VERSION ""

NS_ :

BS_:

BU_: New_Node_2 ADCC_DA_J6P_M32T

BO_ 871 ADS_BNCM_1: 24 ADCC_DA_J6P_M32T
 SG_ ADS_1_CRC1 : 7|8@0+ (1,0) [0|255] "" Vector__XXX
 SG_ ADS_1_RollgCntr1 : 11|4@0+ (1,0) [0|14] "" Vector__XXX
 SG_ ADS_1_Resd1 : 15|4@0+ (1,0) [0|15] "" Vector__XXX
 SG_ ADS_Chanllenge1 : 23|8@0+ (1,0) [0|255] "" Vector__XXX
 SG_ ADS_Chanllenge2 : 31|8@0+ (1,0) [0|255] "" Vector__XXX
 SG_ ADS_ParkingActiveSubFuncSts : 34|3@0+ (1,0) [0|7] "" Vector__XXX
 SG_ ADS_RPAIntFunSts : 35|1@0+ (1,0) [0|1] "" Vector__XXX
 SG_ RPAOutFunSts : 36|1@0+ (1,0) [0|1] "" Vector__XXX
 SG_ RpaStartButSts : 37|1@0+ (1,0) [0|1] "" Vector__XXX
 SG_ ADAS_enum_ApaRpaSts : 43|4@0+ (1,0) [0|15] "" Vector__XXX
 SG_ ADAS_enum_ParkingQuitInd : 54|7@0+ (1,0) [0|127] "" Vector__XXX
 SG_ ADAS_enum_ParkingDriOperateInd : 62|7@0+ (1,0) [0|127] "" Vector__XXX
 SG_ ADS_1_CRC2 : 71|8@0+ (1,0) [0|255] "" Vector__XXX
 SG_ ADS_1_RollgCntr2 : 75|4@0+ (1,0) [0|14] "" Vector__XXX
 SG_ ADS_1_Resd2 : 79|4@0+ (1,0) [0|15] "" Vector__XXX
 SG_ ADAS_enum_ParkingPauseInd : 84|5@0+ (1,0) [0|31] "" Vector__XXX
 SG_ PrkInSts : 85|1@0+ (1,0) [0|1] "" Vector__XXX
 SG_ FrontLeftOutsts : 86|1@0+ (1,0) [0|1] "" Vector__XXX
 SG_ FrontRightOutsts : 87|1@0+ (1,0) [0|1] "" Vector__XXX
 SG_ FrontStrightOutsts : 88|1@0+ (1,0) [0|1] "" Vector__XXX
 SG_ BackLeftOutsts : 89|1@0+ (1,0) [0|1] "" Vector__XXX
 SG_ BackRightOutsts : 90|1@0+ (1,0) [0|1] "" Vector__XXX
 SG_ BackStrightOutsts : 91|1@0+ (1,0) [0|1] "" Vector__XXX
 SG_ FrontLeftParallelOutsts : 92|1@0+ (1,0) [0|1] "" Vector__XXX
 SG_ FrontRightParallelOutsts : 93|1@0+ (1,0) [0|1] "" Vector__XXX
 SG_ ParkingStopDist : 103|10@0+ (0.1,0) [0|102.3] "m" Vector__XXX
 SG_ ParkingCompleteTime : 109|10@0+ (1,0) [0|1023] "s" Vector__XXX
 SG_ ParkOutDirectionSt : 115|4@0+ (1,0) [0|15] "" Vector__XXX
 SG_ ADS_1_CRC3 : 135|8@0+ (1,0) [0|255] "" Vector__XXX
 SG_ ADS_1_RollgCntr3 : 139|4@0+ (1,0) [0|14] "" Vector__XXX
 SG_ ADS_1_Resd3 : 143|4@0+ (1,0) [0|15] "" Vector__XXX
 SG_ ADS_ParkingRemind : 159|3@0+ (1,0) [0|7] "" Vector__XXX
 SG_ HPARPAInFunSts : 151|2@0+ (1,0) [0|3] "" Vector__XXX
 SG_ HPARPAOutFunSts : 155|2@0+ (1,0) [0|3] "" Vector__XXX
 SG_ BAFAFunSts : 153|2@0+ (1,0) [0|3] "" Vector__XXX
 SG_ RpaResumeButSts : 167|2@0+ (1,0) [0|3] "" Vector__XXX
 SG_ ADS_1_BAFAFrontButSts : 165|2@0+ (1,0) [0|3] "" Vector__XXX
 SG_ ADS_1_BAFABacktButSts : 163|2@0+ (1,0) [0|3] "" Vector__XXX
 SG_ ADS_1_SelfCheckSt : 161|2@0+ (1,0) [0|3] "" Vector__XXX
 SG_ ADS_1_RPASet : 175|2@0+ (1,0) [0|3] "" Vector__XXX
 SG_ ADS_1_SlotType : 173|2@0+ (1,0) [0|3] "" Vector__XXX
 SG_ ADS_1_ActivateEcall : 171|2@0+ (1,0) [0|3] "" Vector__XXX
 SG_ ADS_1_ParkingProgressBarInd : 183|7@0+ (1,0) [0|100] "" Vector__XXX

BO_ 901 ADS_ASU_1: 32 ADCC_DA_J6P_M32T
 SG_ ADS_CRC1 : 7|8@0+ (1,0) [0|255] "" Vector__XXX
 SG_ ADS_RollgCntr1 : 11|4@0+ (1,0) [0|14] "" Vector__XXX
 SG_ ADS_Resd1 : 15|4@0+ (1,0) [0|15] "" Vector__XXX
 SG_ ADS_Road_infor_available : 23|1@0+ (1,0) [0|1] "" Vector__XXX
 SG_ ADS_Road_Type : 22|3@0+ (1,0) [0|7] "" Vector__XXX
 SG_ ADS_Rough_Sta_L : 19|2@0+ (1,0) [0|3] "" Vector__XXX
 SG_ ADS_Road_Features_L : 31|4@0+ (1,0) [0|15] "" Vector__XXX
 SG_ ADS_LongitudinalDist_L : 43|12@0+ (0.01,0) [0|30] "m" Vector__XXX
 SG_ ADS_Rough_Sta_R : 17|2@0+ (1,0) [0|3] "" Vector__XXX
 SG_ ADS_Road_Features_R : 27|4@0+ (1,0) [0|15] "" Vector__XXX
 SG_ ADS_LongitudinalDist_R : 39|12@0+ (0.01,0) [0|30] "m" Vector__XXX
 SG_ ADS_CRC2 : 71|8@0+ (1,0) [0|255] "" Vector__XXX
 SG_ ADS_RollgCntr2 : 75|4@0+ (1,0) [0|14] "" Vector__XXX
 SG_ ADS_Resd2 : 79|4@0+ (1,0) [0|15] "" Vector__XXX
 SG_ ADS_FeatureHight_L : 87|10@0+ (0.001,-0.5) [-0.5|0.523] "m" Vector__XXX
 SG_ ADS_FeatureHight_R : 93|10@0+ (0.001,-0.5) [-0.5|0.523] "m" Vector__XXX
 SG_ SpeedBump_0_ID : 99|4@0+ (1,0) [0|15] "" Vector__XXX
 SG_ SpeedBump_0_Valid : 127|1@0+ (1,0) [0|1] "" Vector__XXX
 SG_ SpeedBump_0_Dx : 111|10@0+ (0.1,0) [0|100] "m" Vector__XXX
 SG_ SpeedBump_0_ExistProb : 117|6@0+ (2,0) [0|100] "%" Vector__XXX
 SG_ SpeedBump_1_ID : 126|4@0+ (1,0) [0|15] "" Vector__XXX
 SG_ SpeedBump_1_Valid : 122|1@0+ (1,0) [0|1] "" Vector__XXX
 SG_ ADS_CRC3 : 135|8@0+ (1,0) [0|255] "" Vector__XXX
 SG_ ADS_RollgCntr3 : 139|4@0+ (1,0) [0|14] "" Vector__XXX
 SG_ ADS_Resd3 : 143|4@0+ (1,0) [0|15] "" Vector__XXX
 SG_ SpeedBump_1_Dx : 151|10@0+ (0.1,0) [0|100] "m" Vector__XXX
 SG_ SpeedBump_1_ExistProb : 157|6@0+ (2,0) [0|100] "%" Vector__XXX
 SG_ SpeedBump_2_ID : 167|4@0+ (1,0) [0|15] "" Vector__XXX
 SG_ SpeedBump_2_Valid : 163|1@0+ (1,0) [0|1] "" Vector__XXX
 SG_ SpeedBump_2_Dx : 161|10@0+ (0.1,0) [0|100] "m" Vector__XXX
 SG_ SpeedBump_2_ExistProb : 183|6@0+ (2,0) [0|100] "%" Vector__XXX
 SG_ SpeedBump_3_ID : 191|4@0+ (1,0) [0|15] "" Vector__XXX
 SG_ SpeedBump_3_Valid : 187|1@0+ (1,0) [0|1] "" Vector__XXX
 SG_ ADS_CRC4 : 199|8@0+ (1,0) [0|255] "" Vector__XXX
 SG_ ADS_RollgCntr4 : 203|4@0+ (1,0) [0|14] "" Vector__XXX
 SG_ ADS_Resd4 : 207|4@0+ (1,0) [0|15] "" Vector__XXX
 SG_ SpeedBump_3_Dx : 215|10@0+ (0.1,0) [0|100] "m" Vector__XXX
 SG_ SpeedBump_3_ExistProb : 221|6@0+ (2,0) [0|100] "%" Vector__XXX
 SG_ SpeedBump_4_ID : 231|4@0+ (1,0) [0|15] "" Vector__XXX
 SG_ SpeedBump_4_Valid : 227|1@0+ (1,0) [0|1] "" Vector__XXX
 SG_ SpeedBump_4_Dx : 225|10@0+ (0.1,0) [0|100] "m" Vector__XXX
 SG_ SpeedBump_4_ExistProb : 247|6@0+ (2,0) [0|100] "%" Vector__XXX

BO_ 1301 ADCC_TimeSync: 8 ADCC_DA_J6P_M32T
 SG_ TimeSync_Type M : 7|8@0+ (1,0) [0|255] "" Vector__XXX
 SG_ TimeSync_CRC : 15|8@0+ (1,0) [0|255] "" Vector__XXX
 SG_ TimeSync_SequenceCounter : 19|4@0+ (1,0) [0|15] "" Vector__XXX
 SG_ TimeSync_TimeDomain : 23|4@0+ (1,0) [0|15] "" Vector__XXX
 SG_ TimeSync_UserByte0 m32 : 31|8@0+ (1,0) [0|255] "" Vector__XXX
 SG_ TimeSync_SyncTimeSec m32 : 39|32@0+ (1,0) [0|4294967295] "" Vector__XXX
 SG_ TimeSync_OverflowOfSeconds m40 : 25|2@0+ (1,0) [0|3] "" Vector__XXX
 SG_ TimeSync_SGW m40 : 26|1@0+ (1,0) [0|1] "" Vector__XXX
 SG_ TimeSync_Reserved0 m40 : 31|5@0+ (1,0) [0|31] "" Vector__XXX
 SG_ TimeSync_SyncTimeNSec m40 : 39|32@0+ (1,0) [0|4294967295] "" Vector__XXX

BO_ 783 ADS_COM_1: 8 ADCC_DA_J6P_M32T
 SG_ ADS_1_CRC1 : 7|8@0+ (1,0) [0|255] "" Vector__XXX
 SG_ ADS_1_RollgCntr1 : 11|4@0+ (1,0) [0|14] "" Vector__XXX
 SG_ ADS_1_Resd1 : 15|4@0+ (1,0) [0|15] "" Vector__XXX
 SG_ ADS_1_FunctionSuppressReq : 23|2@0+ (1,0) [0|3] "" Vector__XXX
 SG_ ADS_1_HPASts : 27|4@0+ (1,0) [0|15] "" Vector__XXX
 SG_ ADS_1_VPASts : 31|4@0+ (1,0) [0|15] "" Vector__XXX
 SG_ ADCC_CameraStreamSts : 18|3@0+ (1,0) [0|7] "" Vector__XXX
 SG_ ADCC_CameraErrorCode : 21|3@0+ (1,0) [0|7] "" Vector__XXX
 SG_ ADCC_HWRequest : 32|1@0+ (1,0) [0|1] "" Vector__XXX
 SG_ ADCC_PP_M_Request : 33|1@0+ (1,0) [0|1] "" Vector__XXX
 SG_ ADCC_HighwayZoneState : 39|2@0+ (1,0) [0|3] "" Vector__XXX
 SG_ ADCC_CoolingReq : 42|3@0+ (1,0) [0|7] "" Vector__XXX
 SG_ ADCC_UploadFlag : 34|1@0+ (1,0) [0|1] "" Vector__XXX
 SG_ ADCC_SurroundCameraErrorSts : 55|8@0+ (1,0) [0|255] "" Vector__XXX
 SG_ ADCC_SysReadySts : 43|1@0+ (1,0) [0|1] "" Vector__XXX
 SG_ ADS_1_APARPASts : 47|4@0+ (1,0) [0|15] "" Vector__XXX
 SG_ ADCC_OvertemperatureErrorSts : 63|2@0+ (1,0) [0|3] "" Vector__XXX
 SG_ ADCC_CamFOV_HeatReq : 61|3@0+ (1,0) [0|7] "" Vector__XXX

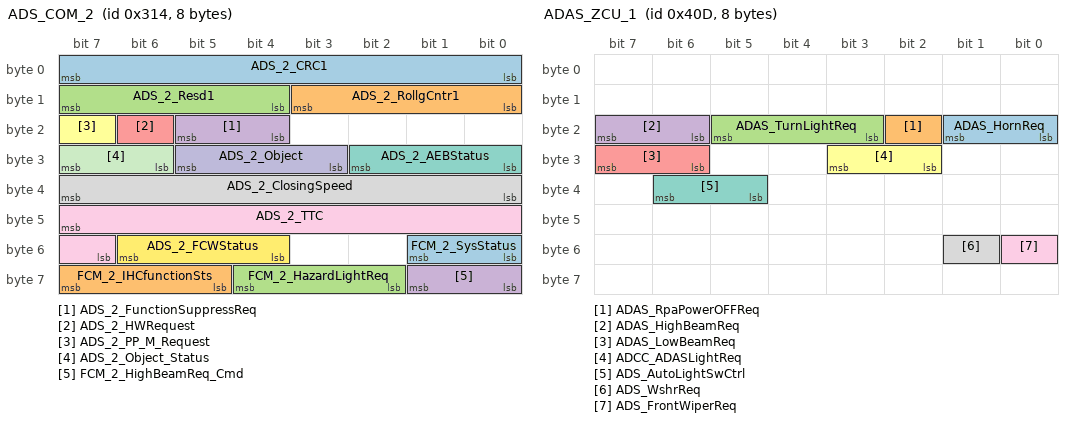
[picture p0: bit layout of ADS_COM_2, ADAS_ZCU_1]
BO_ 788 ADS_COM_2: 8 ADCC_DA_J6P_M32T
 SG_ ADS_2_CRC1 : 7|8@0+ (1,0) [0|255] "" Vector__XXX
 SG_ ADS_2_RollgCntr1 : 11|4@0+ (1,0) [0|14] "" Vector__XXX
 SG_ ADS_2_Resd1 : 15|4@0+ (1,0) [0|15] "" Vector__XXX
 SG_ ADS_2_FunctionSuppressReq : 21|2@0+ (1,0) [0|3] "" Vector__XXX
 SG_ ADS_2_HWRequest : 22|1@0+ (1,0) [0|1] "" Vector__XXX
 SG_ ADS_2_PP_M_Request : 23|1@0+ (1,0) [0|1] "" Vector__XXX
 SG_ ADS_2_AEBStatus : 26|3@0+ (1,0) [0|5] "" Vector__XXX
 SG_ ADS_2_ClosingSpeed : 39|8@0+ (1,0) [0|250] "kph" Vector__XXX
 SG_ ADS_2_TTC : 47|9@0+ (0.01,0) [0|5] "s" Vector__XXX
 SG_ ADS_2_Object : 29|3@0+ (1,0) [0|7] "" Vector__XXX
 SG_ ADS_2_Object_Status : 31|2@0+ (1,0) [0|3] "" Vector__XXX
 SG_ ADS_2_FCWStatus : 54|3@0+ (1,0) [0|7] "" Vector__XXX
 SG_ FCM_2_SysStatus : 49|2@0+ (1,0) [0|3] "" Vector__XXX
 SG_ FCM_2_IHCfunctionSts : 63|3@0+ (1,0) [0|7] "" Vector__XXX
 SG_ FCM_2_HazardLightReq : 60|3@0+ (1,0) [0|7] "" Vector__XXX
 SG_ FCM_2_HighBeamReq_Cmd : 57|2@0+ (1,0) [0|3] "" Vector__XXX

BO_ 794 ADS_COM_3: 24 ADCC_DA_J6P_M32T
 SG_ ADS_3_CRC1 : 7|8@0+ (1,0) [0|255] "" Vector__XXX
 SG_ ADS_3_RollgCntr1 : 11|4@0+ (1,0) [0|14] "" Vector__XXX
 SG_ ADS_3_Resd1 : 15|4@0+ (1,0) [0|15] "" Vector__XXX
 SG_ ADS_3_ICAStatus : 23|3@0+ (1,0) [0|7] "" Vector__XXX
 SG_ ADS_3_ICATextinfo : 19|4@0+ (1,0) [0|15] "" Vector__XXX
 SG_ ADS_3_ACCSts : 31|4@0+ (1,0) [0|15] "" Vector__XXX
 SG_ ADS_3_DriverHandsoffWarning : 27|3@0+ (1,0) [0|7] "" Vector__XXX
 SG_ ADS_3_AESStatus : 39|3@0+ (1,0) [0|7] "" Vector__XXX
 SG_ ADS_3_LKSMod : 36|2@0+ (1,0) [0|3] "" Vector__XXX
 SG_ ADS_3_LKSSts : 34|3@0+ (1,0) [0|7] "" Vector__XXX
 SG_ ADS_3_ELKSts : 47|3@0+ (1,0) [0|7] "" Vector__XXX
 SG_ ADS_3_LKSLeftTrackingSt : 44|2@0+ (1,0) [0|2] "" Vector__XXX
 SG_ ADS_3_LKSRightTrackingSt : 42|2@0+ (1,0) [0|2] "" Vector__XXX
 SG_ ADS_3_ELKLeftActiveSt : 55|2@0+ (1,0) [0|2] "" Vector__XXX
 SG_ ADS_3_ELKRightActiveSt : 53|2@0+ (1,0) [0|2] "" Vector__XXX
 SG_ ADS_3_RearViewFoldReq : 51|2@0+ (1,0) [0|3] "" Vector__XXX
 SG_ ADS_3_CRC2 : 71|8@0+ (1,0) [0|255] "" Vector__XXX
 SG_ ADS_3_RollgCntr2 : 75|4@0+ (1,0) [0|14] "" Vector__XXX
 SG_ ADS_3_Resd2 : 79|4@0+ (1,0) [0|15] "" Vector__XXX
 SG_ ADS_ALCSts : 87|4@0+ (1,0) [0|15] "" Vector__XXX
 SG_ ADS_HNOPSts : 83|4@0+ (1,0) [0|15] "" Vector__XXX
 SG_ ADS_UNOPSts : 95|4@0+ (1,0) [0|15] "" Vector__XXX
 SG_ ADAS_ParkingActiveSubFuncSt : 91|4@0+ (1,0) [0|15] "" Vector__XXX
 SG_ ADS_DoorLockReq : 103|2@0+ (1,0) [0|3] "" Vector__XXX
 SG_ ADASLighSwtSts : 107|2@0+ (1,0) [0|3] "" Vector__XXX
 SG_ ADCCFlowReq : 119|8@0+ (0.1,0) [0|25.5] "L/min" Vector__XXX

BO_ 1037 ADAS_ZCU_1: 8 ADCC_DA_J6P_M32T
 SG_ ADAS_HornReq : 17|2@0+ (1,0) [0|3] "" Vector__XXX
 SG_ ADAS_RpaPowerOFFReq : 18|1@0+ (1,0) [0|1] "" Vector__XXX
 SG_ ADAS_TurnLightReq : 21|3@0+ (1,0) [0|7] "" Vector__XXX
 SG_ ADAS_HighBeamReq : 23|2@0+ (1,0) [0|3] "" Vector__XXX
 SG_ ADAS_LowBeamReq : 31|2@0+ (1,0) [0|3] "" Vector__XXX
 SG_ ADCC_ADASLightReq : 27|2@0+ (1,0) [0|3] "" Vector__XXX
 SG_ ADS_AutoLightSwCtrl : 38|2@0+ (1,0) [0|3] "" Vector__XXX
 SG_ ADS_WshrReq : 49|1@0+ (1,0) [0|1] "" Vector__XXX
 SG_ ADS_FrontWiperReq : 48|1@0+ (1,0) [0|1] "" Vector__XXX

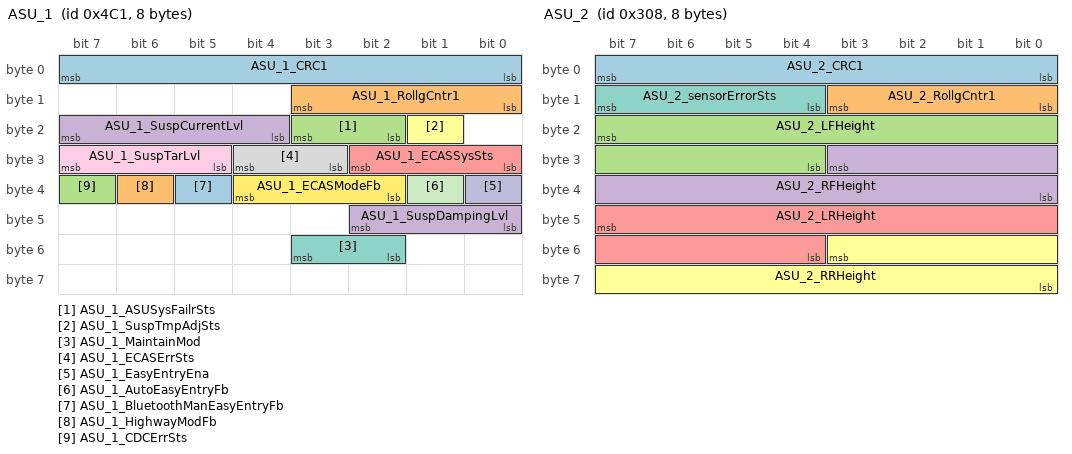
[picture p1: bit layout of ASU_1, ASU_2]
BO_ 1217 ASU_1: 8 Vector__XXX
 SG_ ASU_1_CRC1 : 7|8@0+ (1,0) [0|255] ""  ADCC_DA_J6P_M32T
 SG_ ASU_1_RollgCntr1 : 11|4@0+ (1,0) [0|14] ""  ADCC_DA_J6P_M32T
 SG_ ASU_1_ASUSysFailrSts : 19|2@0+ (1,0) [0|3] ""  ADCC_DA_J6P_M32T
 SG_ ASU_1_SuspCurrentLvl : 23|4@0+ (1,0) [0|15] ""  ADCC_DA_J6P_M32T
 SG_ ASU_1_ECASSysSts : 26|3@0+ (1,0) [0|7] ""  ADCC_DA_J6P_M32T
 SG_ ASU_1_SuspTmpAdjSts : 17|1@0+ (1,0) [0|1] ""  ADCC_DA_J6P_M32T
 SG_ ASU_1_MaintainMod : 51|2@0+ (1,0) [0|3] ""  ADCC_DA_J6P_M32T
 SG_ ASU_1_ECASErrSts : 28|2@0+ (1,0) [0|3] ""  ADCC_DA_J6P_M32T
 SG_ ASU_1_SuspTarLvl : 31|3@0+ (1,0) [0|7] ""  ADCC_DA_J6P_M32T
 SG_ ASU_1_EasyEntryEna : 32|1@0+ (1,0) [0|1] ""  ADCC_DA_J6P_M32T
 SG_ ASU_1_AutoEasyEntryFb : 33|1@0+ (1,0) [0|1] ""  ADCC_DA_J6P_M32T
 SG_ ASU_1_ECASModeFb : 36|3@0+ (1,0) [0|7] ""  ADCC_DA_J6P_M32T
 SG_ ASU_1_BluetoothManEasyEntryFb : 37|1@0+ (1,0) [0|1] ""  ADCC_DA_J6P_M32T
 SG_ ASU_1_HighwayModFb : 38|1@0+ (1,0) [0|1] ""  ADCC_DA_J6P_M32T
 SG_ ASU_1_CDCErrSts : 39|1@0+ (1,0) [0|1] ""  ADCC_DA_J6P_M32T
 SG_ ASU_1_SuspDampingLvl : 42|3@0+ (1,0) [0|7] ""  ADCC_DA_J6P_M32T

BO_ 776 ASU_2: 8 Vector__XXX
 SG_ ASU_2_CRC1 : 7|8@0+ (1,0) [0|255] ""  ADCC_DA_J6P_M32T
 SG_ ASU_2_RollgCntr1 : 11|4@0+ (1,0) [0|14] ""  ADCC_DA_J6P_M32T
 SG_ ASU_2_LFHeight : 23|12@0+ (0.1,-150) [0|259.4] "mm"  ADCC_DA_J6P_M32T
 SG_ ASU_2_RFHeight : 27|12@0+ (0.1,-150) [0|259.4] "mm"  ADCC_DA_J6P_M32T
 SG_ ASU_2_LRHeight : 47|12@0+ (0.1,-150) [0|259.4] "mm"  ADCC_DA_J6P_M32T
 SG_ ASU_2_RRHeight : 51|12@0+ (0.1,-150) [0|259.4] "mm"  ADCC_DA_J6P_M32T
 SG_ ASU_2_sensorErrorSts : 15|4@0+ (1,0) [0|15] ""  ADCC_DA_J6P_M32T

BO_ 1291 BMS_2_G: 8 Vector__XXX
 SG_ BMS_SOCLight : 62|7@0+ (1,0) [0|100] "%"  ADCC_DA_J6P_M32T

BO_ 1295 BMS_3_G: 8 Vector__XXX
 SG_ BMS_ChgWireConnect_LightSts : 32|1@0+ (1,0) [0|1] ""  ADCC_DA_J6P_M32T
 SG_ BMS_Chg_LightSts : 33|1@0+ (1,0) [0|1] ""  ADCC_DA_J6P_M32T

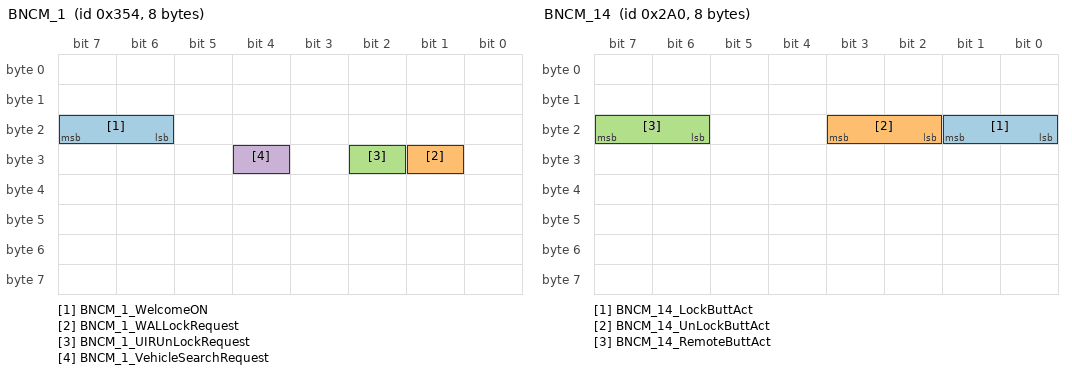
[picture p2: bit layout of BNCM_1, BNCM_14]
BO_ 852 BNCM_1: 8 Vector__XXX
 SG_ BNCM_1_WelcomeON : 23|2@0+ (1,0) [0|3] ""  ADCC_DA_J6P_M32T
 SG_ BNCM_1_WALLockRequest : 25|1@0+ (1,0) [0|1] ""  ADCC_DA_J6P_M32T
 SG_ BNCM_1_UIRUnLockRequest : 26|1@0+ (1,0) [0|1] ""  ADCC_DA_J6P_M32T
 SG_ BNCM_1_VehicleSearchRequest : 28|1@0+ (1,0) [0|1] ""  ADCC_DA_J6P_M32T

BO_ 879 BNCM_4: 16 New_Node_2
 SG_ BNCM_4_CRC1 : 7|8@0+ (1,0) [0|255] ""  ADCC_DA_J6P_M32T
 SG_ BNCM_4_RollgCntr1 : 11|4@0+ (1,0) [0|14] ""  ADCC_DA_J6P_M32T
 SG_ BNCM_4_Resd1 : 15|4@0+ (1,0) [0|15] ""  ADCC_DA_J6P_M32T
 SG_ BNCM_4_ChallengeFeedback : 23|8@0+ (1,0) [0|255] ""  ADCC_DA_J6P_M32T
 SG_ BNCM_4_RpaDevicefailSts : 26|3@0+ (1,0) [0|7] ""  ADCC_DA_J6P_M32T
 SG_ BNCM_4_RpaModReq : 29|1@0+ (1,0) [0|1] ""  ADCC_DA_J6P_M32T
 SG_ BNCM_4_ExitAndPowerOff : 28|2@0+ (1,0) [0|3] ""  ADCC_DA_J6P_M32T
 SG_ BNCM_4_RpaModselect : 34|3@0+ (1,0) [0|7] ""  ADCC_DA_J6P_M32T
 SG_ BNCM_4_RpaBtnSts : 35|1@0+ (1,0) [0|1] ""  ADCC_DA_J6P_M32T
 SG_ BNCM_4_StraightInBtnSts : 36|1@0+ (1,0) [0|1] ""  ADCC_DA_J6P_M32T
 SG_ BNCM_4_StraightOutBtnSts : 37|1@0+ (1,0) [0|1] ""  ADCC_DA_J6P_M32T
 SG_ BNCM_4_RpaBtnCancelSts : 38|1@0+ (1,0) [0|1] ""  ADCC_DA_J6P_M32T
 SG_ BNCM_4_PrkOutModSelRmt : 43|4@0+ (1,0) [0|15] ""  ADCC_DA_J6P_M32T
 SG_ BNCM_4_HeartbeatSignal : 45|1@0+ (1,0) [0|1] ""  ADCC_DA_J6P_M32T
 SG_ BNCM_4_PauseBtn : 47|2@0+ (1,0) [0|3] ""  ADCC_DA_J6P_M32T
 SG_ BNCM_4_ResumeBtn : 63|2@0+ (1,0) [0|3] ""  ADCC_DA_J6P_M32T
 SG_ BNCM_4_RpaDeviceDisSts : 81|2@0+ (1,0) [0|3] ""  ADCC_DA_J6P_M32T
 SG_ BNCM_4_BLEConnSts : 83|2@0+ (1,0) [0|3] ""  ADCC_DA_J6P_M32T
 SG_ BNCM_4_BLEErrStatus : 84|1@0+ (1,0) [0|1] ""  ADCC_DA_J6P_M32T

BO_ 1191 BNCM_6: 8 Vector__XXX
 SG_ BNCM_6_RemoteControl : 4|5@0+ (1,0) [0|31] ""  ADCC_DA_J6P_M32T

BO_ 672 BNCM_14: 8 Vector__XXX
 SG_ BNCM_14_LockButtAct : 17|2@0+ (1,0) [0|3] ""  ADCC_DA_J6P_M32T
 SG_ BNCM_14_UnLockButtAct : 19|2@0+ (1,0) [0|3] ""  ADCC_DA_J6P_M32T
 SG_ BNCM_14_RemoteButtAct : 23|2@0+ (1,0) [0|3] ""  ADCC_DA_J6P_M32T

BO_ 1143 CDU_2: 8 Vector__XXX
 SG_ DCDC_WorkingMode : 31|4@0+ (1,0) [0|15] ""  ADCC_DA_J6P_M32T
 SG_ OBC_CC_ConnectSts : 27|3@0+ (1,0) [0|7] ""  ADCC_DA_J6P_M32T

BO_ 1172 TMS_1: 8 Vector__XXX
 SG_ ExternalTemperature_C : 39|8@0+ (0.5,-40) [-40|85] "°C"  ADCC_DA_J6P_M32T
 SG_ ExternalTemperatureFailSts : 40|1@0+ (1,0) [0|1] ""  ADCC_DA_J6P_M32T

BO_ 1188 TMS_3: 32 Vector__XXX
 SG_ TMS_IncarTemp : 87|8@0+ (0.5,-40) [-40|85] "°C"  ADCC_DA_J6P_M32T

BO_ 884 TMS_4: 64 Vector__XXX
 SG_ WPump3Duty : 303|8@0+ (0.4,0) [0|100] "%"  ADCC_DA_J6P_M32T

BO_ 1138 TMS_6: 64 Vector__XXX
 SG_ SysRefLoopFault : 263|16@0+ (1,0) [0|500] ""  ADCC_DA_J6P_M32T

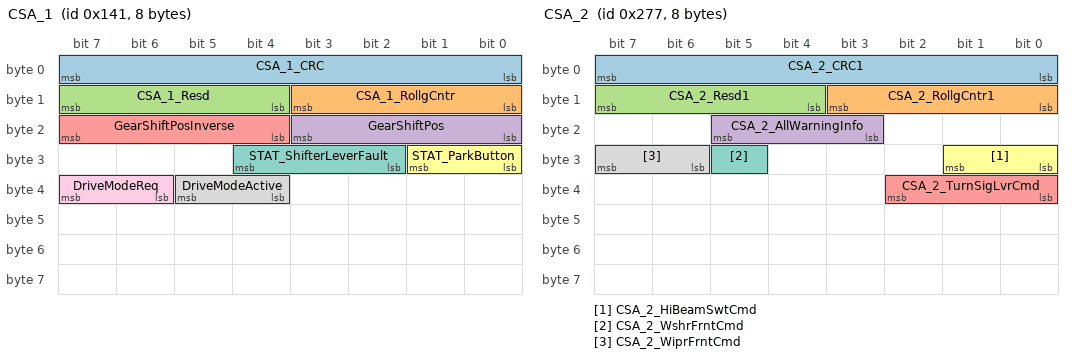
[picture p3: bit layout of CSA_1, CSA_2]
BO_ 321 CSA_1: 8 Vector__XXX
 SG_ CSA_1_CRC : 7|8@0+ (1,0) [0|255] ""  ADCC_DA_J6P_M32T
 SG_ CSA_1_RollgCntr : 11|4@0+ (1,0) [0|14] ""  ADCC_DA_J6P_M32T
 SG_ CSA_1_Resd : 15|4@0+ (1,0) [0|15] ""  ADCC_DA_J6P_M32T
 SG_ GearShiftPos : 19|4@0+ (1,0) [0|15] ""  ADCC_DA_J6P_M32T
 SG_ GearShiftPosInverse : 23|4@0+ (1,0) [0|15] ""  ADCC_DA_J6P_M32T
 SG_ STAT_ParkButton : 25|2@0+ (1,0) [0|3] ""  ADCC_DA_J6P_M32T
 SG_ STAT_ShifterLeverFault : 28|3@0+ (1,0) [0|7] ""  ADCC_DA_J6P_M32T
 SG_ DriveModeActive : 37|2@0+ (1,0) [0|3] ""  ADCC_DA_J6P_M32T
 SG_ DriveModeReq : 39|2@0+ (1,0) [0|3] ""  ADCC_DA_J6P_M32T

BO_ 631 CSA_2: 8 Vector__XXX
 SG_ CSA_2_CRC1 : 7|8@0+ (1,0) [0|255] ""  ADCC_DA_J6P_M32T
 SG_ CSA_2_RollgCntr1 : 11|4@0+ (1,0) [0|14] ""  ADCC_DA_J6P_M32T
 SG_ CSA_2_Resd1 : 15|4@0+ (1,0) [0|15] ""  ADCC_DA_J6P_M32T
 SG_ CSA_2_AllWarningInfo : 21|3@0+ (1,0) [0|7] ""  ADCC_DA_J6P_M32T
 SG_ CSA_2_TurnSigLvrCmd : 34|3@0+ (1,0) [0|7] ""  ADCC_DA_J6P_M32T
 SG_ CSA_2_HiBeamSwtCmd : 25|2@0+ (1,0) [0|3] ""  ADCC_DA_J6P_M32T
 SG_ CSA_2_WshrFrntCmd : 29|1@0+ (1,0) [0|1] ""  ADCC_DA_J6P_M32T
 SG_ CSA_2_WiprFrntCmd : 31|2@0+ (1,0) [0|3] ""  ADCC_DA_J6P_M32T

BO_ 967 FRM_2: 64 Vector__XXX
 SG_ FRM_2_CRC : 7|16@0+ (1,0) [0|65535] ""  ADCC_DA_J6P_M32T
 SG_ FRM_2_RollgCntr : 23|8@0+ (1,0) [0|255] ""  ADCC_DA_J6P_M32T
 SG_ FRM_2_DetnHd_DetnBlockCounter : 31|4@0+ (1,0) [0|15] ""  ADCC_DA_J6P_M32T
 SG_ FRM_2_DetnHd_MountPosX : 27|10@0+ (0.01,0) [0|10] "m"  ADCC_DA_J6P_M32T
 SG_ FRM_2_DetnHd_MountPosY : 33|9@0+ (0.01,-2.5) [-2.5|2.5] "m"  ADCC_DA_J6P_M32T
 SG_ FRM_2_DetnHd_MountPosZ : 40|9@0+ (0.01,0) [0|5] "m"  ADCC_DA_J6P_M32T
 SG_ FRM_2_DetnHd_MountAngleYaw : 63|9@0+ (0.1,-15) [-15|15] "deg"  ADCC_DA_J6P_M32T
 SG_ FRM_2_DetnHd_MountAnglePitch : 70|9@0+ (0.1,-15) [-15|15] "deg"  ADCC_DA_J6P_M32T
 SG_ FRM_2_DetnHd_MountAngleRoll : 77|9@0+ (0.1,-15) [-15|15] "deg"  ADCC_DA_J6P_M32T
 SG_ FRM_2_DetnHd_AlignAglYawErrCurr : 84|9@0+ (0.1,-15) [-15|15] "deg"  ADCC_DA_J6P_M32T
 SG_ FRM_2_DetnHd_AlignAglYawErrEOL : 91|9@0+ (0.1,-15) [-15|15] "deg"  ADCC_DA_J6P_M32T
 SG_ FRM_2_DetnHd_AlignAglPitchErrEOL : 98|9@0+ (0.1,-15) [-15|15] "deg"  ADCC_DA_J6P_M32T
 SG_ FRM_2_DetnHd_FOVYawAglLower : 105|11@0+ (0.1,-90) [-90|90] "deg"  ADCC_DA_J6P_M32T
 SG_ FRM_2_DetnHd_FOVYawAglUpper : 126|11@0+ (0.1,-90) [-90|90] "deg"  ADCC_DA_J6P_M32T
 SG_ FRM_2_DetnHd_FOVPitchAglLower : 131|10@0+ (0.1,-40) [-40|40] "deg"  ADCC_DA_J6P_M32T
 SG_ FRM_2_DetnHd_FOVPitchAglUpper : 137|10@0+ (0.1,-40) [-40|40] "deg"  ADCC_DA_J6P_M32T
 SG_ FRM_2_DetnHd_MaxDetectionRange : 159|8@0+ (1,0) [0|200] "m"  ADCC_DA_J6P_M32T
 SG_ FRM_2_DetnHd_HWFail : 160|1@0+ (1,0) [0|1] ""  ADCC_DA_J6P_M32T
 SG_ FRM_2_DetnHd_Misalignment : 161|1@0+ (1,0) [0|1] ""  ADCC_DA_J6P_M32T
 SG_ FRM_2_DetnHd_AlignmentNotDone : 162|1@0+ (1,0) [0|1] ""  ADCC_DA_J6P_M32T
 SG_ FRM_2_DetnHd_SensorBlockage : 163|1@0+ (1,0) [0|1] ""  ADCC_DA_J6P_M32T
 SG_ FRM_2_DetnHd_ObjDetFail : 164|1@0+ (1,0) [0|1] ""  ADCC_DA_J6P_M32T
 SG_ FRM_2_DetnHd_OutOfVoltage : 165|1@0+ (1,0) [0|1] ""  ADCC_DA_J6P_M32T
 SG_ FRM_2_DetnHd_OverTemperature : 166|1@0+ (1,0) [0|1] ""  ADCC_DA_J6P_M32T
 SG_ FRM_2_DetnHd_ReceivedCANTimeOut : 167|1@0+ (1,0) [0|1] ""  ADCC_DA_J6P_M32T
 SG_ FRM_2_DetnHd_ReceivedCANInvalid : 168|1@0+ (1,0) [0|1] ""  ADCC_DA_J6P_M32T
 SG_ FRM_2_DetnHd_RFBoardWorkingSts : 169|1@0+ (1,0) [0|1] ""  ADCC_DA_J6P_M32T
 SG_ FRM_2_DetnHd_ValidDetnCount : 255|8@0+ (1,0) [0|200] ""  ADCC_DA_J6P_M32T
 SG_ FRM_2_DetnHd_DetnDownSel : 183|1@0+ (1,0) [0|1] ""  ADCC_DA_J6P_M32T
 SG_ FRM_2_DetnHd_DetnTimeStamp : 191|42@0+ (1,0) [0|4398046511103] "ms"  ADCC_DA_J6P_M32T
 SG_ FRM_2_DetnHd_DetnTimeStampSts : 229|5@0+ (1,0) [0|31] ""  ADCC_DA_J6P_M32T
 SG_ FRM_2_DetnHd_DetnTimeLatency : 224|9@0+ (1,0) [0|511] "ms"  ADCC_DA_J6P_M32T
 SG_ FRM_2_DetnHd_NotConfigured : 246|1@0+ (1,0) [0|1] ""  ADCC_DA_J6P_M32T
 SG_ FRM_2_DetnHd_ParameterInvalid : 247|1@0+ (1,0) [0|1] ""  ADCC_DA_J6P_M32T

BO_ 571 FLZCU_1: 8 Vector__XXX
 SG_ FLZCU_1_CRC : 7|8@0+ (1,0) [0|255] ""  ADCC_DA_J6P_M32T
 SG_ FLZCU_1_RollgCntr : 11|4@0+ (1,0) [0|14] ""  ADCC_DA_J6P_M32T
 SG_ FLZCU_1_Resd : 15|4@0+ (1,0) [0|15] ""  ADCC_DA_J6P_M32T
 SG_ HoodLockSts : 17|2@0+ (1,0) [0|3] ""  ADCC_DA_J6P_M32T
 SG_ DrvSeatOccupiedSts : 21|1@0+ (1,0) [0|1] ""  ADCC_DA_J6P_M32T
 SG_ LHTurnlightSts : 19|1@0+ (1,0) [0|1] ""  ADCC_DA_J6P_M32T
 SG_ RHTurnlightSts : 20|1@0+ (1,0) [0|1] ""  ADCC_DA_J6P_M32T
 SG_ HoodSts : 30|2@0+ (1,0) [0|3] ""  ADCC_DA_J6P_M32T
 SG_ DrvDoorLockSts : 25|2@0+ (1,0) [0|3] ""  ADCC_DA_J6P_M32T
 SG_ DrvDoorSts : 23|2@0+ (1,0) [0|3] ""  ADCC_DA_J6P_M32T
 SG_ LHTurnSW : 26|1@0+ (1,0) [0|1] ""  ADCC_DA_J6P_M32T
 SG_ RHTurnSW : 27|1@0+ (1,0) [0|1] ""  ADCC_DA_J6P_M32T
 SG_ HazardLightSW : 28|1@0+ (1,0) [0|1] ""  ADCC_DA_J6P_M32T
 SG_ DrvSeatBeltSW : 31|1@0+ (1,0) [0|1] ""  ADCC_DA_J6P_M32T
 SG_ DirectionIndLeft : 43|1@0+ (1,0) [0|1] ""  ADCC_DA_J6P_M32T
 SG_ DirectionIndRight : 44|1@0+ (1,0) [0|1] ""  ADCC_DA_J6P_M32T
 SG_ DrvSeatBeltFaultStatus : 61|1@0+ (1,0) [0|1] ""  ADCC_DA_J6P_M32T

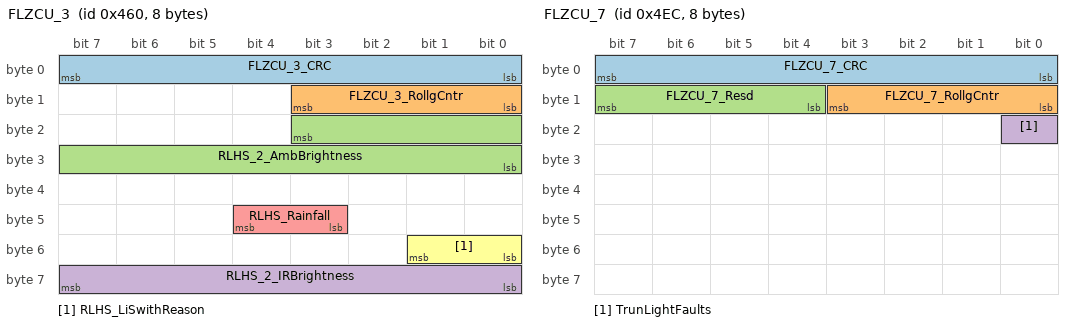
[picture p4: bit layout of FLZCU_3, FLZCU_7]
BO_ 1120 FLZCU_3: 8 Vector__XXX
 SG_ FLZCU_3_CRC : 7|8@0+ (1,0) [0|255] ""  ADCC_DA_J6P_M32T
 SG_ FLZCU_3_RollgCntr : 11|4@0+ (1,0) [0|14] ""  ADCC_DA_J6P_M32T
 SG_ RLHS_2_AmbBrightness : 19|12@0+ (20,0) [0|81880] "Lux"  ADCC_DA_J6P_M32T
 SG_ RLHS_2_IRBrightness : 63|8@0+ (400,0) [0|101600] "Lux"  ADCC_DA_J6P_M32T
 SG_ RLHS_Rainfall : 44|2@0+ (1,0) [0|3] ""  ADCC_DA_J6P_M32T
 SG_ RLHS_LiSwithReason : 49|2@0+ (1,0) [0|3] ""  ADCC_DA_J6P_M32T

BO_ 1260 FLZCU_7: 8 Vector__XXX
 SG_ FLZCU_7_CRC : 7|8@0+ (1,0) [0|255] ""  ADCC_DA_J6P_M32T
 SG_ FLZCU_7_RollgCntr : 11|4@0+ (1,0) [0|14] ""  ADCC_DA_J6P_M32T
 SG_ FLZCU_7_Resd : 15|4@0+ (1,0) [0|15] ""  ADCC_DA_J6P_M32T
 SG_ TrunLightFaults : 16|1@0+ (1,0) [0|1] ""  ADCC_DA_J6P_M32T

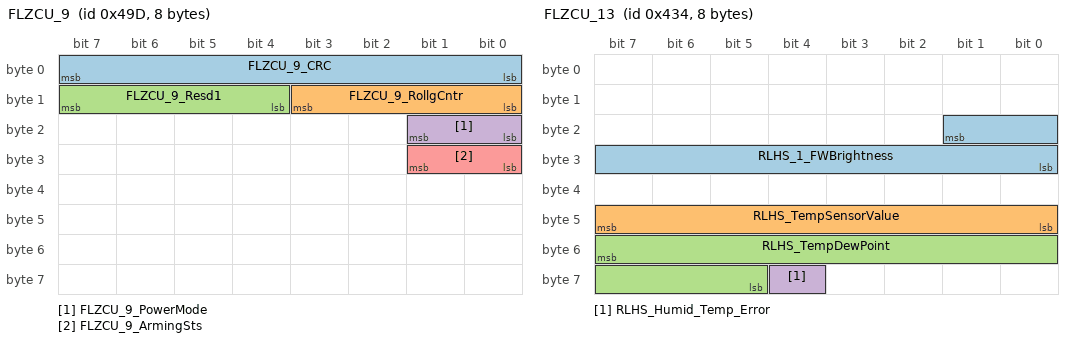
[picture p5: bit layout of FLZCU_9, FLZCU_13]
BO_ 1181 FLZCU_9: 8 Vector__XXX
 SG_ FLZCU_9_CRC : 7|8@0+ (1,0) [0|255] ""  ADCC_DA_J6P_M32T
 SG_ FLZCU_9_RollgCntr : 11|4@0+ (1,0) [0|14] ""  ADCC_DA_J6P_M32T
 SG_ FLZCU_9_Resd1 : 15|4@0+ (1,0) [0|15] ""  ADCC_DA_J6P_M32T
 SG_ FLZCU_9_PowerMode : 17|2@0+ (1,0) [0|3] ""  ADCC_DA_J6P_M32T
 SG_ FLZCU_9_ArmingSts : 25|2@0+ (1,0) [0|3] ""  ADCC_DA_J6P_M32T

BO_ 843 FLZCU_10: 8 Vector__XXX
 SG_ HOD_CRC : 7|8@0+ (1,0) [0|255] ""  ADCC_DA_J6P_M32T
 SG_ HOD_RollingCounter : 11|4@0+ (1,0) [0|14] ""  ADCC_DA_J6P_M32T
 SG_ HOD_Resd1 : 15|4@0+ (1,0) [0|15] ""  ADCC_DA_J6P_M32T
 SG_ HOD_OnOffSts : 16|1@0+ (1,0) [0|1] ""  ADCC_DA_J6P_M32T
 SG_ HOD_OnOffStsValid : 17|1@0+ (1,0) [0|1] ""  ADCC_DA_J6P_M32T
 SG_ HOD_HandOnSts : 19|2@0+ (1,0) [0|3] ""  ADCC_DA_J6P_M32T
 SG_ HOD_OneHand_Area : 21|2@0+ (1,0) [0|3] ""  ADCC_DA_J6P_M32T
 SG_ HOD_OneHand_AreaValid : 22|1@0+ (1,0) [0|1] ""  ADCC_DA_J6P_M32T
 SG_ HOD_LeftArea_Sts : 25|2@0+ (1,0) [0|3] ""  ADCC_DA_J6P_M32T
 SG_ HOD_LeftArea_StsVD : 26|1@0+ (1,0) [0|1] ""  ADCC_DA_J6P_M32T
 SG_ HOD_RightArea_Sts : 28|2@0+ (1,0) [0|3] ""  ADCC_DA_J6P_M32T
 SG_ HOD_RightArea_StsVD : 29|1@0+ (1,0) [0|1] ""  ADCC_DA_J6P_M32T
 SG_ HOD_FC_CAP_SENSOR_ERR : 30|1@0+ (1,0) [0|1] ""  ADCC_DA_J6P_M32T
 SG_ HOD_FC_ECU_HW_Fault : 31|1@0+ (1,0) [0|1] ""  ADCC_DA_J6P_M32T
 SG_ HOD_FC_BAT_LOW : 32|1@0+ (1,0) [0|1] ""  ADCC_DA_J6P_M32T
 SG_ HOD_FC_BAT_HIGH : 33|1@0+ (1,0) [0|1] ""  ADCC_DA_J6P_M32T
 SG_ HOD_FC_ResponseError : 34|1@0+ (1,0) [0|1] ""  ADCC_DA_J6P_M32T
 SG_ HOD_FC_SYSTEM_ERR : 35|1@0+ (1,0) [0|1] ""  ADCC_DA_J6P_M32T

BO_ 1030 FLZCU_12: 16 Vector__XXX
 SG_ FLZCU_12_CRC : 7|8@0+ (1,0) [0|255] ""  ADCC_DA_J6P_M32T
 SG_ FLZCU_12_RollgCntr : 11|4@0+ (1,0) [0|14] ""  ADCC_DA_J6P_M32T
 SG_ FLZCU_FrontWiperParkStatus : 24|1@0+ (1,0) [0|1] ""  ADCC_DA_J6P_M32T
 SG_ FLZCU_FrontWiperWipingStatus : 31|2@0+ (1,0) [0|3] ""  ADCC_DA_J6P_M32T
 SG_ RearViewFoldSts : 58|2@0+ (1,0) [0|3] ""  ADCC_DA_J6P_M32T

BO_ 1076 FLZCU_13: 8 Vector__XXX
 SG_ RLHS_1_FWBrightness : 17|10@0+ (6,0) [0|6126] "Lux"  ADCC_DA_J6P_M32T
 SG_ RLHS_TempSensorValue : 47|8@0+ (0.5,-40) [-39.5|87] "℃"  ADCC_DA_J6P_M32T
 SG_ RLHS_TempDewPoint : 55|11@0+ (0.1,-39.6) [-39.5|60.4] "℃"  ADCC_DA_J6P_M32T
 SG_ RLHS_Humid_Temp_Error : 60|1@0+ (1,0) [0|1] ""  ADCC_DA_J6P_M32T

BO_ 1071 FLZCU_15: 48 Vector__XXX
 SG_ FLZCU_LightMainSwitchSts : 44|3@0+ (1,0) [0|7] ""  ADCC_DA_J6P_M32T
 SG_ FLZCU_FLFoglightSts : 87|1@0+ (1,0) [0|1] ""  ADCC_DA_J6P_M32T
 SG_ FLZCU_FRFoglightSts : 86|1@0+ (1,0) [0|1] ""  ADCC_DA_J6P_M32T
 SG_ FLZCU_RearFogLightSts : 85|1@0+ (1,0) [0|1] ""  ADCC_DA_J6P_M32T
 SG_ FLZCU_LowBeamSts : 91|1@0+ (1,0) [0|1] ""  ADCC_DA_J6P_M32T
 SG_ FLZCU_HighBeamSts : 90|1@0+ (1,0) [0|1] ""  ADCC_DA_J6P_M32T
 SG_ FLZCU_HighBeamFaults : 89|1@0+ (1,0) [0|1] ""  ADCC_DA_J6P_M32T
 SG_ FLZCU_RearFogLightFaults : 88|1@0+ (1,0) [0|1] ""  ADCC_DA_J6P_M32T
 SG_ FLZCU_ParkLightFaults : 103|1@0+ (1,0) [0|1] ""  ADCC_DA_J6P_M32T
 SG_ FLZCU_DaytimeLight : 101|2@0+ (1,0) [0|3] ""  ADCC_DA_J6P_M32T
 SG_ FLZCU_HMASwSts : 99|1@0+ (1,0) [0|1] ""  ADCC_DA_J6P_M32T
 SG_ FLZCU_BrkLightSts : 115|2@0+ (1,0) [0|3] ""  ADCC_DA_J6P_M32T
 SG_ FLZCU_FrontFogLightSts : 124|1@0+ (1,0) [0|1] ""  ADCC_DA_J6P_M32T
 SG_ FLZCU_CamFOV_HeatSts : 339|2@0+ (1,0) [0|3] ""  ADCC_DA_J6P_M32T
 SG_ ADASLightStsFb : 357|2@0+ (1,0) [0|3] ""  ADCC_DA_J6P_M32T
 SG_ ADSLightFaildSts : 355|2@0+ (1,0) [0|3] ""  ADCC_DA_J6P_M32T

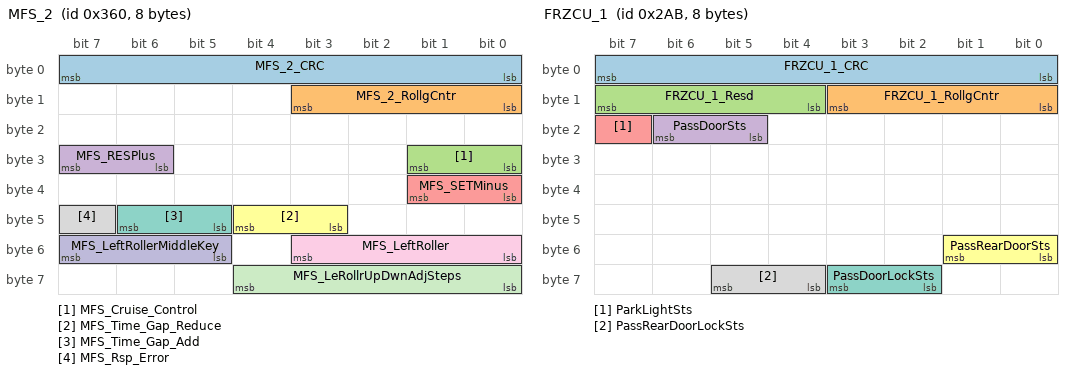
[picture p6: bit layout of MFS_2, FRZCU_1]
BO_ 864 MFS_2: 8 Vector__XXX
 SG_ MFS_2_CRC : 7|8@0+ (1,0) [0|255] ""  ADCC_DA_J6P_M32T
 SG_ MFS_2_RollgCntr : 11|4@0+ (1,0) [0|14] ""  ADCC_DA_J6P_M32T
 SG_ MFS_Cruise_Control : 25|2@0+ (1,0) [0|3] ""  ADCC_DA_J6P_M32T
 SG_ MFS_RESPlus : 31|2@0+ (1,0) [0|3] ""  ADCC_DA_J6P_M32T
 SG_ MFS_SETMinus : 33|2@0+ (1,0) [0|3] ""  ADCC_DA_J6P_M32T
 SG_ MFS_Time_Gap_Reduce : 44|2@0+ (1,0) [0|3] ""  ADCC_DA_J6P_M32T
 SG_ MFS_Time_Gap_Add : 46|2@0+ (1,0) [0|3] ""  ADCC_DA_J6P_M32T
 SG_ MFS_Rsp_Error : 47|1@0+ (1,0) [0|1] ""  ADCC_DA_J6P_M32T
 SG_ MFS_LeftRoller : 51|4@0+ (1,0) [0|15] ""  ADCC_DA_J6P_M32T
 SG_ MFS_LeftRollerMiddleKey : 55|3@0+ (1,0) [0|7] ""  ADCC_DA_J6P_M32T
 SG_ MFS_LeRollrUpDwnAdjSteps : 60|5@0+ (1,0) [0|31] ""  ADCC_DA_J6P_M32T

BO_ 683 FRZCU_1: 8 Vector__XXX
 SG_ FRZCU_1_CRC : 7|8@0+ (1,0) [0|255] ""  ADCC_DA_J6P_M32T
 SG_ FRZCU_1_RollgCntr : 11|4@0+ (1,0) [0|14] ""  ADCC_DA_J6P_M32T
 SG_ FRZCU_1_Resd : 15|4@0+ (1,0) [0|15] ""  ADCC_DA_J6P_M32T
 SG_ PassDoorSts : 22|2@0+ (1,0) [0|3] ""  ADCC_DA_J6P_M32T
 SG_ ParkLightSts : 23|1@0+ (1,0) [0|1] ""  ADCC_DA_J6P_M32T
 SG_ PassRearDoorSts : 49|2@0+ (1,0) [0|3] ""  ADCC_DA_J6P_M32T
 SG_ PassDoorLockSts : 59|2@0+ (1,0) [0|3] ""  ADCC_DA_J6P_M32T
 SG_ PassRearDoorLockSts : 61|2@0+ (1,0) [0|3] ""  ADCC_DA_J6P_M32T

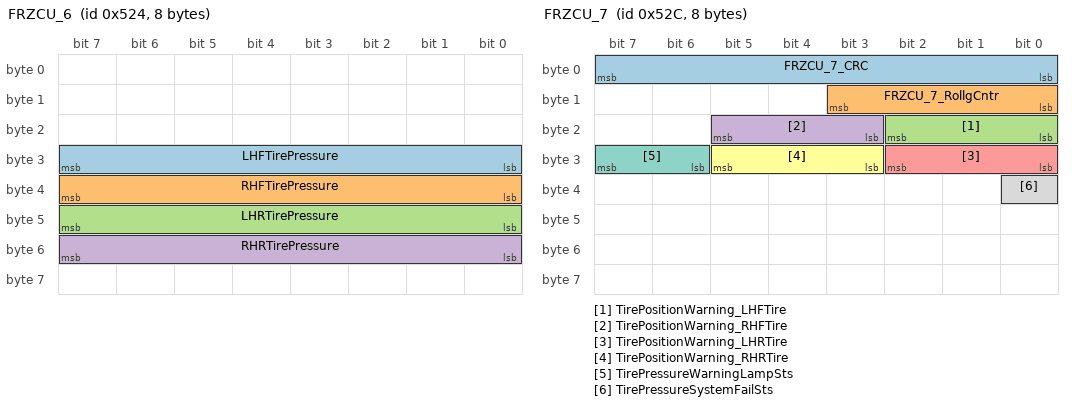
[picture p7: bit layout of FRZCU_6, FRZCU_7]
BO_ 1316 FRZCU_6: 8 Vector__XXX
 SG_ LHFTirePressure : 31|8@0+ (1.373,0) [0|350] "kPa"  ADCC_DA_J6P_M32T
 SG_ RHFTirePressure : 39|8@0+ (1.373,0) [0|350] "kPa"  ADCC_DA_J6P_M32T
 SG_ LHRTirePressure : 47|8@0+ (1.373,0) [0|350] "kPa"  ADCC_DA_J6P_M32T
 SG_ RHRTirePressure : 55|8@0+ (1.373,0) [0|350] "kPa"  ADCC_DA_J6P_M32T

BO_ 1324 FRZCU_7: 8 Vector__XXX
 SG_ FRZCU_7_CRC : 7|8@0+ (1,0) [0|255] ""  ADCC_DA_J6P_M32T
 SG_ FRZCU_7_RollgCntr : 11|4@0+ (1,0) [0|14] ""  ADCC_DA_J6P_M32T
 SG_ TirePositionWarning_LHFTire : 18|3@0+ (1,0) [0|7] ""  ADCC_DA_J6P_M32T
 SG_ TirePositionWarning_RHFTire : 21|3@0+ (1,0) [0|7] ""  ADCC_DA_J6P_M32T
 SG_ TirePositionWarning_LHRTire : 26|3@0+ (1,0) [0|7] ""  ADCC_DA_J6P_M32T
 SG_ TirePositionWarning_RHRTire : 29|3@0+ (1,0) [0|7] ""  ADCC_DA_J6P_M32T
 SG_ TirePressureWarningLampSts : 31|2@0+ (1,0) [0|3] ""  ADCC_DA_J6P_M32T
 SG_ TirePressureSystemFailSts : 32|1@0+ (1,0) [0|1] ""  ADCC_DA_J6P_M32T

BO_ 1256 FRZCU_8: 8 Vector__XXX
 SG_ LowBeamFaults : 16|1@0+ (1,0) [0|1] ""  ADCC_DA_J6P_M32T

BO_ 638 FRZCU_9: 16 Vector__XXX
 SG_ DrvHandleSwitchSts : 57|2@0+ (1,0) [0|3] ""  ADCC_DA_J6P_M32T
 SG_ PassHandleSwitchSts : 59|2@0+ (1,0) [0|3] ""  ADCC_DA_J6P_M32T
 SG_ PassRearHandleSwitchSts : 61|2@0+ (1,0) [0|3] ""  ADCC_DA_J6P_M32T
 SG_ DrvRearHandleSwitchSts : 63|2@0+ (1,0) [0|3] ""  ADCC_DA_J6P_M32T

BO_ 949 PEPS_1: 16 Vector__XXX
 SG_ PEPS_InformationSource : 23|2@0+ (1,0) [0|3] ""  ADCC_DA_J6P_M32T
 SG_ PEPS_OrderInformation : 21|4@0+ (1,0) [0|15] ""  ADCC_DA_J6P_M32T
 SG_ PEPS_KeySts : 27|3@0+ (1,0) [0|7] ""  ADCC_DA_J6P_M32T

BO_ 1028 PEPS_2: 16 Vector__XXX
 SG_ PEPS_WelcomeON : 17|2@0+ (1,0) [0|3] ""  ADCC_DA_J6P_M32T
 SG_ PEPS_VehicleSearchReq : 19|2@0+ (1,0) [0|3] ""  ADCC_DA_J6P_M32T
 SG_ PEPS_RKETrunkSts : 25|2@0+ (1,0) [0|3] ""  ADCC_DA_J6P_M32T
 SG_ PEPS_UIRUnLockRequest : 55|2@0+ (1,0) [0|3] ""  ADCC_DA_J6P_M32T
 SG_ PEPS_WALLockRequest : 57|2@0+ (1,0) [0|3] ""  ADCC_DA_J6P_M32T

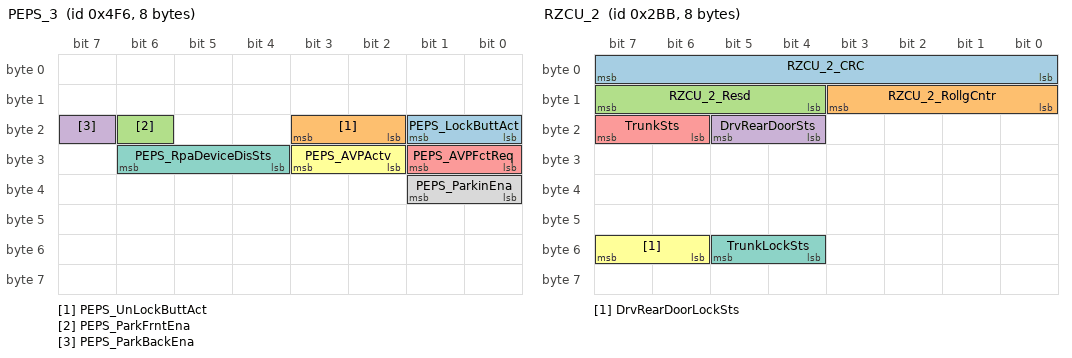
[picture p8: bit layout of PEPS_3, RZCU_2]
BO_ 1270 PEPS_3: 8 Vector__XXX
 SG_ PEPS_LockButtAct : 17|2@0+ (1,0) [0|3] ""  ADCC_DA_J6P_M32T
 SG_ PEPS_UnLockButtAct : 19|2@0+ (1,0) [0|3] ""  ADCC_DA_J6P_M32T
 SG_ PEPS_ParkFrntEna : 22|1@0+ (1,0) [0|1] ""  ADCC_DA_J6P_M32T
 SG_ PEPS_ParkBackEna : 23|1@0+ (1,0) [0|1] ""  ADCC_DA_J6P_M32T
 SG_ PEPS_AVPFctReq : 25|2@0+ (1,0) [0|3] ""  ADCC_DA_J6P_M32T
 SG_ PEPS_AVPActv : 27|2@0+ (1,0) [0|3] ""  ADCC_DA_J6P_M32T
 SG_ PEPS_RpaDeviceDisSts : 30|3@0+ (1,0) [0|7] ""  ADCC_DA_J6P_M32T
 SG_ PEPS_ParkinEna : 33|2@0+ (1,0) [0|3] ""  ADCC_DA_J6P_M32T

BO_ 699 RZCU_2: 8 Vector__XXX
 SG_ RZCU_2_CRC : 7|8@0+ (1,0) [0|255] ""  ADCC_DA_J6P_M32T
 SG_ RZCU_2_RollgCntr : 11|4@0+ (1,0) [0|14] ""  ADCC_DA_J6P_M32T
 SG_ RZCU_2_Resd : 15|4@0+ (1,0) [0|15] ""  ADCC_DA_J6P_M32T
 SG_ DrvRearDoorSts : 21|2@0+ (1,0) [0|3] ""  ADCC_DA_J6P_M32T
 SG_ TrunkSts : 23|2@0+ (1,0) [0|3] ""  ADCC_DA_J6P_M32T
 SG_ DrvRearDoorLockSts : 55|2@0+ (1,0) [0|3] ""  ADCC_DA_J6P_M32T
 SG_ TrunkLockSts : 53|2@0+ (1,0) [0|3] ""  ADCC_DA_J6P_M32T

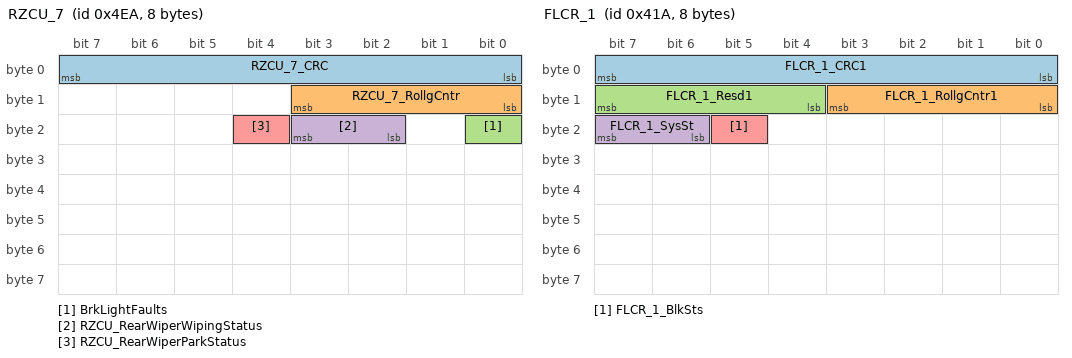
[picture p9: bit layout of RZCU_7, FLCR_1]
BO_ 1258 RZCU_7: 8 Vector__XXX
 SG_ RZCU_7_CRC : 7|8@0+ (1,0) [0|255] ""  ADCC_DA_J6P_M32T
 SG_ RZCU_7_RollgCntr : 11|4@0+ (1,0) [0|14] ""  ADCC_DA_J6P_M32T
 SG_ BrkLightFaults : 16|1@0+ (1,0) [0|1] ""  ADCC_DA_J6P_M32T
 SG_ RZCU_RearWiperWipingStatus : 19|2@0+ (1,0) [0|3] ""  ADCC_DA_J6P_M32T
 SG_ RZCU_RearWiperParkStatus : 20|1@0+ (1,0) [0|1] ""  ADCC_DA_J6P_M32T

BO_ 1050 FLCR_1: 8 Vector__XXX
 SG_ FLCR_1_CRC1 : 7|8@0+ (1,0) [0|255] ""  ADCC_DA_J6P_M32T
 SG_ FLCR_1_RollgCntr1 : 11|4@0+ (1,0) [0|14] ""  ADCC_DA_J6P_M32T
 SG_ FLCR_1_Resd1 : 15|4@0+ (1,0) [0|15] ""  ADCC_DA_J6P_M32T
 SG_ FLCR_1_SysSt : 23|2@0+ (1,0) [0|3] ""  ADCC_DA_J6P_M32T
 SG_ FLCR_1_BlkSts : 21|1@0+ (1,0) [0|1] ""  ADCC_DA_J6P_M32T

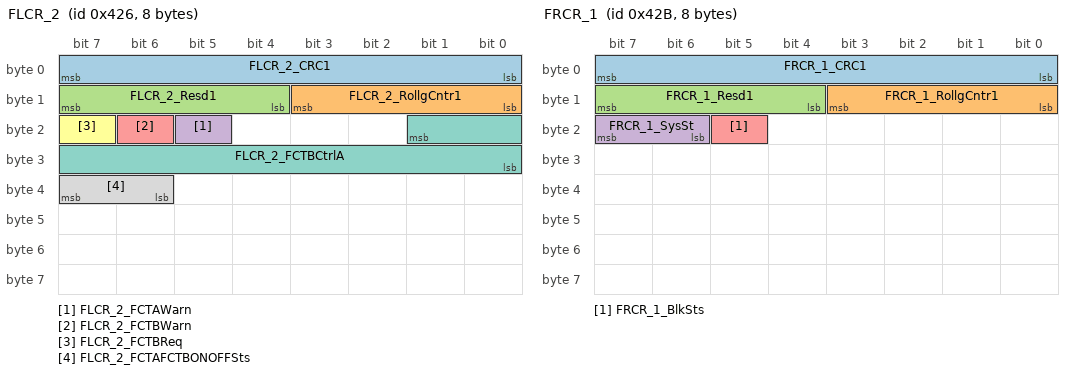
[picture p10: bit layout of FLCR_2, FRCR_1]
BO_ 1062 FLCR_2: 8 Vector__XXX
 SG_ FLCR_2_CRC1 : 7|8@0+ (1,0) [0|255] ""  ADCC_DA_J6P_M32T
 SG_ FLCR_2_RollgCntr1 : 11|4@0+ (1,0) [0|14] ""  ADCC_DA_J6P_M32T
 SG_ FLCR_2_Resd1 : 15|4@0+ (1,0) [0|15] ""  ADCC_DA_J6P_M32T
 SG_ FLCR_2_FCTAWarn : 21|1@0+ (1,0) [0|1] ""  ADCC_DA_J6P_M32T
 SG_ FLCR_2_FCTBWarn : 22|1@0+ (1,0) [0|1] ""  ADCC_DA_J6P_M32T
 SG_ FLCR_2_FCTBReq : 23|1@0+ (1,0) [0|1] ""  ADCC_DA_J6P_M32T
 SG_ FLCR_2_FCTBCtrlA : 17|10@0+ (0.01,-10.22) [-10.22|0] "m/s2"  ADCC_DA_J6P_M32T
 SG_ FLCR_2_FCTAFCTBONOFFSts : 39|2@0+ (1,0) [0|3] ""  ADCC_DA_J6P_M32T

BO_ 1067 FRCR_1: 8 Vector__XXX
 SG_ FRCR_1_CRC1 : 7|8@0+ (1,0) [0|255] ""  ADCC_DA_J6P_M32T
 SG_ FRCR_1_RollgCntr1 : 11|4@0+ (1,0) [0|14] ""  ADCC_DA_J6P_M32T
 SG_ FRCR_1_Resd1 : 15|4@0+ (1,0) [0|15] ""  ADCC_DA_J6P_M32T
 SG_ FRCR_1_SysSt : 23|2@0+ (1,0) [0|3] ""  ADCC_DA_J6P_M32T
 SG_ FRCR_1_BlkSts : 21|1@0+ (1,0) [0|1] ""  ADCC_DA_J6P_M32T

BO_ 1077 FRCR_2: 8 Vector__XXX
 SG_ FRCR_2_FCTAWarn : 21|1@0+ (1,0) [0|1] ""  ADCC_DA_J6P_M32T
 SG_ FRCR_2_FCTBWarn : 22|1@0+ (1,0) [0|1] ""  ADCC_DA_J6P_M32T

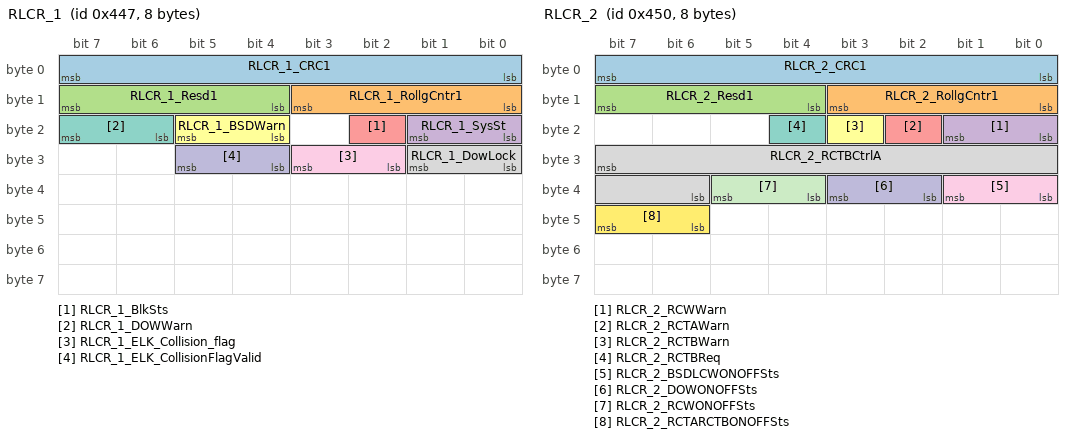
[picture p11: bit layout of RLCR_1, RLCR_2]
BO_ 1095 RLCR_1: 8 ADCC_DA_J6P_M32T
 SG_ RLCR_1_CRC1 : 7|8@0+ (1,0) [0|255] "" Vector__XXX
 SG_ RLCR_1_RollgCntr1 : 11|4@0+ (1,0) [0|14] "" Vector__XXX
 SG_ RLCR_1_Resd1 : 15|4@0+ (1,0) [0|15] "" Vector__XXX
 SG_ RLCR_1_SysSt : 17|2@0+ (1,0) [0|3] "" Vector__XXX
 SG_ RLCR_1_BlkSts : 18|1@0+ (1,0) [0|1] "" Vector__XXX
 SG_ RLCR_1_BSDWarn : 21|2@0+ (1,0) [0|3] "" Vector__XXX
 SG_ RLCR_1_DOWWarn : 23|2@0+ (1,0) [0|3] "" Vector__XXX
 SG_ RLCR_1_DowLock : 25|2@0+ (1,0) [0|3] "" Vector__XXX
 SG_ RLCR_1_ELK_Collision_flag : 27|2@0+ (1,0) [0|3] "" Vector__XXX
 SG_ RLCR_1_ELK_CollisionFlagValid : 29|2@0+ (1,0) [0|3] "" Vector__XXX

BO_ 1104 RLCR_2: 8 ADCC_DA_J6P_M32T
 SG_ RLCR_2_CRC1 : 7|8@0+ (1,0) [0|255] "" Vector__XXX
 SG_ RLCR_2_RollgCntr1 : 11|4@0+ (1,0) [0|14] "" Vector__XXX
 SG_ RLCR_2_Resd1 : 15|4@0+ (1,0) [0|15] "" Vector__XXX
 SG_ RLCR_2_RCWWarn : 17|2@0+ (1,0) [0|3] "" Vector__XXX
 SG_ RLCR_2_RCTAWarn : 18|1@0+ (1,0) [0|1] "" Vector__XXX
 SG_ RLCR_2_RCTBWarn : 19|1@0+ (1,0) [0|1] "" Vector__XXX
 SG_ RLCR_2_RCTBReq : 20|1@0+ (1,0) [0|1] "" Vector__XXX
 SG_ RLCR_2_RCTBCtrlA : 31|10@0+ (0.01,-10.22) [-10.22|0] "m/s2" Vector__XXX
 SG_ RLCR_2_BSDLCWONOFFSts : 33|2@0+ (1,0) [0|3] "" Vector__XXX
 SG_ RLCR_2_DOWONOFFSts : 35|2@0+ (1,0) [0|3] "" Vector__XXX
 SG_ RLCR_2_RCWONOFFSts : 37|2@0+ (1,0) [0|3] "" Vector__XXX
 SG_ RLCR_2_RCTARCTBONOFFSts : 47|2@0+ (1,0) [0|3] "" Vector__XXX

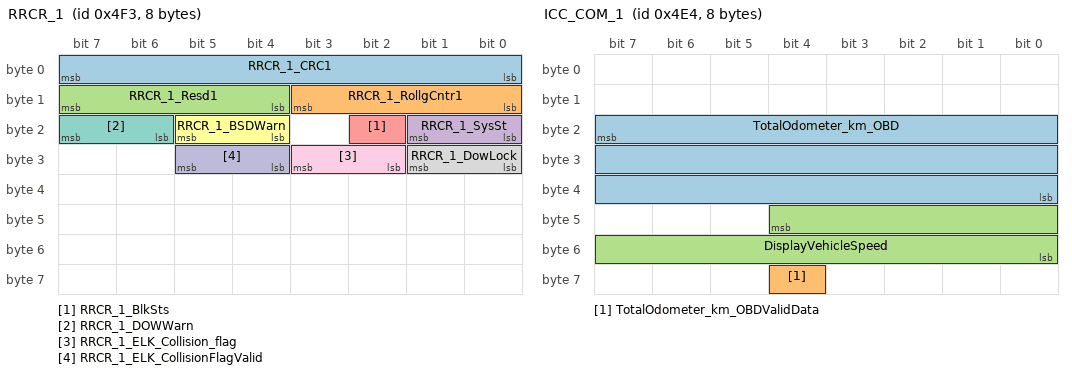
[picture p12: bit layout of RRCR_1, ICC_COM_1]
BO_ 1267 RRCR_1: 8 ADCC_DA_J6P_M32T
 SG_ RRCR_1_CRC1 : 7|8@0+ (1,0) [0|255] "" Vector__XXX
 SG_ RRCR_1_RollgCntr1 : 11|4@0+ (1,0) [0|14] "" Vector__XXX
 SG_ RRCR_1_Resd1 : 15|4@0+ (1,0) [0|15] "" Vector__XXX
 SG_ RRCR_1_SysSt : 17|2@0+ (1,0) [0|3] "" Vector__XXX
 SG_ RRCR_1_BlkSts : 18|1@0+ (1,0) [0|1] "" Vector__XXX
 SG_ RRCR_1_BSDWarn : 21|2@0+ (1,0) [0|3] "" Vector__XXX
 SG_ RRCR_1_DOWWarn : 23|2@0+ (1,0) [0|3] "" Vector__XXX
 SG_ RRCR_1_DowLock : 25|2@0+ (1,0) [0|3] "" Vector__XXX
 SG_ RRCR_1_ELK_Collision_flag : 27|2@0+ (1,0) [0|3] "" Vector__XXX
 SG_ RRCR_1_ELK_CollisionFlagValid : 29|2@0+ (1,0) [0|3] "" Vector__XXX

BO_ 1271 RRCR_2: 8 ADCC_DA_J6P_M32T
 SG_ RRCR_2_RCTAWarn : 18|1@0+ (1,0) [0|1] "" Vector__XXX
 SG_ RRCR_2_RCTBWarn : 19|1@0+ (1,0) [0|1] "" Vector__XXX

BO_ 1252 ICC_COM_1: 8 Vector__XXX
 SG_ TotalOdometer_km_OBD : 23|24@0+ (0.1,0) [0|999999.9] "km"  ADCC_DA_J6P_M32T
 SG_ TotalOdometer_km_OBDValidData : 60|1@0+ (1,0) [0|1] ""  ADCC_DA_J6P_M32T
 SG_ DisplayVehicleSpeed : 44|13@0+ (0.0625,0) [0|511.875] "km/h"  ADCC_DA_J6P_M32T

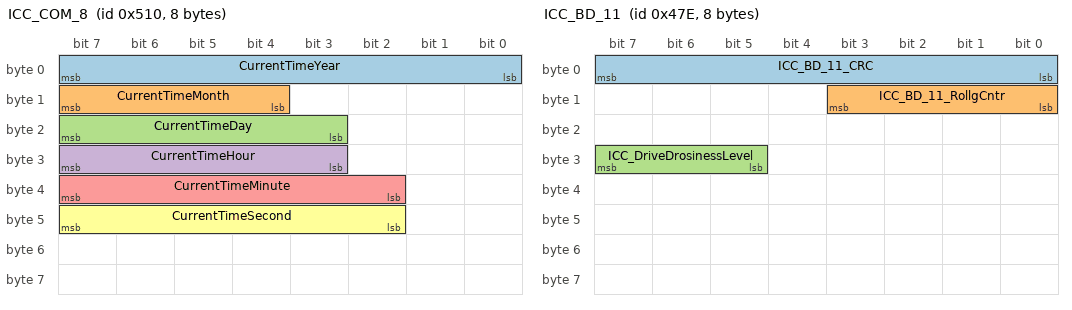
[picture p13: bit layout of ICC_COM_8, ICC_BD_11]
BO_ 1296 ICC_COM_8: 8 Vector__XXX
 SG_ CurrentTimeYear : 7|8@0+ (1,2000) [2000|2255] ""  ADCC_DA_J6P_M32T
 SG_ CurrentTimeMonth : 15|4@0+ (1,0) [1|12] ""  ADCC_DA_J6P_M32T
 SG_ CurrentTimeDay : 23|5@0+ (1,0) [1|31] ""  ADCC_DA_J6P_M32T
 SG_ CurrentTimeHour : 31|5@0+ (1,0) [0|23] ""  ADCC_DA_J6P_M32T
 SG_ CurrentTimeMinute : 39|6@0+ (1,0) [0|59] ""  ADCC_DA_J6P_M32T
 SG_ CurrentTimeSecond : 47|6@0+ (1,0) [0|59] ""  ADCC_DA_J6P_M32T

BO_ 1150 ICC_BD_11: 8 Vector__XXX
 SG_ ICC_BD_11_CRC : 7|8@0+ (1,0) [0|255] ""  ADCC_DA_J6P_M32T
 SG_ ICC_BD_11_RollgCntr : 11|4@0+ (1,0) [0|14] ""  ADCC_DA_J6P_M32T
 SG_ ICC_DriveDrosinessLevel : 31|3@0+ (1,0) [0|7] ""  ADCC_DA_J6P_M32T

BO_ 1157 ICC_DA_15: 8 Vector__XXX
 SG_ ICC_DA_15_CRC : 7|8@0+ (1,0) [0|255] ""  ADCC_DA_J6P_M32T
 SG_ ICC_DA_15_RollgCntr : 11|4@0+ (1,0) [0|14] ""  ADCC_DA_J6P_M32T
 SG_ ICC_DA_15_Resd : 15|4@0+ (1,0) [0|15] ""  ADCC_DA_J6P_M32T
 SG_ ICC_DA_15_BSDLCWSettingSt : 17|2@0+ (1,0) [0|3] ""  ADCC_DA_J6P_M32T
 SG_ ICC_DA_15_DOWSettingSt : 19|2@0+ (1,0) [0|3] ""  ADCC_DA_J6P_M32T
 SG_ ICC_DA_15_RCWSettingSt : 21|2@0+ (1,0) [0|3] ""  ADCC_DA_J6P_M32T
 SG_ ICC_DA_15_RCTARCTBWarnType : 23|2@0+ (1,0) [0|3] ""  ADCC_DA_J6P_M32T
 SG_ ICC_DA_15_FCTAFCTBWarnType : 25|2@0+ (1,0) [0|3] ""  ADCC_DA_J6P_M32T
 SG_ ICC_DA_15_FrontPDCMuteSet : 26|1@0+ (1,0) [0|1] ""  ADCC_DA_J6P_M32T
 SG_ ICC_DA_15_FKPMuteSet : 27|1@0+ (1,0) [0|1] ""  ADCC_DA_J6P_M32T
 SG_ ICC_DA_15_ExtremeEnergySaveMode : 28|1@0+ (1,0) [0|1] ""  ADCC_DA_J6P_M32T
 SG_ ICC_PDCOnOffSet : 30|2@0+ (1,0) [0|3] ""  ADCC_DA_J6P_M32T
 SG_ Driver_EyeOnRoad : 39|3@0+ (1,0) [0|7] ""  ADCC_DA_J6P_M32T
 SG_ Dms_Status : 36|3@0+ (1,0) [0|7] ""  ADCC_DA_J6P_M32T
 SG_ Driver_AbnormalBehavior : 33|2@0+ (1,0) [0|3] ""  ADCC_DA_J6P_M32T
 SG_ Driver_GazeRegion : 47|4@0+ (1,0) [0|15] ""  ADCC_DA_J6P_M32T
 SG_ Dms_DriverPresence : 43|2@0+ (1,0) [0|3] ""  ADCC_DA_J6P_M32T
 SG_ ICC_IHCfunctionSw : 41|2@0+ (1,0) [0|3] ""  ADCC_DA_J6P_M32T
 SG_ ICC_DistractionStatus : 49|2@0+ (1,0) [0|3] ""  ADCC_DA_J6P_M32T
 SG_ ICC_DA_15_BSDLCWSettingSt_AFS : 52|3@0+ (1,0) [0|7] ""  ADCC_DA_J6P_M32T
 SG_ Dms_MoutOpen : 57|2@0+ (1,0) [0|3] ""  ADCC_DA_J6P_M32T
 SG_ Dms_EyeOpen : 59|2@0+ (1,0) [0|3] ""  ADCC_DA_J6P_M32T
 SG_ Dms_EyeOccl : 61|2@0+ (1,0) [0|3] ""  ADCC_DA_J6P_M32T

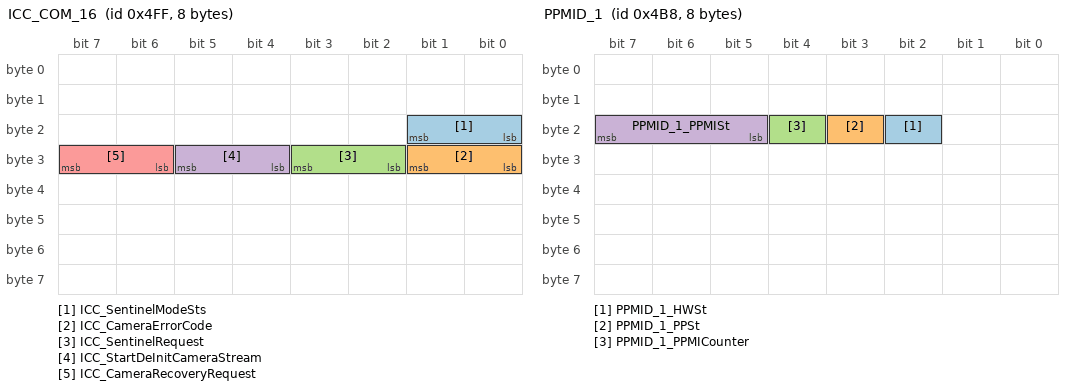
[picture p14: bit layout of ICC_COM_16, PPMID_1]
BO_ 1279 ICC_COM_16: 8 Vector__XXX
 SG_ ICC_SentinelModeSts : 17|2@0+ (1,0) [0|3] ""  ADCC_DA_J6P_M32T
 SG_ ICC_CameraErrorCode : 25|2@0+ (1,0) [0|3] ""  ADCC_DA_J6P_M32T
 SG_ ICC_SentinelRequest : 27|2@0+ (1,0) [0|3] ""  ADCC_DA_J6P_M32T
 SG_ ICC_StartDeInitCameraStream : 29|2@0+ (1,0) [0|3] ""  ADCC_DA_J6P_M32T
 SG_ ICC_CameraRecoveryRequest : 31|2@0+ (1,0) [0|3] ""  ADCC_DA_J6P_M32T

BO_ 1265 ICC_ZCU_25: 24 Vector__XXX
 SG_ OtaDwnLoad : 17|2@0+ (1,0) [0|3] ""  ADCC_DA_J6P_M32T
 SG_ ICC_LightMainSwitchSts : 39|3@0+ (1,0) [0|7] ""  ADCC_DA_J6P_M32T
 SG_ ICC_HeadlampHeightSts : 44|3@0+ (1,0) [0|7] ""  ADCC_DA_J6P_M32T

BO_ 1497 ICC_57: 32 Vector__XXX
 SG_ ADASLightSwt : 19|2@0+ (1,0) [0|3] ""  ADCC_DA_J6P_M32T

BO_ 1208 PPMID_1: 8 Vector__XXX
 SG_ PPMID_1_HWSt : 18|1@0+ (1,0) [0|1] ""  ADCC_DA_J6P_M32T
 SG_ PPMID_1_PPSt : 19|1@0+ (1,0) [0|1] ""  ADCC_DA_J6P_M32T
 SG_ PPMID_1_PPMICounter : 20|1@0+ (1,0) [0|1] ""  ADCC_DA_J6P_M32T
 SG_ PPMID_1_PPMISt : 23|3@0+ (1,0) [0|7] ""  ADCC_DA_J6P_M32T

BO_ 582 PDC_1: 64 ADCC_DA_J6P_M32T
 SG_ PDC_1_CRC1 : 7|8@0+ (1,0) [0|255] "" Vector__XXX
 SG_ PDC_1_RollgCntr1 : 11|4@0+ (1,0) [0|14] "" Vector__XXX
 SG_ PDC_1_Resd1 : 15|4@0+ (1,0) [0|15] "" Vector__XXX
 SG_ PDC_1_FOLDistance : 23|9@0+ (1,0) [0|250] "cm" Vector__XXX
 SG_ PDC_1_FOLZoneStatus : 30|4@0+ (1,0) [0|15] "" Vector__XXX
 SG_ PDC_1_FMLDistance : 26|9@0+ (1,0) [0|250] "cm" Vector__XXX
 SG_ PDC_1_FMLZoneStatus : 33|4@0+ (1,0) [0|15] "" Vector__XXX
 SG_ PDC_1_FMRDistance : 45|9@0+ (1,0) [0|250] "cm" Vector__XXX
 SG_ PDC_1_FMRZoneStatus : 52|4@0+ (1,0) [0|15] "" Vector__XXX
 SG_ PDC_1_FORDistance : 48|9@0+ (1,0) [0|250] "cm" Vector__XXX
 SG_ PDC_1_CRC2 : 71|8@0+ (1,0) [0|255] "" Vector__XXX
 SG_ PDC_1_RollgCntr2 : 75|4@0+ (1,0) [0|14] "" Vector__XXX
 SG_ PDC_1_Resd2 : 79|4@0+ (1,0) [0|15] "" Vector__XXX
 SG_ PDC_1_FORZoneStatus : 87|4@0+ (1,0) [0|15] "" Vector__XXX
 SG_ PDC_1_ROLDistance : 83|9@0+ (1,0) [0|250] "cm" Vector__XXX
 SG_ PDC_1_ROLZoneStatus : 90|4@0+ (1,0) [0|15] "" Vector__XXX
 SG_ PDC_1_RMLDistance : 102|9@0+ (1,0) [0|250] "cm" Vector__XXX
 SG_ PDC_1_RMLZoneStatus : 109|4@0+ (1,0) [0|15] "" Vector__XXX
 SG_ PDC_1_RMRDistance : 105|9@0+ (1,0) [0|250] "cm" Vector__XXX
 SG_ PDC_1_RMRZoneStatus : 112|4@0+ (1,0) [0|15] "" Vector__XXX
 SG_ PDC_1_CRC3 : 135|8@0+ (1,0) [0|255] "" Vector__XXX
 SG_ PDC_1_RollgCntr3 : 139|4@0+ (1,0) [0|14] "" Vector__XXX
 SG_ PDC_1_Resd3 : 143|4@0+ (1,0) [0|15] "" Vector__XXX
 SG_ PDC_1_RORDistance : 151|9@0+ (1,0) [0|250] "cm" Vector__XXX
 SG_ PDC_1_RORZoneStatus : 158|4@0+ (1,0) [0|15] "" Vector__XXX
 SG_ PDC_1_LSFDistance : 154|9@0+ (1,0) [0|250] "cm" Vector__XXX
 SG_ PDC_1_LSFZoneStatus : 161|4@0+ (1,0) [0|15] "" Vector__XXX
 SG_ PDC_1_FKPLSFMDistance : 173|9@0+ (1,0) [0|250] "cm" Vector__XXX
 SG_ PDC_1_FKPLSFMZoneStatus : 180|4@0+ (1,0) [0|15] "" Vector__XXX
 SG_ PDC_1_FKPLSRMDistance : 176|9@0+ (1,0) [0|250] "cm" Vector__XXX
 SG_ PDC_1_CRC4 : 199|8@0+ (1,0) [0|255] "" Vector__XXX
 SG_ PDC_1_RollgCntr4 : 203|4@0+ (1,0) [0|14] "" Vector__XXX
 SG_ PDC_1_Resd4 : 207|4@0+ (1,0) [0|15] "" Vector__XXX
 SG_ PDC_1_FKPLSRMZoneStatus : 215|4@0+ (1,0) [0|15] "" Vector__XXX
 SG_ PDC_1_LSRDistance : 211|9@0+ (1,0) [0|250] "cm" Vector__XXX
 SG_ PDC_1_LSRZoneStatus : 218|4@0+ (1,0) [0|15] "" Vector__XXX
 SG_ PDC_1_RSFDistance : 230|9@0+ (1,0) [0|250] "cm" Vector__XXX
 SG_ PDC_1_RSFZoneStatus : 237|4@0+ (1,0) [0|15] "" Vector__XXX
 SG_ PDC_1_FKPRSFMDistance : 233|9@0+ (1,0) [0|250] "cm" Vector__XXX
 SG_ PDC_1_FKPRSFMZoneStatus : 240|4@0+ (1,0) [0|15] "" Vector__XXX
 SG_ PDC_1_CRC5 : 263|8@0+ (1,0) [0|255] "" Vector__XXX
 SG_ PDC_1_RollgCntr5 : 267|4@0+ (1,0) [0|14] "" Vector__XXX
 SG_ PDC_1_Resd5 : 271|4@0+ (1,0) [0|15] "" Vector__XXX
 SG_ PDC_1_FKPRSRMDistance : 279|9@0+ (1,0) [0|250] "cm" Vector__XXX
 SG_ PDC_1_FKPRSRMZoneStatus : 286|4@0+ (1,0) [0|15] "" Vector__XXX
 SG_ PDC_1_RSRDistance : 282|9@0+ (1,0) [0|250] "cm" Vector__XXX
 SG_ PDC_1_RSRZoneStatus : 289|4@0+ (1,0) [0|15] "" Vector__XXX
 SG_ PDC_1_ParKASSStatus : 298|3@0+ (1,0) [0|7] "" Vector__XXX
 SG_ PDC_1_PASTrailerHitchDetected : 311|2@0+ (1,0) [0|3] "" Vector__XXX
 SG_ PDC_1_PDCSwFdbk : 309|1@0+ (1,0) [0|1] "" Vector__XXX
 SG_ PDC_1_FrontWarningType : 308|4@0+ (1,0) [0|15] "" Vector__XXX
 SG_ PDC_1_RearWarningType : 319|4@0+ (1,0) [0|15] "" Vector__XXX
 SG_ PDC_1_LeftSideWarningType : 359|4@0+ (1,0) [0|15] "" Vector__XXX
 SG_ PDC_1_RightSideWarningType : 355|4@0+ (1,0) [0|15] "" Vector__XXX
 SG_ PDC_1_STATRearPDCActive : 315|1@0+ (1,0) [0|1] "" Vector__XXX
 SG_ PDC_1_STATFrntPDCActive : 314|1@0+ (1,0) [0|1] "" Vector__XXX
 SG_ PDC_1_STATSidePDCActive : 313|1@0+ (1,0) [0|1] "" Vector__XXX
 SG_ PDC_1_CRC6 : 327|8@0+ (1,0) [0|255] "" Vector__XXX
 SG_ PDC_1_RollgCntr6 : 331|4@0+ (1,0) [0|14] "" Vector__XXX
 SG_ PDC_1_Resd6 : 335|4@0+ (1,0) [0|15] "" Vector__XXX
 SG_ PDC_1_STATSensorState : 343|12@0+ (1,0) [0|4095] "" Vector__XXX
 SG_ PDC_1_STATPDCHMIMode : 347|1@0+ (1,0) [0|1] "" Vector__XXX
 SG_ PDC_1_FrontPDCMuteFeedback : 346|1@0+ (1,0) [0|1] "" Vector__XXX
 SG_ PDC_1_FKPMuteFeedback : 345|1@0+ (1,0) [0|1] "" Vector__XXX
 SG_ PDC_1_TimeOutMuteRequest : 344|1@0+ (1,0) [0|1] "" Vector__XXX

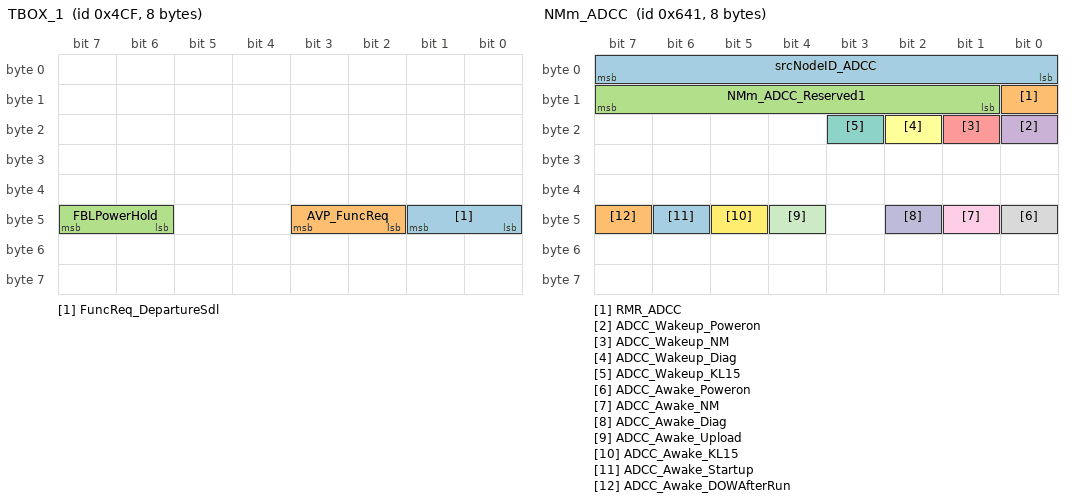
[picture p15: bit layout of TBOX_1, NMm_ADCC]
BO_ 1231 TBOX_1: 8 Vector__XXX
 SG_ FuncReq_DepartureSdl : 41|2@0+ (1,0) [0|3] ""  ADCC_DA_J6P_M32T
 SG_ AVP_FuncReq : 43|2@0+ (1,0) [0|3] ""  ADCC_DA_J6P_M32T
 SG_ FBLPowerHold : 47|2@0+ (1,0) [0|3] ""  ADCC_DA_J6P_M32T

BO_ 1199 TCM_1: 8 Vector__XXX
 SG_ TCM_1_TrailerSts : 16|1@0+ (1,0) [0|1] ""  ADCC_DA_J6P_M32T

BO_ 1184 TDU_1: 64 Vector__XXX
 SG_ TMInletWaterTemp : 39|8@0+ (0.5,-40) [-40|85] "°C"  ADCC_DA_J6P_M32T

BO_ 1207 TDU_2: 64 Vector__XXX
 SG_ WPump3Duty_FB : 87|8@0+ (0.4,0) [0|100] "%"  ADCC_DA_J6P_M32T
 SG_ WPump3FltSt : 91|4@0+ (1,0) [0|15] ""  ADCC_DA_J6P_M32T

BO_ 1035 VCC_1: 8 Vector__XXX
 SG_ VCC_1_CarMode : 31|3@0+ (1,0) [0|7] ""  ADCC_DA_J6P_M32T
 SG_ VCC_1_DriveMode : 36|5@0+ (1,0) [0|31] ""  ADCC_DA_J6P_M32T

BO_ 1075 VCC_2: 8 Vector__XXX
 SG_ VCC_2_ConfigurationMessageTrg : 23|1@0+ (1,0) [0|1] ""  ADCC_DA_J6P_M32T

BO_ 1136 VCC_3: 32 Vector__XXX
 SG_ VCC_3_CRC : 7|8@0+ (1,0) [0|255] ""  ADCC_DA_J6P_M32T
 SG_ VCC_3_RollgCntr : 11|4@0+ (1,0) [0|14] ""  ADCC_DA_J6P_M32T
 SG_ VCC_3_SN M : 23|8@0+ (1,0) [1|32] ""  ADCC_DA_J6P_M32T

BO_ 1282 ADCC_RemoteDiag: 32 ADCC_DA_J6P_M32T
 SG_ ADCC_TotalFaultNum : 7|8@0+ (1,0) [0|255] "" Vector__XXX
 SG_ ADCC_FrameIndex : 12|5@0+ (1,0) [0|31] "" Vector__XXX
 SG_ ADCC_SupplierNum : 15|3@0+ (1,0) [0|7] "" Vector__XXX
 SG_ ADCC_FaultNum1 : 23|12@0+ (1,0) [0|4095] "" Vector__XXX
 SG_ ADCC_FaultNum2 : 27|12@0+ (1,0) [0|4095] "" Vector__XXX
 SG_ ADCC_FaultNum3 : 47|12@0+ (1,0) [0|4095] "" Vector__XXX
 SG_ ADCC_FaultNum4 : 51|12@0+ (1,0) [0|4095] "" Vector__XXX
 SG_ ADCC_FaultNum5 : 71|12@0+ (1,0) [0|4095] "" Vector__XXX
 SG_ ADCC_FaultNum6 : 75|12@0+ (1,0) [0|4095] "" Vector__XXX
 SG_ ADCC_FaultNum7 : 95|12@0+ (1,0) [0|4095] "" Vector__XXX
 SG_ ADCC_FaultNum8 : 99|12@0+ (1,0) [0|4095] "" Vector__XXX
 SG_ ADCC_FaultNum9 : 119|12@0+ (1,0) [0|4095] "" Vector__XXX
 SG_ ADCC_FaultNum10 : 123|12@0+ (1,0) [0|4095] "" Vector__XXX
 SG_ ADCC_FaultNum11 : 143|12@0+ (1,0) [0|4095] "" Vector__XXX
 SG_ ADCC_FaultNum12 : 147|12@0+ (1,0) [0|4095] "" Vector__XXX
 SG_ ADCC_FaultNum13 : 167|12@0+ (1,0) [0|4095] "" Vector__XXX
 SG_ ADCC_FaultNum14 : 171|12@0+ (1,0) [0|4095] "" Vector__XXX
 SG_ ADCC_FaultNum15 : 191|12@0+ (1,0) [0|4095] "" Vector__XXX
 SG_ ADCC_FaultNum16 : 195|12@0+ (1,0) [0|4095] "" Vector__XXX
 SG_ ADCC_FaultNum17 : 215|12@0+ (1,0) [0|4095] "" Vector__XXX
 SG_ ADCC_FaultNum18 : 219|12@0+ (1,0) [0|4095] "" Vector__XXX
 SG_ ADCC_FaultNum19 : 239|12@0+ (1,0) [0|4095] "" Vector__XXX
 SG_ ADCC_FaultNum20 : 243|12@0+ (1,0) [0|4095] "" Vector__XXX

BO_ 1601 NMm_ADCC: 8 ADCC_DA_J6P_M32T
 SG_ srcNodeID_ADCC : 7|8@0+ (1,0) [0|255] "" Vector__XXX
 SG_ RMR_ADCC : 8|1@0+ (1,0) [0|1] "" Vector__XXX
 SG_ NMm_ADCC_Reserved1 : 15|7@0+ (1,0) [0|127] "" Vector__XXX
 SG_ ADCC_Wakeup_Poweron : 16|1@0+ (1,0) [0|1] "" Vector__XXX
 SG_ ADCC_Wakeup_NM : 17|1@0+ (1,0) [0|1] "" Vector__XXX
 SG_ ADCC_Wakeup_Diag : 18|1@0+ (1,0) [0|1] "" Vector__XXX
 SG_ ADCC_Wakeup_KL15 : 19|1@0+ (1,0) [0|1] "" Vector__XXX
 SG_ ADCC_Awake_Poweron : 40|1@0+ (1,0) [0|1] "" Vector__XXX
 SG_ ADCC_Awake_NM : 41|1@0+ (1,0) [0|1] "" Vector__XXX
 SG_ ADCC_Awake_Diag : 42|1@0+ (1,0) [0|1] "" Vector__XXX
 SG_ ADCC_Awake_Upload : 44|1@0+ (1,0) [0|1] "" Vector__XXX
 SG_ ADCC_Awake_KL15 : 45|1@0+ (1,0) [0|1] "" Vector__XXX
 SG_ ADCC_Awake_Startup : 46|1@0+ (1,0) [0|1] "" Vector__XXX
 SG_ ADCC_Awake_DOWAfterRun : 47|1@0+ (1,0) [0|1] "" Vector__XXX

BO_ 1975 Diag_ADCC_RES: 64 ADCC_DA_J6P_M32T
 SG_ Diag_ADCC_RES : 7|64@0+ (1,0) [0|1.84467440737096E+19] "" Vector__XXX

BO_ 1847 Diag_ADCC_REQ: 64 Vector__XXX
 SG_ Diag_ADCC_REQ : 7|64@0+ (1,0) [0|1.84467440737096E+19] ""  ADCC_DA_J6P_M32T

CM_ "Version:V3.0,Date:2024.06.05,Author:ZhengFang,Review:ZhonglingWang,Approval:JiancaiLi,Description:()Based on V3.2 of REEV(横置);
 ";
CM_ SG_ 871 ADS_1_CRC1 "Profile1A:E2E CRC (SAE J1850 CRC-8) for 8 Bytes
DataID:0x000D";
CM_ SG_ 871 ADS_1_RollgCntr1 "Profile1A:E2E Rolling message counter(the maximum value of Alive counter is 14)";
CM_ SG_ 871 ADS_1_Resd1 "Profile1A:E2E Reserved";
CM_ SG_ 871 ADS_Chanllenge1 "ADCC功能安全校验请求";
CM_ SG_ 871 ADS_Chanllenge2 "ADCC功能安全校验请求";
CM_ SG_ 871 ADS_ParkingActiveSubFuncSts "泊车功能选择状态（直入直出、巡航泊车功能暂不开发，信号预留）";
CM_ SG_ 871 ADS_RPAIntFunSts "遥控泊入功能可用状态";
CM_ SG_ 871 RPAOutFunSts "遥控泊出功能可用状态";
CM_ SG_ 871 RpaStartButSts "RPA开启开关可用状态";
CM_ SG_ 871 ADAS_enum_ApaRpaSts "Rpa功能状态
0x9:Background searching(捷途使用)";
CM_ SG_ 871 ADAS_enum_ParkingQuitInd "泊出功能退出原因(内容可调）
0x42: 摄像头脏污请清洁，泊车功能退出
0x43: 超声波脏污请清洁，泊车功能退出
0x4D: 驾驶模式切换，泊车功能退出
0x4E: 功能运行失败，泊车功能退出";
CM_ SG_ 871 ADAS_enum_ParkingDriOperateInd "驾驶员操作提示信息(内容可调）
0x19: 蓝牙距离过远
0x1A: 请切换驾驶模式";
CM_ SG_ 871 ADS_1_CRC2 "Profile1A:E2E CRC (SAE J1850 CRC-8) for 8 Bytes
DataID:0x000E";
CM_ SG_ 871 ADS_1_RollgCntr2 "Profile1A:E2E Rolling message counter(the maximum value of Alive counter is 14)";
CM_ SG_ 871 ADS_1_Resd2 "Profile1A:E2E Reserved";
CM_ SG_ 871 ADAS_enum_ParkingPauseInd "泊车暂停原因(内容可调）
0xD:Req_Recover_RemoteButtonReleased(捷途使用)
0xE:Req_Recover_Found_Side_Obstacle in Trajectory(捷途使用)
0xF:蓝牙断开，泊车暂停";
CM_ SG_ 871 PrkInSts "遥控泊入方向显示";
CM_ SG_ 871 FrontLeftOutsts "车头向左泊出可用状态";
CM_ SG_ 871 FrontRightOutsts "车头右向泊出可用状态";
CM_ SG_ 871 FrontStrightOutsts "车头直出泊出可用状态";
CM_ SG_ 871 BackLeftOutsts "车尾左向泊出可用状态";
CM_ SG_ 871 BackRightOutsts "车尾右向泊出可用状态";
CM_ SG_ 871 BackStrightOutsts "车尾直出泊出可用状态";
CM_ SG_ 871 FrontLeftParallelOutsts "车头向左水平泊出可用状态";
CM_ SG_ 871 FrontRightParallelOutsts "车头向右水平泊出可用状态";
CM_ SG_ 871 ParkingStopDist "泊车剩余距离";
CM_ SG_ 871 ParkingCompleteTime "泊车用时";
CM_ SG_ 871 ParkOutDirectionSt "泊出方向状态（实际泊出方向）";
CM_ SG_ 871 ADS_1_CRC3 "Profile1A:E2E CRC (SAE J1850 CRC-8) for 8 Bytes
DataID:0x00AF";
CM_ SG_ 871 ADS_1_RollgCntr3 "Profile1A:E2E Rolling message counter(the maximum value of Alive counter is 14)";
CM_ SG_ 871 ADS_1_Resd3 "Profile1A:E2E Reserved";
CM_ SG_ 871 ADS_ParkingRemind "离车泊入功能状态";
CM_ SG_ 871 HPARPAInFunSts "遥控记忆泊入功能可用状态";
CM_ SG_ 871 HPARPAOutFunSts "遥控记忆泊出功能可用状态";
CM_ SG_ 871 BAFAFunSts "直入直出功能可用状态";
CM_ SG_ 871 RpaResumeButSts "RPA恢复按钮可用状态";
CM_ SG_ 871 ADS_1_BAFAFrontButSts "直入按钮可用状态";
CM_ SG_ 871 ADS_1_BAFABacktButSts "直出按钮可用状态";
CM_ SG_ 871 ADS_1_SelfCheckSt "RPA自检通过状态";
CM_ SG_ 871 ADS_1_RPASet "RPA设置项";
CM_ SG_ 871 ADS_1_SlotType "车位类型";
CM_ SG_ 871 ADS_1_ActivateEcall "驾驶员无响应安全停车后，ADCC唤醒ECALL";
CM_ SG_ 871 ADS_1_ParkingProgressBarInd "泊车进度条
0-100";
CM_ SG_ 901 ADS_CRC1 "Profile1A:E2E CRC (SAE J1850 CRC-8) for 8 Bytes
DataID:No ASIL requirements.Not configure
CRC Reserved.";
CM_ SG_ 901 ADS_RollgCntr1 "Profile1A:E2E Rolling message counter(the maximum value of Alive counter is 14)";
CM_ SG_ 901 ADS_Resd1 "Profile1A:E2E Reserved";
CM_ SG_ 901 ADS_Road_infor_available "路面信息有效位";
CM_ SG_ 901 ADS_Road_Type "路面状态类型";
CM_ SG_ 901 ADS_Rough_Sta_L "左轮路面不平（凹/凸）状态";
CM_ SG_ 901 ADS_Road_Features_L "左轮单一路面特征类型";
CM_ SG_ 901 ADS_LongitudinalDist_L "左前车轮轮心在地面的投影点到路面特征区域边缘的距离";
CM_ SG_ 901 ADS_Rough_Sta_R "右轮路面不平（凹/凸）状态";
CM_ SG_ 901 ADS_Road_Features_R "右轮单一路面特征类型";
CM_ SG_ 901 ADS_LongitudinalDist_R "右前车轮轮心在地面的投影点到路面特征区域边缘的距离";
CM_ SG_ 901 ADS_CRC2 "Profile1A:E2E CRC (SAE J1850 CRC-8) for 8 Bytes
DataID:No ASIL requirements.Not configure
CRC Reserved.";
CM_ SG_ 901 ADS_RollgCntr2 "Profile1A:E2E Rolling message counter(the maximum value of Alive counter is 14)";
CM_ SG_ 901 ADS_Resd2 "Profile1A:E2E Reserved";
CM_ SG_ 901 ADS_FeatureHight_L "左前车轮前方特征路面凸起高度（或凹陷深度）";
CM_ SG_ 901 ADS_FeatureHight_R "右前车轮前方特征路面凸起高度（或凹陷深度）";
CM_ SG_ 901 SpeedBump_0_ID "减速带编号";
CM_ SG_ 901 SpeedBump_0_Valid "减速带有效位";
CM_ SG_ 901 SpeedBump_0_Dx "减速带距离";
CM_ SG_ 901 SpeedBump_0_ExistProb "减速带存在的概率";
CM_ SG_ 901 SpeedBump_1_ID "减速带编号";
CM_ SG_ 901 SpeedBump_1_Valid "减速带有效位";
CM_ SG_ 901 ADS_CRC3 "Profile1A:E2E CRC (SAE J1850 CRC-8) for 8 Bytes        
DataID:No ASIL requirements.Not configure
CRC Reserved.";
CM_ SG_ 901 ADS_RollgCntr3 "Profile1A:E2E Rolling message counter(the maximum value of Alive counter is 14)";
CM_ SG_ 901 ADS_Resd3 "Profile1A:E2E Reserved";
CM_ SG_ 901 SpeedBump_1_Dx "减速带距离";
CM_ SG_ 901 SpeedBump_1_ExistProb "减速带存在的概率";
CM_ SG_ 901 SpeedBump_2_ID "减速带编号";
CM_ SG_ 901 SpeedBump_2_Valid "减速带有效位";
CM_ SG_ 901 SpeedBump_2_Dx "减速带距离";
CM_ SG_ 901 SpeedBump_2_ExistProb "减速带存在的概率";
CM_ SG_ 901 SpeedBump_3_ID "减速带编号";
CM_ SG_ 901 SpeedBump_3_Valid "减速带有效位";
CM_ SG_ 901 ADS_CRC4 "Profile1A:E2E CRC (SAE J1850 CRC-8) for 8 Bytes        
DataID:No ASIL requirements.Not configure
CRC Reserved.";
CM_ SG_ 901 ADS_RollgCntr4 "Profile1A:E2E Rolling message counter(the maximum value of Alive counter is 14)";
CM_ SG_ 901 ADS_Resd4 "Profile1A:E2E Reserved";
CM_ SG_ 901 SpeedBump_3_Dx "减速带距离";
CM_ SG_ 901 SpeedBump_3_ExistProb "减速带存在的概率";
CM_ SG_ 901 SpeedBump_4_ID "减速带编号";
CM_ SG_ 901 SpeedBump_4_Valid "减速带有效位";
CM_ SG_ 901 SpeedBump_4_Dx "减速带距离";
CM_ SG_ 901 SpeedBump_4_ExistProb "减速带存在的概率";
CM_ BO_ 1301 "中高配以ADCC时间同步信息为主";
CM_ SG_ 1301 TimeSync_Type "Mode Signal: Multiplexer: 0x20 = SYNC with CRC, 0x28 = FUP with CRC, 0x10 = SYNC, 0x18 = FUP";
CM_ SG_ 1301 TimeSync_CRC "CRC calculation: AUTOSAR_SWS_CRCLibrary.pdf, function Crc_CalculateCRC8H2F()";
CM_ SG_ 1301 TimeSync_SequenceCounter "SC = Sequence Counter";
CM_ SG_ 1301 TimeSync_TimeDomain "Time Domain 0 to 15";
CM_ SG_ 1301 TimeSync_UserByte0 "Mode 32:UserByte0";
CM_ SG_ 1301 TimeSync_SyncTimeSec "Mode 32:SyncTime: seconds";
CM_ SG_ 1301 TimeSync_OverflowOfSeconds "Mode 40:OVS = Overflow of seconds, must be added to SyncTimeSec";
CM_ SG_ 1301 TimeSync_SGW "Mode 40:SyncToGTM = 0
SyncToSubDomain = 1";
CM_ SG_ 1301 TimeSync_Reserved0 "Mode 40:FUP Byte3: Bit7 to Bit3 reserved area";
CM_ SG_ 1301 TimeSync_SyncTimeNSec "Mode 40:SyncTime: nanoseconds";
CM_ SG_ 783 ADS_1_CRC1 "Profile1A:E2E CRC (SAE J1850 CRC-8) for 8 Bytes
DataID:0x000F";
CM_ SG_ 783 ADS_1_RollgCntr1 "Profile1A:E2E Rolling message counter(the maximum value of Alive counter is 14)";
CM_ SG_ 783 ADS_1_Resd1 "Profile1A:E2E Reserved";
CM_ SG_ 783 ADS_1_FunctionSuppressReq "ADAS functoin suppress requst";
CM_ SG_ 783 ADS_1_HPASts "HPA状态信号";
CM_ SG_ 783 ADS_1_VPASts "VPA状态信号";
CM_ SG_ 783 ADCC_CameraStreamSts "ADCC侧Camera链路工作状态
0x0:Reset  刚上电，未初始化状态
0x1:Inited  ADCC侧96722，camera 均device detect成功
0x2:Working  和ICC侧通信链路建立成功，正常通信
0x3:DeInitFinish  ADCC侧链路去初始化完成
0x4:Error  ADCC侧链路出现故障
0x5:Recoverying  ADCC侧链路正在恢复中(预留)
0x6~0x7:Reserved";
CM_ SG_ 783 ADCC_CameraErrorCode "ADCC侧Camera链路错误码";
CM_ SG_ 783 ADCC_HWRequest "Haptic Warning Request";
CM_ SG_ 783 ADCC_PP_M_Request "AEB PP Request";
CM_ SG_ 783 ADCC_HighwayZoneState "当前车辆是否在高速公路状态判断";
CM_ SG_ 783 ADCC_CoolingReq "BOSCH ADCCwater cooling level:
0x1:Low       -> LEVEL 1：3 L/min
0x2:Middle    -> LEVEL 2：3.5 L/min
0x3:High      -> LEVEL 3:：4 L/min
0x4:Critical  -> LEVEL 4：4.5 L/min
0x5:Emergency -> LEVEL 5：5 L/min
HW ADCCwater cooling level:
0x1:Low       -> LEVEL 1：0.25 L/min
0x2:Middle    -> LEVEL 2：0.5 L/min
0x3:High      -> LEVEL 3:：不涉及
0x4:Critical  -> LEVEL 4：2L/min
0x5:Emergency -> LEVEL 5：3L/min";
CM_ SG_ 783 ADCC_UploadFlag "闲时上传需求判断";
CM_ SG_ 783 ADCC_SurroundCameraErrorSts "环视摄像头故障状态：每个bit位表征一个摄像头的故障状态，当前环视和后环视摄像头同时故障时，对应值为0000 0011";
CM_ SG_ 783 ADCC_SysReadySts "系统初始化完成状态";
CM_ SG_ 783 ADS_1_APARPASts "APA状态信号
0x9:Background searching(捷途使用)";
CM_ SG_ 783 ADCC_OvertemperatureErrorSts "ADCC 过温故障状态";
CM_ SG_ 783 ADCC_CamFOV_HeatReq "双目摄像头FOV区域加热丝开启请求";
CM_ SG_ 788 ADS_2_CRC1 "Profile1A:E2E CRC (SAE J1850 CRC-8) for 8 Bytes
DataID:0x0010";
CM_ SG_ 788 ADS_2_RollgCntr1 "Profile1A:E2E Rolling message counter(the maximum value of Alive counter is 14)";
CM_ SG_ 788 ADS_2_Resd1 "Profile1A:E2E Reserved";
CM_ SG_ 788 ADS_2_FunctionSuppressReq "ADAS functoin suppress requst";
CM_ SG_ 788 ADS_2_HWRequest "Haptic Warning Request";
CM_ SG_ 788 ADS_2_PP_M_Request "AEB PP Request";
CM_ SG_ 788 ADS_2_AEBStatus "AEB状态信号
0x3:available(捷途使用)
0x6:blindness(捷途使用)";
CM_ SG_ 788 ADS_2_ClosingSpeed "无目标时报无效值，速度为相对速度";
CM_ SG_ 788 ADS_2_TTC "无目标时报无效值";
CM_ SG_ 788 ADS_2_FCWStatus "FCW状态信号";
CM_ SG_ 788 FCM_2_SysStatus "FCM Function State
FCM整体可用状态";
CM_ SG_ 788 FCM_2_IHCfunctionSts "远近光自动切换功能状态";
CM_ SG_ 788 FCM_2_HazardLightReq "0x0:Not active
0x1:OFF
0x2:Left（左转向灯亮）
0x3:Right(右转向灯亮）
0x4:Hazard（双闪灯亮）
0x5:Hzazard Flash（双闪灯闪烁三下）";
CM_ SG_ 788 FCM_2_HighBeamReq_Cmd "请求远光灯开关";
CM_ BO_ 794 "没有ADCC配置的就FCM发，有ADCC配置ADCC发";
CM_ SG_ 794 ADS_3_CRC1 "Profile1A:E2E CRC (SAE J1850 CRC-8) for 8 Bytes
DataID:0x0011";
CM_ SG_ 794 ADS_3_RollgCntr1 "Profile1A:E2E Rolling message counter(the maximum value of Alive counter is 14)";
CM_ SG_ 794 ADS_3_Resd1 "Profile1A:E2E Reserved";
CM_ SG_ 794 ADS_3_ICAStatus "ICA状态信号";
CM_ SG_ 794 ADS_3_ICATextinfo "ICA状态信号";
CM_ SG_ 794 ADS_3_ACCSts "ACC状态信号";
CM_ SG_ 794 ADS_3_DriverHandsoffWarning "驾驶员脱手报警请求";
CM_ SG_ 794 ADS_3_AESStatus "AES状态信号";
CM_ SG_ 794 ADS_3_LKSMod "LDW LDP激活模式状态";
CM_ SG_ 794 ADS_3_LKSSts "LKS状态信号
0x6: Blindness(Jetour)";
CM_ SG_ 794 ADS_3_ELKSts "ELK状态信号
0x6: Blindness(Jetour)";
CM_ SG_ 794 ADS_3_LKSLeftTrackingSt "LDW LDP左侧车道线激活状态";
CM_ SG_ 794 ADS_3_LKSRightTrackingSt "LDW LDP右侧车道线激活状态";
CM_ SG_ 794 ADS_3_ELKLeftActiveSt "ELK左侧车道线激活状态";
CM_ SG_ 794 ADS_3_ELKRightActiveSt "ELK右侧车道线激活状态";
CM_ SG_ 794 ADS_3_RearViewFoldReq "后视镜折叠请求";
CM_ SG_ 794 ADS_3_CRC2 "Profile1A:E2E CRC (SAE J1850 CRC-8) for 8 Bytes
DataID:0x00A9";
CM_ SG_ 794 ADS_3_RollgCntr2 "Profile1A:E2E Rolling message counter(the maximum value of Alive counter is 14)";
CM_ SG_ 794 ADS_3_Resd2 "Profile1A:E2E Reserved";
CM_ SG_ 794 ADS_ALCSts "拨杆变道功能状态";
CM_ SG_ 794 ADS_HNOPSts "高速领航辅助状态";
CM_ SG_ 794 ADS_UNOPSts "城市领航辅助状态";
CM_ SG_ 794 ADAS_ParkingActiveSubFuncSt "泊车子功能激活状态";
CM_ SG_ 794 ADS_DoorLockReq "请求车门解落锁";
CM_ SG_ 794 ADASLighSwtSts "Advanced Driver Assistance Systems Light Switch status
高级辅助驾驶系统灯开关（小蓝灯）反馈信号";
CM_ SG_ 794 ADCCFlowReq "ADCC coolant flow request
ADCC冷却液流量请求";
CM_ SG_ 1037 ADAS_HornReq "请求喇叭";
CM_ SG_ 1037 ADAS_RpaPowerOFFReq "上报ADAS低压电源下电请求";
CM_ SG_ 1037 ADAS_TurnLightReq "上报转向灯、危险报警灯请求";
CM_ SG_ 1037 ADAS_HighBeamReq "上报远光灯请求";
CM_ SG_ 1037 ADAS_LowBeamReq "请求近光灯开关";
CM_ SG_ 1037 ADS_AutoLightSwCtrl "Headlight Operating Mode Control
大灯工作模式控制";
CM_ SG_ 1037 ADS_WshrReq "Washer Momentary Activate Request
洗涤点动开启请求";
CM_ SG_ 1037 ADS_FrontWiperReq "Wiper Activation Request
雨刮开启请求";
CM_ SG_ 1217 ASU_1_CRC1 "Profile1A:E2E CRC (SAE J1850 CRC-8) for 8 Bytes
DataID:0x0012";
CM_ SG_ 1217 ASU_1_RollgCntr1 "Profile1A:E2E Rolling message counter(the maximum value of Alive counter is 14)";
CM_ SG_ 1217 ASU_1_ASUSysFailrSts "ASU System failure state.";
CM_ SG_ 1217 ASU_1_SuspCurrentLvl "Suspension Current High Level
0x0：无效
0x1：非常高的等级
0x2：介于非常高和高的等级之间
0x3：高等级
0x4：介于高等级和正常等级之间
0x5：正常等级
0x6：介于正常和低等级之间
0x7：低等级
0x8：介于低等级和极低等级之间
0x9：非常低的等级
0xA：方便上下车高度等级
0xB：便利装载高度等级
0xC~0xF：预留";
CM_ SG_ 1217 ASU_1_ECASSysSts "ECAS System State";
CM_ SG_ 1217 ASU_1_SuspTmpAdjSts "Suspension temporary Adjust Status";
CM_ SG_ 1217 ASU_1_MaintainMod "indicate the AirSuspension is in maintain mode or not.";
CM_ SG_ 1217 ASU_1_ECASErrSts "ECAS Error Status";
CM_ SG_ 1217 ASU_1_SuspTarLvl "Suspension Target High Level
0x0：无要求
0x1：非常高的等级
0x2：高等级
0x3：正常等级
0x4：低等级
0x5：非常低的等级
0x6：方便上下车高度等级
0x7：便利装载高度等级";
CM_ SG_ 1217 ASU_1_EasyEntryEna "easy Entry Enable.";
CM_ SG_ 1217 ASU_1_AutoEasyEntryFb "Auto Easy Entry feedback";
CM_ SG_ 1217 ASU_1_ECASModeFb "ECAS Mode feedback";
CM_ SG_ 1217 ASU_1_BluetoothManEasyEntryFb "Bluetooth Manual Easy Entry feedback";
CM_ SG_ 1217 ASU_1_HighwayModFb "Highway Mode feedback";
CM_ SG_ 1217 ASU_1_CDCErrSts "CDC error Satus";
CM_ SG_ 1217 ASU_1_SuspDampingLvl "Suspension Target High Level";
CM_ SG_ 776 ASU_2_CRC1 "Profile1A:E2E CRC (SAE J1850 CRC-8) for 8 Bytes
DataID:0x0013";
CM_ SG_ 776 ASU_2_RollgCntr1 "Profile1A:E2E Rolling message counter(the maximum value of Alive counter is 14)";
CM_ SG_ 776 ASU_2_LFHeight "Height of front left wheel.";
CM_ SG_ 776 ASU_2_RFHeight "Height of front right wheel.";
CM_ SG_ 776 ASU_2_LRHeight "Height of rear left wheel.";
CM_ SG_ 776 ASU_2_RRHeight "Height of rear right wheel.";
CM_ SG_ 776 ASU_2_sensorErrorSts "Sensor Error Status.";
CM_ SG_ 1291 BMS_SOCLight "BMS_SOCLight";
CM_ SG_ 1295 BMS_ChgWireConnect_LightSts "BMS_ChgWireConnect_LightSts";
CM_ SG_ 1295 BMS_Chg_LightSts "BMS_Chg_LightSts";
CM_ BO_ 852 "从休眠到唤醒：此帧快发40次，唤醒后：此阵按正常快发10帧";
CM_ SG_ 852 BNCM_1_WelcomeON "welcome light request
迎宾开启请求";
CM_ SG_ 852 BNCM_1_WALLockRequest "walk away unlock request
离开上锁请求";
CM_ SG_ 852 BNCM_1_UIRUnLockRequest "approve unlock reques
靠近解锁请求";
CM_ SG_ 852 BNCM_1_VehicleSearchRequest "寻车请VehicleSearchRequest
寻车请求";
CM_ SG_ 879 BNCM_4_CRC1 "Profile1A:E2E CRC (SAE J1850 CRC-8) for 8 Bytes
DataID:0x0024";
CM_ SG_ 879 BNCM_4_RollgCntr1 "Profile1A:E2E Rolling message counter(the maximum value of Alive counter is 14)";
CM_ SG_ 879 BNCM_4_Resd1 "Profile1A:E2E Reserved";
CM_ SG_ 879 BNCM_4_ChallengeFeedback "ADCC功能安全校验反馈";
CM_ SG_ 879 BNCM_4_RpaDevicefailSts "蓝牙故障状态反馈";
CM_ SG_ 879 BNCM_4_RpaModReq "进入遥控泊车模式请求";
CM_ SG_ 879 BNCM_4_ExitAndPowerOff "关闭发动机";
CM_ SG_ 879 BNCM_4_RpaModselect "0x0:默认值
遥控泊入；
遥控泊出；
直入直出；
遥控记忆泊入
遥控记忆泊出";
CM_ SG_ 879 BNCM_4_RpaBtnSts "RPA开关控制状态";
CM_ SG_ 879 BNCM_4_StraightInBtnSts "直入功能开关控制状态";
CM_ SG_ 879 BNCM_4_StraightOutBtnSts "直出功能开关控制状态";
CM_ SG_ 879 BNCM_4_RpaBtnCancelSts "RPA功能取消开关控制状态";
CM_ SG_ 879 BNCM_4_PrkOutModSelRmt "泊出方向选择";
CM_ SG_ 879 BNCM_4_HeartbeatSignal "蓝牙心跳信号";
CM_ SG_ 879 BNCM_4_PauseBtn "离车泊入暂停开关";
CM_ SG_ 879 BNCM_4_ResumeBtn "离车泊入恢复开关";
CM_ SG_ 879 BNCM_4_RpaDeviceDisSts "蓝牙设备距离状态反馈";
CM_ SG_ 879 BNCM_4_BLEConnSts "蓝牙连接状态";
CM_ SG_ 879 BNCM_4_BLEErrStatus "蓝牙故障状态";
CM_ BO_ 1191 "从休眠到唤醒：此帧快发20次，唤醒后：此阵按正常快发5次";
CM_ SG_ 1191 BNCM_6_RemoteControl "the vehicle control
车控指令";
CM_ BO_ 672 "从休眠到唤醒：此帧快发100次，唤醒后：此阵按正常快发10次";
CM_ SG_ 672 BNCM_14_LockButtAct "物理钥匙闭锁键按压动作";
CM_ SG_ 672 BNCM_14_UnLockButtAct "物理钥匙解锁键按压动作";
CM_ SG_ 672 BNCM_14_RemoteButtAct "物理钥匙遥控键按压动作";
CM_ SG_ 1143 OBC_CC_ConnectSts "CC connect states";
CM_ SG_ 1172 ExternalTemperature_C "External temperature（℃）
Invalid: When external temperature is fail, the signal value is 0xFE.";
CM_ SG_ 1172 ExternalTemperatureFailSts "External Temperature Sensor Fail Status
外温传感器故障状态";
CM_ SG_ 1188 TMS_IncarTemp "Incar Temperature
车内温度";
CM_ SG_ 884 WPump3Duty "Motor Use Water Pump Duty
电机用电子水泵工作占空比";
CM_ SG_ 1138 SysRefLoopFault "系统冷却液工作模式";
CM_ SG_ 321 CSA_1_CRC "Profile1A:E2E CRC (SAE J1850 CRC-8) for 8 Bytes
DataID:0x0029";
CM_ SG_ 321 CSA_1_RollgCntr "Profile1A:E2E Rolling message counter(the maximum value of Alive counter is 14)";
CM_ SG_ 321 CSA_1_Resd "Profile1A:E2E Reserved";
CM_ SG_ 321 GearShiftPos "Driver requested gear shift position";
CM_ SG_ 321 GearShiftPosInverse "Driver requested gear shift position inverse";
CM_ SG_ 321 STAT_ParkButton "Driver Request Park Button";
CM_ SG_ 321 STAT_ShifterLeverFault "Shift sensor fault status";
CM_ SG_ 321 DriveModeActive "SBW decide whether enter into Sport Mode.
备注：E03国内、E0Y国内项目CSA不发";
CM_ SG_ 321 DriveModeReq "SBW transmit Sport Mode request.
备注：E03国内、E0Y国内项目CSA不发";
CM_ SG_ 631 CSA_2_CRC1 "Profile1A:E2E CRC (SAE J1850 CRC-8) for 8 Bytes
DataID:0x002A";
CM_ SG_ 631 CSA_2_RollgCntr1 "Profile1A:E2E Rolling message counter(the maximum value of Alive counter is 14)";
CM_ SG_ 631 CSA_2_Resd1 "Profile1A:E2E Reserved";
CM_ SG_ 631 CSA_2_AllWarningInfo "EGS全部报警信号
T1C项目，EGS此信号发0x0、0x1、0x4，仪表接收";
CM_ SG_ 631 CSA_2_TurnSigLvrCmd "turn signal lever command for CSA.";
CM_ SG_ 631 CSA_2_HiBeamSwtCmd "High beam switch command for CSA..";
CM_ SG_ 631 CSA_2_WshrFrntCmd "Washer Front  command for CSA.";
CM_ SG_ 631 CSA_2_WiprFrntCmd "Wiper front command for CSA..";
CM_ BO_ 967 "禾多配置不发此帧报文";
CM_ SG_ 967 FRM_2_CRC "Profile5:E2E CRC16 (polynomial:0x1021)       
DataID:Use CANID,other bits Fill with 0";
CM_ SG_ 967 FRM_2_RollgCntr "Profile5:E2E Rolling message counter";
CM_ SG_ 967 FRM_2_DetnHd_DetnBlockCounter "Front Radar Moudle_2_Detection Header_Detection Block Counter 
前雷达探测点前言：块计数值";
CM_ SG_ 967 FRM_2_DetnHd_MountPosX "Front Radar Moudle_2_Detection Header_Mount Position X
前雷达探测点前言：雷达在X方向安装位置
mount offset of sensor in longitudinal direction relative to rear axis of vehicle";
CM_ SG_ 967 FRM_2_DetnHd_MountPosY "Front Radar Moudle_2_Detection Header_Mount Position Y
前雷达探测点前言：雷达在Y方向安装位置
mount offset of sensor in lateral direction relative to mid axis of vehicle";
CM_ SG_ 967 FRM_2_DetnHd_MountPosZ "Front Radar Moudle_2_Detection Header_Mount Position Z
前雷达探测点前言：雷达在Z方向安装位置
mount offset of sensor in elevation direction relative to GROUND";
CM_ SG_ 967 FRM_2_DetnHd_MountAngleYaw "Front Radar Moudle_2_Detection Header_Mount AngleYaw
前雷达探测点前言：雷达安装位置偏航角
angle between sensor mounting direction(boresight direction) and vehicle longitudinal axis, Azimuth";
CM_ SG_ 967 FRM_2_DetnHd_MountAnglePitch "Front Radar Moudle_2_Detection Header_Mount Angle Pitch
前雷达探测点前言：雷达安装位置俯仰角
angle between sensor mounting direction(boresight direction) and vehicle longitudinal axis, Elevation";
CM_ SG_ 967 FRM_2_DetnHd_MountAngleRoll "Front Radar Moudle_2_Detection Header_Mount Angle Roll
前雷达探测点前言：雷达安装倾斜角
Tilt of the mounting sensor";
CM_ SG_ 967 FRM_2_DetnHd_AlignAglYawErrCurr "Front Radar Moudle_2_Detection Header_Alignment AngleYaw Erro Current
前雷达探测点前言：雷达当前校准的偏航角误差
Current sensor mounting azimuth angle error by auto-alignment";
CM_ SG_ 967 FRM_2_DetnHd_AlignAglYawErrEOL "Front Radar Moudle_2_Detection Header_Alignment AngleYaw ErroEOL
前雷达探测点前言：雷达产线校准的偏航角误差
Recorded sensor mounting azimuth angle error by EOL-alignment";
CM_ SG_ 967 FRM_2_DetnHd_AlignAglPitchErrEOL "Front Radar Moudle_2_Detection Header_Alignment Angle Pitch Erro EOL
前雷达探测点前言：雷达产线校准的俯仰角误差
Recorded sensor mounting elevation angle error by EOL-alignment";
CM_ SG_ 967 FRM_2_DetnHd_FOVYawAglLower "Front Radar Moudle_2_Detection Header_Field Of View Yaw Angle Lower
前雷达探测点前言：雷达在偏航方向上的下视场角
Lower angle of the fied of view Azimuth";
CM_ SG_ 967 FRM_2_DetnHd_FOVYawAglUpper "Front Radar Moudle_2_Detection Header_Field Of View Yaw Angle Upper
前雷达探测点前言：雷达在偏航方向上的上视场角
Upper angle of the field of view Azimuth based on sensro boresight direction";
CM_ SG_ 967 FRM_2_DetnHd_FOVPitchAglLower "Front Radar Moudle_2_Detection Header_Field Of View Pitch Angle Lower
前雷达探测点前言：雷达在俯仰方向上的下视场
Lower angle of the fied of view Elevation based on sensro boresight direction";
CM_ SG_ 967 FRM_2_DetnHd_FOVPitchAglUpper "Front Radar Moudle_2_Detection Header_Field Of View Pitch Angle Upper
前雷达探测点前言：雷达在俯仰方向上的上视场
Upper angle of the field of view Elevation based on sensro boresight direction";
CM_ SG_ 967 FRM_2_DetnHd_MaxDetectionRange "Front Radar Moudle_2_Detection Header_Maximun Detection Range
前雷达探测点前言：雷达最大探测范围
Estimated detection range of the sensor";
CM_ SG_ 967 FRM_2_DetnHd_HWFail "Front Radar Moudle_2_Detection Header_Hardware Fail
前雷达探测点前言：雷达硬件故障
Flag To Indicate If Sensor Hardware Failure Is Exist Or Not";
CM_ SG_ 967 FRM_2_DetnHd_Misalignment "Front Radar Moudle_2_Detection Header_Misalignment
前雷达探测点前言：雷达失校准
Flag To Indicate If Alignment Out Of Spec";
CM_ SG_ 967 FRM_2_DetnHd_AlignmentNotDone "Front Radar Moudle_2_Detection Header_Alignment Not Done
前雷达探测点前言：雷达未校准
Flag To Indicate if Alignment Has Been Done or Not";
CM_ SG_ 967 FRM_2_DetnHd_SensorBlockage "Front Radar Moudle_2_Detection Header_Sensor Blockage
前雷达探测点前言：雷达被遮挡
Flag To Indicate If Sensor Is Blind Or Not";
CM_ SG_ 967 FRM_2_DetnHd_ObjDetFail "Front Radar Moudle_2_Detection Header_Object Detection Fail
前雷达探测点前言：雷达目标探测失效
Indicates An Error In The Object Detection System. This flag include all conditions that shall impact radar detection performance, like HWFailure, Misalignment, AlignmentNotDone, SensorBlockage, OutOfVoltage, OverTemperature, ReceivedCANTimeOut, ReceivedCANInvalid, RF-BoardNoWorking.";
CM_ SG_ 967 FRM_2_DetnHd_OutOfVoltage "Front Radar Moudle_2_Detection Header_Out Of Voltage
前雷达探测点前言：雷达电压超范围
Indicates An Error Of Over Or Under Voltage";
CM_ SG_ 967 FRM_2_DetnHd_OverTemperature "Front Radar Moudle_2_Detection Header_Over Temperature
前雷达探测点前言：雷达温度过高
Indicates An Error Of Over Temperature";
CM_ SG_ 967 FRM_2_DetnHd_ReceivedCANTimeOut "Front Radar Moudle_2_Detection Header_Received CAN Time Out
前雷达探测点前言：雷达接收CAN信号超时
Flag To Indicate If Received CAN Signal Time Out Or Not";
CM_ SG_ 967 FRM_2_DetnHd_ReceivedCANInvalid "Front Radar Moudle_2_Detection Header_Received CAN Invalid
前雷达探测点前言：雷达接收到无效CAN信号
Flag To Indicate If Received CAN Signal Invalid Or Not";
CM_ SG_ 967 FRM_2_DetnHd_RFBoardWorkingSts "Front Radar Moudle_2_Detection Header_Radial Frequency Board Working Status
前雷达探测点前言：雷达射频板工作状态
Flag To Indicate Sensor RF Board Working Or Not. This flag shall set to 0x1 NoWokring only when RF Board power cutted off via UDS command actively. RF Board failure shall not set this flag.";
CM_ SG_ 967 FRM_2_DetnHd_ValidDetnCount "Front Radar Moudle_2_Detection Header_Valid Detection Count
前雷达探测点前言：雷达有效探测点数量
number of detected VALID Objects that have been sent to the bus";
CM_ SG_ 967 FRM_2_DetnHd_DetnDownSel "Front Radar Moudle_2_Detection Header_Detection Down Select
前雷达探测点前言：雷达探测点输出达到上限
the detected number of objects exceeded the number of max. objects that can be transmitted";
CM_ SG_ 967 FRM_2_DetnHd_DetnTimeStamp "Front Radar Moudle_2_Detection Header_Detection Time Stamp
前雷达探测点前言：探测点的时间戳
Captured time of object based on local time base of FRM which is synchronized by global time periodically";
CM_ SG_ 967 FRM_2_DetnHd_DetnTimeStampSts "Front Radar Moudle_2_Detection Header_Detection Time Stamp Status
前雷达探测点前言：探测点时间戳状态
Autosar StbM_TimeBaseStatusType bitfield
Bit 0: TIMEOUT
Bit 1: SYNC_TO_GATEWAY
Bit 2: GLOBAL_TIME_BASE
Bit 3: TIMELEAP_FUTURE
Bit 4: TIMELEAP_PAST";
CM_ SG_ 967 FRM_2_DetnHd_DetnTimeLatency "Front Radar Moudle_2_Detection Header_Detection Time Latency
前雷达探测点前言：探测点时间延迟
Sensor latency from object capture scene to object transmission";
CM_ SG_ 967 FRM_2_DetnHd_NotConfigured "Front Radar Moudle_2_Detection Header_Not Configured
前雷达探测点前言：雷达未配置
Flag To Indicate If Radar Configured Or Not";
CM_ SG_ 967 FRM_2_DetnHd_ParameterInvalid "Front Radar Moudle_2_Detection Header_Parameter Invalid
前雷达探测点前言：雷达参数无效
Flag To Indicate If Parameter Invalid Or Not";
CM_ SG_ 571 FLZCU_1_CRC "Profile1A:E2E CRC (SAE J1850 CRC-8) for 8 Bytes
DataID:0x0036";
CM_ SG_ 571 FLZCU_1_RollgCntr "Profile1A:E2E Rolling message counter(the maximum value of Alive counter is 14)";
CM_ SG_ 571 FLZCU_1_Resd "Profile1A:E2E Reserved";
CM_ SG_ 571 DrvSeatOccupiedSts "主驾座椅占位状态，0为未占位，1为占位
增加右舵前，原信号名为：
FL_SeatOccupiedSts";
CM_ SG_ 571 DrvDoorLockSts "主驾门锁状态
Driver Door Lock Status
增加右舵前，原信号名为：
LHFDoorLockSts";
CM_ SG_ 571 DrvDoorSts "主驾门状态
Driver Door Status
增加右舵前，原信号名为：
LHFdoorsts";
CM_ SG_ 571 LHTurnSW "左转向开关，打开发1；关闭发0，默认发0";
CM_ SG_ 571 RHTurnSW "右转向开关，打开发1；关闭发0，默认发0";
CM_ SG_ 571 HazardLightSW "带自锁的开关，按照危险灯状态发送；不带自锁的开关，发送危险灯状态";
CM_ SG_ 571 DrvSeatBeltSW "安全带检测开关，0为未插入，1为插入
增加右舵前，原信号名为：
LHFSeatBeltSW";
CM_ SG_ 571 DirectionIndLeft "当左转向灯闪烁时一直发1，转向灯熄灭时一直发0.";
CM_ SG_ 571 DirectionIndRight "当右转向灯闪烁时一直发1，转向灯熄灭时一直发0.";
CM_ SG_ 571 DrvSeatBeltFaultStatus "主驾安全带故障状态
Driver seat belt fault status
增加右舵前，原信号名为：
FL_SeatBeltFaultStatus";
CM_ SG_ 1120 FLZCU_3_CRC "Profile1A:E2E CRC (SAE J1850 CRC-8) for 8 Bytes
DataID:0x00A4";
CM_ SG_ 1120 FLZCU_3_RollgCntr "Profile1A:E2E Rolling message counter(the maximum value of Alive counter is 14)";
CM_ SG_ 1120 RLHS_2_AmbBrightness "顶向光";
CM_ SG_ 1120 RLHS_2_IRBrightness "红外光";
CM_ SG_ 1120 RLHS_Rainfall "雨量大小：无雨，小雨，中雨，大雨";
CM_ SG_ 1120 RLHS_LiSwithReason "开关灯切换原因
RLS_ LightSwithReason";
CM_ SG_ 1260 FLZCU_7_CRC "Profile1A:E2E CRC (SAE J1850 CRC-8) for 8 Bytes
DataID:0x0080";
CM_ SG_ 1260 FLZCU_7_RollgCntr "Profile1A:E2E Rolling message counter(the maximum value of Alive counter is 14)";
CM_ SG_ 1260 FLZCU_7_Resd "Profile1A:E2E Reserved";
CM_ SG_ 1181 FLZCU_9_CRC "Profile1A:E2E CRC (SAE J1850 CRC-8) for 8 Bytes
DataID:0x009C";
CM_ SG_ 1181 FLZCU_9_RollgCntr "Profile1A:E2E Rolling message counter(the maximum value of Alive counter is 14)";
CM_ SG_ 1181 FLZCU_9_Resd1 "Profile1A:E2E Reserved";
CM_ SG_ 1181 FLZCU_9_PowerMode "EV、REEV、PHEV等新能源车型低压电源状态";
CM_ SG_ 1181 FLZCU_9_ArmingSts "整车设防/解防成功状态信号
设防成功0x1,解防成功0x2
设防成功/解放成功后0x1或0x2值连续发送";
CM_ SG_ 843 HOD_CRC "Profile1A:E2E CRC (SAE J1850 CRC-8) for 8 Bytes
DataID:0x0038";
CM_ SG_ 843 HOD_RollingCounter "Profile1A:E2E Rolling message counter(the maximum value of Alive counter is 14)";
CM_ SG_ 843 HOD_Resd1 "Profile1A:E2E Reserved";
CM_ SG_ 843 HOD_OnOffSts "驾驶员是否手方握向盘";
CM_ SG_ 843 HOD_OnOffStsValid "驾驶员是否手握方向盘有效位";
CM_ SG_ 843 HOD_HandOnSts "驾驶员单手或双手扶持状态";
CM_ SG_ 843 HOD_OneHand_Area "驾驶员单手手扶方向盘的区域";
CM_ SG_ 843 HOD_OneHand_AreaValid "驾驶员单手手扶方向盘的区域有效位";
CM_ SG_ 843 HOD_LeftArea_Sts "驾驶员单手搭或单手握的状态";
CM_ SG_ 843 HOD_LeftArea_StsVD "驾驶员单手搭或单手握的状态有效位";
CM_ SG_ 843 HOD_RightArea_Sts "驾驶员单手搭或单手握的状态";
CM_ SG_ 843 HOD_RightArea_StsVD "驾驶员单手搭或单手握的状态有效位";
CM_ SG_ 843 HOD_FC_CAP_SENSOR_ERR "电容传感器故障";
CM_ SG_ 843 HOD_FC_ECU_HW_Fault "ECU硬件故障";
CM_ SG_ 843 HOD_FC_BAT_LOW "电池电压低";
CM_ SG_ 843 HOD_FC_BAT_HIGH "电池电压高";
CM_ SG_ 843 HOD_FC_ResponseError "Response Error Bit";
CM_ SG_ 843 HOD_FC_SYSTEM_ERR "系统故障";
CM_ SG_ 1030 FLZCU_12_CRC "Profile1A:E2E CRC (SAE J1850 CRC-8) for 8 Bytes
DataID:0x009B";
CM_ SG_ 1030 FLZCU_12_RollgCntr "Profile1A:E2E Rolling message counter(the maximum value of Alive counter is 14)";
CM_ SG_ 1030 FLZCU_FrontWiperParkStatus "前雨刮归位信号";
CM_ SG_ 1030 FLZCU_FrontWiperWipingStatus "前雨刮工作状态";
CM_ SG_ 1030 RearViewFoldSts "后视镜折叠状态";
CM_ SG_ 1076 RLHS_1_FWBrightness "前向光";
CM_ SG_ 1076 RLHS_TempSensorValue "This signal delivers information about  temperature in car 
玻璃温度
有效值0x1开始
Start up(初始值) 0x00
Invalid(无效值)0xFF";
CM_ SG_ 1076 RLHS_TempDewPoint "露点
有效值0x1开始
Start up(初始值) 0x00
Invalid(无效值)0x7FF";
CM_ SG_ 1076 RLHS_Humid_Temp_Error "StartUp：初始化值
Normal：传感器正常
Error：传感器有故障
若BCM未接收到此信号，超时后BCM路由到CAN上此信号发0x1";
CM_ SG_ 1071 FLZCU_LightMainSwitchSts "小灯、近光、Auto开关位置";
CM_ SG_ 1071 FLZCU_FLFoglightSts "左前雾灯状态,用于右前雾灯开关判断";
CM_ SG_ 1071 FLZCU_FRFoglightSts "右前雾灯状态反馈";
CM_ SG_ 1071 FLZCU_RearFogLightSts "后雾灯状态反馈";
CM_ SG_ 1071 FLZCU_LowBeamSts "近光灯状态";
CM_ SG_ 1071 FLZCU_HighBeamSts "远光灯状态";
CM_ SG_ 1071 FLZCU_HighBeamFaults "远光灯故障";
CM_ SG_ 1071 FLZCU_RearFogLightFaults "后雾灯故障";
CM_ SG_ 1071 FLZCU_ParkLightFaults "位置灯故障";
CM_ SG_ 1071 FLZCU_DaytimeLight "日行灯状态";
CM_ SG_ 1071 FLZCU_HMASwSts "IHC激活状态";
CM_ SG_ 1071 FLZCU_BrkLightSts "制动灯状态";
CM_ SG_ 1071 FLZCU_FrontFogLightSts "前雾灯状态反馈";
CM_ SG_ 1071 FLZCU_CamFOV_HeatSts "摄像头区域前风挡加热状态";
CM_ SG_ 1071 ADASLightStsFb "ADAS light state feedback
ADAS灯状态反馈";
CM_ SG_ 1071 ADSLightFaildSts "ADAS light failure state
ADAS灯故障状态";
CM_ SG_ 864 MFS_2_CRC "Profile1A:E2E CRC (SAE J1850 CRC-8) for 8 Bytes
DataID:0x0039";
CM_ SG_ 864 MFS_2_RollgCntr "Profile1A:E2E Rolling message counter(the maximum value of Alive counter is 14)";
CM_ SG_ 864 MFS_Cruise_Control "巡航开关";
CM_ SG_ 864 MFS_RESPlus "CC/SL RES/+ button
备注：无该按键功能或没有触发该按键时，MFS此信号发0x0";
CM_ SG_ 864 MFS_SETMinus "CC/SL SET/- button
备注：无该按键功能或没有触发该按键时，MFS此信号发0x0";
CM_ SG_ 864 MFS_Time_Gap_Reduce "时距（本车离前车间距/本车车速）
备注：无该按键功能或没有触发该按键时，MFS此信号发0x0";
CM_ SG_ 864 MFS_Time_Gap_Add "时距（本车离前车间距/本车车速）
备注：无该按键功能或没有触发该按键时，MFS此信号发0x0";
CM_ SG_ 864 MFS_Rsp_Error "备注：E0X未使用";
CM_ SG_ 864 MFS_LeftRoller "CC/SL RES/+ button
备注：无该按键功能或没有触发该按键时，MFS此信号发0x0
原始脉冲发送逻辑：转一圈x个脉冲
快滚：单位时间内大于 x个脉冲/s  MFS发送快滚动
慢滚同上逻辑
自驾收到信号后逻辑：后续定出";
CM_ SG_ 864 MFS_LeftRollerMiddleKey "滚轮
备注：E0X项目滚轮型方向盘开关不进行长短按判断
E0X未使用，MFS发送自定义功能信号";
CM_ SG_ 864 MFS_LeRollrUpDwnAdjSteps "左侧滚轮上下滚动计数";
CM_ SG_ 683 FRZCU_1_CRC "Profile1A:E2E CRC (SAE J1850 CRC-8) for 8 Bytes
DataID:0x003A";
CM_ SG_ 683 FRZCU_1_RollgCntr "Profile1A:E2E Rolling message counter(the maximum value of Alive counter is 14)";
CM_ SG_ 683 FRZCU_1_Resd "Profile1A:E2E Reserved";
CM_ SG_ 683 PassDoorSts "副驾门状态
Passenger door status
增加右舵前，原信号名为：
RHFDoorSts";
CM_ SG_ 683 PassRearDoorSts "副驾侧后排门状态
Passenger rear　door status
增加右舵前，原信号名为：
RHRDoorSts";
CM_ SG_ 683 PassDoorLockSts "副驾门锁状态
Passenger door lock status
增加右舵前，原信号名为：
RHFDoorLockSts";
CM_ SG_ 683 PassRearDoorLockSts "副驾后排门锁状态
Passenger rear door lock status
增加右舵前，原信号名为：
RHRDoorLockSts";
CM_ SG_ 1324 FRZCU_7_CRC "Profile1A:E2E CRC (SAE J1850 CRC-8) for 8 Bytes
DataID:0x0082";
CM_ SG_ 1324 FRZCU_7_RollgCntr "Profile1A:E2E Rolling message counter(the maximum value of Alive counter is 14)";
CM_ SG_ 1324 TirePositionWarning_LHFTire "左前方位轮胎胎压报警，含快速失压、低压、高压、高温。";
CM_ SG_ 1324 TirePositionWarning_RHFTire "右前方位轮胎胎压报警，含快速失压、低压、高压、高温。";
CM_ SG_ 1324 TirePositionWarning_LHRTire "左后方位轮胎胎压报警，含快速失压、低压、高压、高温。";
CM_ SG_ 1324 TirePositionWarning_RHRTire "右后方位轮胎胎压报警，含快速失压、低压、高压、高温。";
CM_ SG_ 1324 TirePressureWarningLampSts "胎压报警灯状态，含熄灭、闪烁（快速失压）、常亮（低压）三种状态";
CM_ SG_ 638 DrvHandleSwitchSts "主驾门把手电容开关状态(门把手上有外电容和内电容，电释放是内电容，外电容是车外pe功能)此处用Outside车外pe功能
Driver handle switch status
增加右舵前，原信号名为：
FRZCU_HandleSwitchStsFL";
CM_ SG_ 638 PassHandleSwitchSts "副驾门把手电容开关状态(门把手上有外电容和内电容，电释放是内电容，外电容是车外pe功能)此处用Outside车外pe功能
Passenger handle switch status
增加右舵前，原信号名为：
FRZCU_HandleSwitchStsFR";
CM_ SG_ 638 PassRearHandleSwitchSts "副驾侧后排门把手电容开关状态(门把手上有外电容和内电容，电释放是内电容，外电容是车外pe功能)此处用Outside车外pe功能
Passenger rear handle switch status
增加右舵前，原信号名为：
FRZCU_HandleSwitchStsRR";
CM_ SG_ 638 DrvRearHandleSwitchSts "主驾侧后排门把手电容开关状态(门把手上有外电容和内电容，电释放是内电容，外电容是车外pe功能)此处用Outside车外pe功能
Driver rear handle switch status
增加右舵前，原信号名为：
FRZCU_HandleSwitchStsRL";
CM_ SG_ 949 PEPS_InformationSource "To show the lock/unlock information is from Smart or RKE .";
CM_ SG_ 949 PEPS_OrderInformation "PEPS do not add any additional logic. Just reflect the status of the switch state.";
CM_ SG_ 949 PEPS_KeySts "PEPS钥匙位置状态";
CM_ SG_ 1028 PEPS_WelcomeON "welcome light request
迎宾开启请求";
CM_ SG_ 1028 PEPS_VehicleSearchReq "寻车请VehicleSearchRequest
寻车请求";
CM_ SG_ 1028 PEPS_RKETrunkSts "实体钥匙尾门按键";
CM_ SG_ 1028 PEPS_UIRUnLockRequest "approve unlock request
靠近解锁请求";
CM_ SG_ 1028 PEPS_WALLockRequest "远离闭锁请求";
CM_ SG_ 1270 PEPS_LockButtAct "物理钥匙闭锁键按压动作";
CM_ SG_ 1270 PEPS_UnLockButtAct "物理钥匙解锁键按压动作";
CM_ SG_ 1270 PEPS_ParkFrntEna "Park Front Enable
钥匙遥控 直入直出功能
前进使能";
CM_ SG_ 1270 PEPS_ParkBackEna "Park Backt Enable
钥匙遥控 直入直出功能
后退使能";
CM_ SG_ 1270 PEPS_AVPFctReq "PEPS Request AVP Function Active or Exit
钥匙遥控 直入直出功能
0x1: AVP 功能激活
0x2: AVP 功能退出
0x3: AVP 功能退出、熄火闭锁";
CM_ SG_ 1270 PEPS_AVPActv "Whether BDM can be applied to parking function";
CM_ SG_ 1270 PEPS_RpaDeviceDisSts "钥匙到车端距离信息";
CM_ SG_ 1270 PEPS_ParkinEna "钥匙遥控泊入功能泊入使能";
CM_ SG_ 699 RZCU_2_CRC "Profile1A:E2E CRC (SAE J1850 CRC-8) for 8 Bytes
DataID:0x003B";
CM_ SG_ 699 RZCU_2_RollgCntr "Profile1A:E2E Rolling message counter(the maximum value of Alive counter is 14)";
CM_ SG_ 699 RZCU_2_Resd "Profile1A:E2E Reserved";
CM_ SG_ 699 DrvRearDoorSts "Driver Rear Door Status
主驾侧后门状态
增加右舵前，原信号名为：
LHRdoorSts";
CM_ SG_ 699 DrvRearDoorLockSts "主驾侧后门锁状态
Driver rear door lock status
增加右舵前，原信号名为：
LHRDoorLockSts";
CM_ SG_ 1258 RZCU_7_CRC "Profile1A:E2E CRC (SAE J1850 CRC-8) for 8 Bytes
DataID:0x0083";
CM_ SG_ 1258 RZCU_7_RollgCntr "Profile1A:E2E Rolling message counter(the maximum value of Alive counter is 14)";
CM_ SG_ 1258 RZCU_RearWiperWipingStatus "后雨刮工作状态";
CM_ SG_ 1258 RZCU_RearWiperParkStatus "后雨刮归位信号";
CM_ SG_ 1050 FLCR_1_CRC1 "Profile1A:E2E CRC (SAE J1850 CRC-8) for 8 Bytes
DataID:0x0040";
CM_ SG_ 1050 FLCR_1_RollgCntr1 "Profile1A:E2E Rolling message counter(the maximum value of Alive counter is 14)";
CM_ SG_ 1050 FLCR_1_Resd1 "Profile1A:E2E Reserved";
CM_ SG_ 1050 FLCR_1_SysSt "System self-test State";
CM_ SG_ 1050 FLCR_1_BlkSts "Blockage Status";
CM_ SG_ 1062 FLCR_2_CRC1 "Profile1A:E2E CRC (SAE J1850 CRC-8) for 8 Bytes
DataID:0x0041";
CM_ SG_ 1062 FLCR_2_RollgCntr1 "Profile1A:E2E Rolling message counter(the maximum value of Alive counter is 14)";
CM_ SG_ 1062 FLCR_2_Resd1 "Profile1A:E2E Reserved";
CM_ SG_ 1062 FLCR_2_FCTAWarn "FCTA Warning";
CM_ SG_ 1062 FLCR_2_FCTBWarn "FCTB Warning";
CM_ SG_ 1062 FLCR_2_FCTBReq "FCTBRequest";
CM_ SG_ 1062 FLCR_2_FCTBCtrlA "FCTB Control Acceleration";
CM_ SG_ 1062 FLCR_2_FCTAFCTBONOFFSts "FCTA/FCTB Switch status";
CM_ SG_ 1067 FRCR_1_CRC1 "Profile1A:E2E CRC (SAE J1850 CRC-8) for 8 Bytes
DataID:0x0042";
CM_ SG_ 1067 FRCR_1_RollgCntr1 "Profile1A:E2E Rolling message counter(the maximum value of Alive counter is 14)";
CM_ SG_ 1067 FRCR_1_Resd1 "Profile1A:E2E Reserved";
CM_ SG_ 1067 FRCR_1_SysSt "System self-test State";
CM_ SG_ 1067 FRCR_1_BlkSts "Blockage Status";
CM_ SG_ 1077 FRCR_2_FCTAWarn "FCTA Warning";
CM_ SG_ 1077 FRCR_2_FCTBWarn "FCTB Warning";
CM_ SG_ 1095 RLCR_1_CRC1 "Profile1A:E2E CRC (SAE J1850 CRC-8) for 8 Bytes
DataID:0x0044";
CM_ SG_ 1095 RLCR_1_RollgCntr1 "Profile1A:E2E Rolling message counter(the maximum value of Alive counter is 14)";
CM_ SG_ 1095 RLCR_1_Resd1 "Profile1A:E2E Reserved";
CM_ SG_ 1095 RLCR_1_SysSt "System self-test State";
CM_ SG_ 1095 RLCR_1_BlkSts "Blockage Status";
CM_ SG_ 1095 RLCR_1_BSDWarn "BSD/LCA Warning";
CM_ SG_ 1095 RLCR_1_DOWWarn "Door open warning Warning";
CM_ SG_ 1095 RLCR_1_DowLock "Door locking Warning";
CM_ SG_ 1095 RLCR_1_ELK_Collision_flag "低配用";
CM_ SG_ 1095 RLCR_1_ELK_CollisionFlagValid "低配用";
CM_ SG_ 1104 RLCR_2_CRC1 "Profile1A:E2E CRC (SAE J1850 CRC-8) for 8 Bytes
DataID:0x0045";
CM_ SG_ 1104 RLCR_2_RollgCntr1 "Profile1A:E2E Rolling message counter(the maximum value of Alive counter is 14)";
CM_ SG_ 1104 RLCR_2_Resd1 "Profile1A:E2E Reserved";
CM_ SG_ 1104 RLCR_2_RCWWarn "Rear Collision Warning Warning";
CM_ SG_ 1104 RLCR_2_RCTAWarn "RCTA Warning";
CM_ SG_ 1104 RLCR_2_RCTBWarn "RCTB Warning";
CM_ SG_ 1104 RLCR_2_RCTBReq "RCTBRequest";
CM_ SG_ 1104 RLCR_2_RCTBCtrlA "RCTB Control Acceleration";
CM_ SG_ 1104 RLCR_2_BSDLCWONOFFSts "BSD/LCA Switch status";
CM_ SG_ 1104 RLCR_2_DOWONOFFSts "Door open warning Switch status";
CM_ SG_ 1104 RLCR_2_RCWONOFFSts "Rear Collision Warning Switch Status";
CM_ SG_ 1104 RLCR_2_RCTARCTBONOFFSts "RCTA/RCTB Switch status";
CM_ SG_ 1267 RRCR_1_CRC1 "Profile1A:E2E CRC (SAE J1850 CRC-8) for 8 Bytes
DataID:0x0046";
CM_ SG_ 1267 RRCR_1_RollgCntr1 "Profile1A:E2E Rolling message counter(the maximum value of Alive counter is 14)";
CM_ SG_ 1267 RRCR_1_Resd1 "Profile1A:E2E Reserved";
CM_ SG_ 1267 RRCR_1_SysSt "System self-test State";
CM_ SG_ 1267 RRCR_1_BlkSts "Blockage Status";
CM_ SG_ 1267 RRCR_1_BSDWarn "BSD/LCA Warning";
CM_ SG_ 1267 RRCR_1_DOWWarn "Door open warning Warning";
CM_ SG_ 1267 RRCR_1_DowLock "Door locking Warning";
CM_ SG_ 1267 RRCR_1_ELK_Collision_flag "低配用";
CM_ SG_ 1267 RRCR_1_ELK_CollisionFlagValid "低配用";
CM_ SG_ 1271 RRCR_2_RCTAWarn "RCTA Warning";
CM_ SG_ 1271 RRCR_2_RCTBWarn "RCTB Warning";
CM_ SG_ 1252 TotalOdometer_km_OBD "GB18285-2018新增OBD输出检查要求车辆累积行驶里程信号。";
CM_ SG_ 1252 DisplayVehicleSpeed "仪表显示的车速，比实际车速略大。";
CM_ SG_ 1296 CurrentTimeYear "GPS时间（年）";
CM_ SG_ 1296 CurrentTimeMonth "GPS时间（月）";
CM_ SG_ 1296 CurrentTimeDay "GPS时间（日）";
CM_ SG_ 1296 CurrentTimeHour "GPS时间（时）";
CM_ SG_ 1296 CurrentTimeMinute "GPS时间（分）";
CM_ SG_ 1296 CurrentTimeSecond "GPS时间（秒）";
CM_ SG_ 1150 ICC_BD_11_CRC "Profile1A:E2E CRC (SAE J1850 CRC-8) for 8 Bytes
DataID:0x009E";
CM_ SG_ 1150 ICC_BD_11_RollgCntr "Profile1A:E2E Rolling message counter(the maximum value of Alive counter is 14)";
CM_ SG_ 1150 ICC_DriveDrosinessLevel "0x0: not available;驾驶员在位检测输出“不在位”的时候触发
0x1: unknown;驾驶员不疲劳的默认状态
0x2: not fatigue;驾驶员不疲劳
0x3: lightly fatigue轻度疲劳,;
0x4: moderate fatigue中度疲劳;
0x5: severe fatigue重度疲劳;
0x6:Driver unresponsive驾驶员无响应;
0x7:Reserved";
CM_ SG_ 1157 ICC_DA_15_CRC "Profile1A:E2E CRC (SAE J1850 CRC-8) for 8 Bytes
DataID:0x009D";
CM_ SG_ 1157 ICC_DA_15_RollgCntr "Profile1A:E2E Rolling message counter(the maximum value of Alive counter is 14)";
CM_ SG_ 1157 ICC_DA_15_Resd "Profile1A:E2E Reserved";
CM_ SG_ 1157 ICC_DA_15_BSDLCWSettingSt "BSD/LCA function setting button status
触发一次快发三帧有效，之后返回0x0:Not Active";
CM_ SG_ 1157 ICC_DA_15_DOWSettingSt "Door open warning function setting button status
触发一次快发三帧有效，之后返回0x0:Not Active";
CM_ SG_ 1157 ICC_DA_15_RCWSettingSt "Rear Collision Warning function setting button status";
CM_ SG_ 1157 ICC_DA_15_RCTARCTBWarnType "RCTA/RCTB function setting button status
触发一次快发三帧有效，之后返回0x0:Not Active";
CM_ SG_ 1157 ICC_DA_15_FCTAFCTBWarnType "FCTA/FCTB function setting button status
触发一次快发三帧有效，之后返回0x0:Not Active";
CM_ SG_ 1157 ICC_DA_15_FrontPDCMuteSet "前PDC、侧PDC声音开关";
CM_ SG_ 1157 ICC_DA_15_FKPMuteSet "侧PDC声音开关";
CM_ SG_ 1157 ICC_PDCOnOffSet "雷达开关
触发一次快发三帧有效，之后返回0x0:Not Active";
CM_ SG_ 1157 Driver_EyeOnRoad "indicate Driver Eyes On Road status";
CM_ SG_ 1157 Dms_Status "DMS(Driver Monitor System) Status
驾驶员监测状态";
CM_ SG_ 1157 Driver_AbnormalBehavior "Driver Abnormal Behavior detection result
非正常行为";
CM_ SG_ 1157 Driver_GazeRegion "Driver Gaze Region
凝视的区域";
CM_ SG_ 1157 Dms_DriverPresence "indicate Driver Presence detection status
未检测到驾驶员";
CM_ SG_ 1157 ICC_IHCfunctionSw "智能远光辅助开关
触发一次快发三帧有效，之后返回0x0:Not Active";
CM_ SG_ 1157 ICC_DistractionStatus "分心提示";
CM_ SG_ 1157 ICC_DA_15_BSDLCWSettingSt_AFS "报警形式选择
触发一次快发三帧有效，之后返回0x0:Not Active";
CM_ SG_ 1157 Dms_MoutOpen "the mouth status
反馈闭嘴状态";
CM_ SG_ 1157 Dms_EyeOpen "the eye status
反馈闭眼状态";
CM_ SG_ 1157 Dms_EyeOccl "the eye Occlusion status
反馈眼部遮挡状态";
CM_ SG_ 1279 ICC_SentinelModeSts "哨兵模式开启/关闭的状态";
CM_ SG_ 1279 ICC_CameraErrorCode "ICC侧Camera链路错误码";
CM_ SG_ 1279 ICC_SentinelRequest "哨兵模式进入，退出请求";
CM_ SG_ 1279 ICC_StartDeInitCameraStream "ICC通知ADCC开始关闭Camera视频流
触发一次快发三帧有效，之后返回0x0:Not Active";
CM_ SG_ 1279 ICC_CameraRecoveryRequest "ICC通知ADCC恢复Camera视频链路";
CM_ SG_ 1265 OtaDwnLoad "request ota software package download
请求开启或者关闭OTA软件包下载";
CM_ SG_ 1265 ICC_LightMainSwitchSts "小灯、近光、Auto开关
触发一次快发三帧有效，之后返回0x0:Not Active";
CM_ SG_ 1265 ICC_HeadlampHeightSts "大灯高度调节设置信号
触发一次快发三帧有效，之后返回0x0:Not Active";
CM_ BO_ 1497 "触发一次发送三帧有效+三帧 Not Active";
CM_ SG_ 1497 ADASLightSwt "Advanced Driver Assistance Systems Light Switch
高级辅助驾驶系统灯开关（小蓝灯）";
CM_ SG_ 1208 PPMID_1_HWSt "Haptic warming status/震动提醒的状态";
CM_ SG_ 1208 PPMID_1_PPSt "Pre-pretension status/预预紧的状态";
CM_ SG_ 1208 PPMID_1_PPMICounter "PPMI counter/寿命计数状态";
CM_ SG_ 1208 PPMID_1_PPMISt "PPMI status/ PPMI是否有故障";
CM_ SG_ 582 PDC_1_CRC1 "Profile1A:E2E CRC (SAE J1850 CRC-8) for 8 Bytes
DataID:No ASIL requirements.Not configure
CRC Reserved.";
CM_ SG_ 582 PDC_1_RollgCntr1 "Profile1A:E2E Rolling message counter(the maximum value of Alive counter is 14)";
CM_ SG_ 582 PDC_1_Resd1 "Profile1A:E2E Reserved";
CM_ SG_ 582 PDC_1_FOLDistance "Front Outter Left sensor zone distance
FOL倒车雷达距离";
CM_ SG_ 582 PDC_1_FOLZoneStatus "Front Outter Left sensor zone alarm
FOL倒车雷达区域报警";
CM_ SG_ 582 PDC_1_FMLDistance "Front Middle Left sensor zone distance
FIL倒车雷达距离";
CM_ SG_ 582 PDC_1_FMLZoneStatus "Front Middle Left sensor zone alarm
FIL倒车雷达区域报警";
CM_ SG_ 582 PDC_1_FMRDistance "Front Middle Right sensor zone distance
FMR倒车雷达距离";
CM_ SG_ 582 PDC_1_FMRZoneStatus "Front Middle Rear sensor zone alarm
FMR倒车雷达区域报警";
CM_ SG_ 582 PDC_1_FORDistance "Front Outter Right sensor zone distance
FOR倒车雷达边距离";
CM_ SG_ 582 PDC_1_CRC2 "Profile1A:E2E CRC (SAE J1850 CRC-8) for 8 Bytes
DataID:No ASIL requirements.Not configure
CRC Reserved.";
CM_ SG_ 582 PDC_1_RollgCntr2 "Profile1A:E2E Rolling message counter(the maximum value of Alive counter is 14)";
CM_ SG_ 582 PDC_1_Resd2 "Profile1A:E2E Reserved";
CM_ SG_ 582 PDC_1_FORZoneStatus "Front Outter Right sensor zone alarm
FOR倒车雷达区域报警";
CM_ SG_ 582 PDC_1_ROLDistance "Rear Outter Left sensor zone distance
ROL倒车雷达距离";
CM_ SG_ 582 PDC_1_ROLZoneStatus "Rear Outter Left sensor zone alarm
ROL倒车雷达区域报警";
CM_ SG_ 582 PDC_1_RMLDistance "Rear Middle Left sensor zone distance
RIL倒车雷达距离";
CM_ SG_ 582 PDC_1_RMLZoneStatus "Rear Middle Left sensor zone alarm
RIL倒车雷达区域报警";
CM_ SG_ 582 PDC_1_RMRDistance "Rear Middle Right sensor zone distance
RMR倒车雷达距离";
CM_ SG_ 582 PDC_1_RMRZoneStatus "Rear Middle Rear sensor zone alarm
RMR倒车雷达区域报警";
CM_ SG_ 582 PDC_1_CRC3 "Profile1A:E2E CRC (SAE J1850 CRC-8) for 8 Bytes
DataID:No ASIL requirements.Not configure
CRC Reserved.";
CM_ SG_ 582 PDC_1_RollgCntr3 "Profile1A:E2E Rolling message counter(the maximum value of Alive counter is 14)";
CM_ SG_ 582 PDC_1_Resd3 "Profile1A:E2E Reserved";
CM_ SG_ 582 PDC_1_RORDistance "Rear Outter Right sensor zone distance
ROR倒车雷达边距离";
CM_ SG_ 582 PDC_1_RORZoneStatus "Rear Outter Right sensor zone alarm
ROR倒车雷达区域报警";
CM_ SG_ 582 PDC_1_LSFDistance "Left Side Front sensor zone distance
左前边倒车雷达距离";
CM_ SG_ 582 PDC_1_LSFZoneStatus "Left Side Front sensor zone alarm
左前边倒车雷达区域报警";
CM_ SG_ 582 PDC_1_FKPLSFMDistance "Left Front Side Middle flank zone distance
左前边中间区域距离";
CM_ SG_ 582 PDC_1_FKPLSFMZoneStatus "Left Front Side Middle flank zone alarm
左前边中间区报警";
CM_ SG_ 582 PDC_1_FKPLSRMDistance "Left Rear Side Middle flank zone distance
左后边中间区域距离";
CM_ SG_ 582 PDC_1_CRC4 "Profile1A:E2E CRC (SAE J1850 CRC-8) for 8 Bytes
DataID:No ASIL requirements.Not configure
CRC Reserved.";
CM_ SG_ 582 PDC_1_RollgCntr4 "Profile1A:E2E Rolling message counter(the maximum value of Alive counter is 14)";
CM_ SG_ 582 PDC_1_Resd4 "Profile1A:E2E Reserved";
CM_ SG_ 582 PDC_1_FKPLSRMZoneStatus "Left Rear Side Middle flank zone alarm
左后边中间区报警";
CM_ SG_ 582 PDC_1_LSRDistance "Left Side Rear sensor zone distance
左后边倒车雷达距离";
CM_ SG_ 582 PDC_1_LSRZoneStatus "Left Side Rear sensor zone alarm
左后边倒车雷达区域报警";
CM_ SG_ 582 PDC_1_RSFDistance "Right Side Front sensor zone distance
右前边倒车雷达距离";
CM_ SG_ 582 PDC_1_RSFZoneStatus "Right Side Front sensor zone alarm
右前边倒车雷达区域报警";
CM_ SG_ 582 PDC_1_FKPRSFMDistance "Right Front Side Middle flank zone distance
右前边中间区域距离";
CM_ SG_ 582 PDC_1_FKPRSFMZoneStatus "Right Front Side Middle flank zone alarm
右前边中间区报警";
CM_ SG_ 582 PDC_1_CRC5 "Profile1A:E2E CRC (SAE J1850 CRC-8) for 8 Bytes
DataID:No ASIL requirements.Not configure
CRC Reserved.";
CM_ SG_ 582 PDC_1_RollgCntr5 "Profile1A:E2E Rolling message counter(the maximum value of Alive counter is 14)";
CM_ SG_ 582 PDC_1_Resd5 "Profile1A:E2E Reserved";
CM_ SG_ 582 PDC_1_FKPRSRMDistance "Right Rear Side Middle flank zone distance
右后边中间区域距离";
CM_ SG_ 582 PDC_1_FKPRSRMZoneStatus "Right Rear Side Middle flank zone alarm
右后边中间区报警";
CM_ SG_ 582 PDC_1_RSRDistance "Right Side Rear sensor zone distance
右后边倒车雷达距离";
CM_ SG_ 582 PDC_1_RSRZoneStatus "Right Side Rear sensor zone alarm
右后边倒车雷达区域报警";
CM_ SG_ 582 PDC_1_ParKASSStatus "PDC function status
 PDC功能状态";
CM_ SG_ 582 PDC_1_PASTrailerHitchDetected "PAS_TrailerHitchDetected
 PAS检测到拖车钩信号";
CM_ SG_ 582 PDC_1_PDCSwFdbk "泊车辅助功能开关反馈";
CM_ SG_ 582 PDC_1_FrontWarningType "蜂鸣器报警信号";
CM_ SG_ 582 PDC_1_RearWarningType "蜂鸣器报警信号";
CM_ SG_ 582 PDC_1_LeftSideWarningType "蜂鸣器报警信号";
CM_ SG_ 582 PDC_1_RightSideWarningType "蜂鸣器报警信号";
CM_ SG_ 582 PDC_1_CRC6 "Profile1A:E2E CRC (SAE J1850 CRC-8) for 8 Bytes
DataID:No ASIL requirements.Not configure
CRC Reserved.";
CM_ SG_ 582 PDC_1_RollgCntr6 "Profile1A:E2E Rolling message counter(the maximum value of Alive counter is 14)";
CM_ SG_ 582 PDC_1_Resd6 "Profile1A:E2E Reserved";
CM_ SG_ 582 PDC_1_STATSensorState "0x0:Sensor normal
0x1:FOL sensor error
0x2:FML sensor error
0x4:FMR sensor error
0x8:FOR sensor error
0x10:FSR sensor error
0x20:RSR sensor error
0x40:ROR sensor error
0x80: RMR sensor error
0x100:RML sensor error
0x200:ROL sensor error
0x400:RSL sensor error
0x800:FSL sensor error";
CM_ SG_ 1231 FuncReq_DepartureSdl "因一键备车启动网络";
CM_ SG_ 1231 AVP_FuncReq "代客泊车功能请求
AVP function request";
CM_ SG_ 1231 FBLPowerHold "刷写挡位保持状态
OTA status
0x0:刷写档位保持请求信号无效
0x1:刷写档位保持请求信号有效
0x2:Reserved
0x3:Invalid";
CM_ SG_ 1199 TCM_1_TrailerSts "Trailer Status send by TCM. Vehicle can use this information to turn off/on some assistance like 'Park Distance Control'. Furthermore it might be used to turn off the fog light on the vehicle when a trailer is connected (at least in germany, there is a law saying that the vehicles fog lamp must not be turned on when a trailer is connected - only the fog of the trailer should be turned on).";
CM_ SG_ 1184 TMInletWaterTemp "Motor Inlet Water Temperature
电机进水口温度";
CM_ SG_ 1207 WPump3Duty_FB "Water Pump3 Duty Feedback
电机水泵3工作占空比反馈";
CM_ SG_ 1207 WPump3FltSt "Water Pump3 Fail Status
电机水泵3故障状态";
CM_ SG_ 1035 VCC_1_CarMode "Car mode
车辆模式
0x0:正常模式
0x1:工厂模式
0x2:运输模式
0x3:转新模式(ICE)
0x4:碰撞模式(ICE)
0x5:工厂暂停(ICE)
0x6:运输暂停(ICE)";
CM_ SG_ 1035 VCC_1_DriveMode "驾驶模式状态信号";
CM_ SG_ 1136 VCC_3_CRC "Profile1A:E2E CRC (SAE J1850 CRC-8) for 32 Bytes
DataID:0x0070";
CM_ SG_ 1136 VCC_3_RollgCntr "Profile1A:E2E Rolling message counter(the maximum value of Alive counter is 14)";
CM_ SG_ 1136 VCC_3_SN "Message ID信号值.当VCC成功被写入配置信息时，VCC以100ms的周期滚动发送报文，Message ID信号值从1到32循环发送。";
CM_ SG_ 1282 ADCC_TotalFaultNum "当前故障总数";
CM_ SG_ 1282 ADCC_FrameIndex "帧序号";
CM_ SG_ 1282 ADCC_SupplierNum "供应商代码";
CM_ SG_ 1282 ADCC_FaultNum1 "故障列表1";
CM_ SG_ 1282 ADCC_FaultNum2 "故障列表2";
CM_ SG_ 1282 ADCC_FaultNum3 "故障列表3";
CM_ SG_ 1282 ADCC_FaultNum4 "故障列表4";
CM_ SG_ 1282 ADCC_FaultNum5 "故障列表5";
CM_ SG_ 1282 ADCC_FaultNum6 "故障列表6";
CM_ SG_ 1282 ADCC_FaultNum7 "故障列表7";
CM_ SG_ 1282 ADCC_FaultNum8 "故障列表8";
CM_ SG_ 1282 ADCC_FaultNum9 "故障列表9";
CM_ SG_ 1282 ADCC_FaultNum10 "故障列表10";
CM_ SG_ 1282 ADCC_FaultNum11 "故障列表11";
CM_ SG_ 1282 ADCC_FaultNum12 "故障列表12";
CM_ SG_ 1282 ADCC_FaultNum13 "故障列表13";
CM_ SG_ 1282 ADCC_FaultNum14 "故障列表14";
CM_ SG_ 1282 ADCC_FaultNum15 "故障列表15";
CM_ SG_ 1282 ADCC_FaultNum16 "故障列表16";
CM_ SG_ 1282 ADCC_FaultNum17 "故障列表17";
CM_ SG_ 1282 ADCC_FaultNum18 "故障列表18";
CM_ SG_ 1282 ADCC_FaultNum19 "故障列表19";
CM_ SG_ 1282 ADCC_FaultNum20 "故障列表20";
CM_ SG_ 1601 RMR_ADCC "If set to 1 to force the network management of all other nodes on the bus into the re-peat message state.";
CM_ SG_ 1601 ADCC_Wakeup_Poweron "Wakeup Source1 Reserved";
CM_ SG_ 1601 ADCC_Wakeup_NM "NM报文";
CM_ SG_ 1601 ADCC_Wakeup_Diag "Wakeup Source3 Reserved";
CM_ SG_ 1601 ADCC_Wakeup_KL15 "KL15 ON";
CM_ SG_ 1601 ADCC_Awake_Poweron "PowerMode ON";
CM_ SG_ 1601 ADCC_Awake_NM "Awake Reason2 Reserved";
CM_ SG_ 1601 ADCC_Awake_Diag "接收到本部件相关的诊断报文";
CM_ SG_ 1601 ADCC_Awake_Upload "闲时上传功能";
CM_ SG_ 1601 ADCC_Awake_KL15 "KL15 ON";
CM_ SG_ 1601 ADCC_Awake_Startup "因ADCC启动需高压液冷请求网络";
CM_ SG_ 1601 ADCC_Awake_DOWAfterRun "因DOW后运行请求网络";
CM_ BO_ 1975 "8~64字节自适应";
CM_ BO_ 1847 "8~64字节自适应";
BA_DEF_ BO_  "NmMessage" ENUM  "No","Yes";
BA_DEF_ BO_  "GenMsgSendType" ENUM  "Cyclic","Event","IfActive","CE","CA","NoMsgSendType";
BA_DEF_ BO_  "GenMsgCycleTime" INT 0 0;
BA_DEF_ SG_  "GenSigSendType" ENUM  "Cyclic","OnChange","OnWrite","IfActive","OnChangeWithRepetition","OnWriteWithRepetition","IfActiveWithRepetition","NoSigSendType","OnChangeAndIfActive","OnChangeAndIfActiveWithRepetition","CA","CE","Event";
BA_DEF_ SG_  "GenSigStartValue" INT 0 0;
BA_DEF_ BO_  "GenMsgCycleTimeFast" INT 0 0;
BA_DEF_ BO_  "GenMsgNrOfRepetition" INT 0 0;
BA_DEF_ BO_  "GenMsgDelayTime" INT 0 0;
BA_DEF_  "DBName" STRING ;
BA_DEF_ BO_  "CANFD_BRS" ENUM  "0","1";
BA_DEF_ BO_  "VFrameFormat" ENUM  "StandardCAN","ExtendedCAN","reserved","reserved","reserved","reserved","reserved","reserved","reserved","reserved","reserved","reserved","reserved","reserved","StandardCAN_FD","ExtendedCAN_FD";
BA_DEF_  "NmMessageCount" INT 0 255;
BA_DEF_ BO_  "GenMsgILSupport" ENUM  "No","Yes";
BA_DEF_  "NmBaseAddress" HEX 1024 1087;
BA_DEF_  "BusType" STRING ;
BA_DEF_ SG_  "GenSigASIL" ENUM  "QM","A","B","C","D","vector_leerstring";
BA_DEF_DEF_  "NmMessage" "No";
BA_DEF_DEF_  "GenMsgSendType" "Cyclic";
BA_DEF_DEF_  "GenMsgCycleTime" 0;
BA_DEF_DEF_  "GenSigSendType" "Cyclic";
BA_DEF_DEF_  "GenSigStartValue" 0;
BA_DEF_DEF_  "GenMsgCycleTimeFast" 0;
BA_DEF_DEF_  "GenMsgNrOfRepetition" 0;
BA_DEF_DEF_  "GenMsgDelayTime" 0;
BA_DEF_DEF_  "DBName" "";
BA_DEF_DEF_  "CANFD_BRS" "1";
BA_DEF_DEF_  "VFrameFormat" "StandardCAN_FD";
BA_DEF_DEF_  "NmMessageCount" 128;
BA_DEF_DEF_  "GenMsgILSupport" "No";
BA_DEF_DEF_  "NmBaseAddress" 1024;
BA_DEF_DEF_  "BusType" "CAN FD";
BA_DEF_DEF_  "GenSigASIL" "QM";
BA_ "DBName" "E0XProjectADCC_DA_J6PMessagelist";
BA_ "GenMsgCycleTime" BO_ 871 50;
BA_ "GenMsgILSupport" BO_ 871 1;
BA_ "GenMsgCycleTime" BO_ 901 50;
BA_ "GenMsgILSupport" BO_ 901 1;
BA_ "GenMsgDelayTime" BO_ 1301 5;
BA_ "GenMsgNrOfRepetition" BO_ 1301 1;
BA_ "GenMsgCycleTimeFast" BO_ 1301 20;
BA_ "GenMsgCycleTime" BO_ 1301 500;
BA_ "GenMsgILSupport" BO_ 1301 1;
BA_ "GenMsgCycleTime" BO_ 783 50;
BA_ "GenMsgILSupport" BO_ 783 1;
BA_ "GenMsgCycleTime" BO_ 788 50;
BA_ "GenMsgILSupport" BO_ 788 1;
BA_ "GenMsgCycleTime" BO_ 794 50;
BA_ "GenMsgILSupport" BO_ 794 1;
BA_ "GenMsgCycleTime" BO_ 1037 100;
BA_ "GenMsgILSupport" BO_ 1037 1;
BA_ "GenMsgCycleTime" BO_ 1217 100;
BA_ "GenMsgILSupport" BO_ 1217 1;
BA_ "GenMsgCycleTime" BO_ 776 50;
BA_ "GenMsgILSupport" BO_ 776 1;
BA_ "GenMsgCycleTime" BO_ 1291 500;
BA_ "GenMsgILSupport" BO_ 1291 1;
BA_ "GenMsgCycleTime" BO_ 1295 500;
BA_ "GenMsgILSupport" BO_ 1295 1;
BA_ "GenMsgDelayTime" BO_ 852 5;
BA_ "GenMsgNrOfRepetition" BO_ 852 10;
BA_ "GenMsgCycleTimeFast" BO_ 852 50;
BA_ "GenMsgCycleTime" BO_ 852 50;
BA_ "GenMsgSendType" BO_ 852 3;
BA_ "GenMsgILSupport" BO_ 852 1;
BA_ "GenMsgCycleTime" BO_ 879 50;
BA_ "GenMsgILSupport" BO_ 879 1;
BA_ "GenMsgDelayTime" BO_ 1191 5;
BA_ "GenMsgNrOfRepetition" BO_ 1191 5;
BA_ "GenMsgCycleTimeFast" BO_ 1191 100;
BA_ "GenMsgCycleTime" BO_ 1191 100;
BA_ "GenMsgSendType" BO_ 1191 3;
BA_ "GenMsgILSupport" BO_ 1191 1;
BA_ "GenMsgNrOfRepetition" BO_ 672 10;
BA_ "GenMsgCycleTimeFast" BO_ 672 20;
BA_ "GenMsgCycleTime" BO_ 672 20;
BA_ "GenMsgSendType" BO_ 672 3;
BA_ "GenMsgILSupport" BO_ 672 1;
BA_ "GenMsgCycleTime" BO_ 1143 100;
BA_ "GenMsgILSupport" BO_ 1143 1;
BA_ "GenMsgCycleTime" BO_ 1172 100;
BA_ "GenMsgILSupport" BO_ 1172 1;
BA_ "GenMsgCycleTime" BO_ 1188 100;
BA_ "GenMsgILSupport" BO_ 1188 1;
BA_ "GenMsgCycleTime" BO_ 884 50;
BA_ "GenMsgILSupport" BO_ 884 1;
BA_ "GenMsgCycleTime" BO_ 1138 100;
BA_ "GenMsgILSupport" BO_ 1138 1;
BA_ "GenMsgCycleTime" BO_ 321 10;
BA_ "GenMsgILSupport" BO_ 321 1;
BA_ "GenMsgCycleTime" BO_ 631 20;
BA_ "GenMsgILSupport" BO_ 631 1;
BA_ "GenMsgCycleTime" BO_ 967 50;
BA_ "GenMsgILSupport" BO_ 967 1;
BA_ "GenMsgCycleTime" BO_ 571 20;
BA_ "GenMsgILSupport" BO_ 571 1;
BA_ "GenMsgCycleTime" BO_ 1120 100;
BA_ "GenMsgILSupport" BO_ 1120 1;
BA_ "GenMsgCycleTime" BO_ 1260 100;
BA_ "GenMsgILSupport" BO_ 1260 1;
BA_ "GenMsgCycleTime" BO_ 1181 100;
BA_ "GenMsgILSupport" BO_ 1181 1;
BA_ "GenMsgCycleTime" BO_ 843 50;
BA_ "GenMsgILSupport" BO_ 843 1;
BA_ "GenMsgCycleTime" BO_ 1030 100;
BA_ "GenMsgILSupport" BO_ 1030 1;
BA_ "GenMsgCycleTime" BO_ 1076 100;
BA_ "GenMsgILSupport" BO_ 1076 1;
BA_ "GenMsgDelayTime" BO_ 1071 5;
BA_ "GenMsgNrOfRepetition" BO_ 1071 3;
BA_ "GenMsgCycleTimeFast" BO_ 1071 20;
BA_ "GenMsgCycleTime" BO_ 1071 100;
BA_ "GenMsgSendType" BO_ 1071 3;
BA_ "GenMsgILSupport" BO_ 1071 1;
BA_ "GenMsgCycleTime" BO_ 864 50;
BA_ "GenMsgILSupport" BO_ 864 1;
BA_ "GenMsgCycleTime" BO_ 683 20;
BA_ "GenMsgILSupport" BO_ 683 1;
BA_ "GenMsgCycleTime" BO_ 1316 500;
BA_ "GenMsgILSupport" BO_ 1316 1;
BA_ "GenMsgCycleTime" BO_ 1324 500;
BA_ "GenMsgILSupport" BO_ 1324 1;
BA_ "GenMsgCycleTime" BO_ 1256 100;
BA_ "GenMsgILSupport" BO_ 1256 1;
BA_ "GenMsgCycleTime" BO_ 638 20;
BA_ "GenMsgILSupport" BO_ 638 1;
BA_ "GenMsgDelayTime" BO_ 949 5;
BA_ "GenMsgNrOfRepetition" BO_ 949 3;
BA_ "GenMsgCycleTimeFast" BO_ 949 50;
BA_ "GenMsgCycleTime" BO_ 949 50;
BA_ "GenMsgSendType" BO_ 949 3;
BA_ "GenMsgILSupport" BO_ 949 1;
BA_ "GenMsgDelayTime" BO_ 1028 5;
BA_ "GenMsgNrOfRepetition" BO_ 1028 3;
BA_ "GenMsgCycleTimeFast" BO_ 1028 50;
BA_ "GenMsgCycleTime" BO_ 1028 100;
BA_ "GenMsgSendType" BO_ 1028 3;
BA_ "GenMsgILSupport" BO_ 1028 1;
BA_ "GenMsgDelayTime" BO_ 1270 5;
BA_ "GenMsgNrOfRepetition" BO_ 1270 3;
BA_ "GenMsgCycleTimeFast" BO_ 1270 50;
BA_ "GenMsgCycleTime" BO_ 1270 100;
BA_ "GenMsgSendType" BO_ 1270 3;
BA_ "GenMsgILSupport" BO_ 1270 1;
BA_ "GenMsgCycleTime" BO_ 699 20;
BA_ "GenMsgILSupport" BO_ 699 1;
BA_ "GenMsgCycleTime" BO_ 1258 100;
BA_ "GenMsgILSupport" BO_ 1258 1;
BA_ "GenMsgCycleTime" BO_ 1050 100;
BA_ "GenMsgILSupport" BO_ 1050 1;
BA_ "GenMsgCycleTime" BO_ 1062 100;
BA_ "GenMsgILSupport" BO_ 1062 1;
BA_ "GenMsgCycleTime" BO_ 1067 100;
BA_ "GenMsgILSupport" BO_ 1067 1;
BA_ "GenMsgCycleTime" BO_ 1077 100;
BA_ "GenMsgILSupport" BO_ 1077 1;
BA_ "GenMsgCycleTime" BO_ 1095 100;
BA_ "GenMsgILSupport" BO_ 1095 1;
BA_ "GenMsgCycleTime" BO_ 1104 100;
BA_ "GenMsgILSupport" BO_ 1104 1;
BA_ "GenMsgCycleTime" BO_ 1267 100;
BA_ "GenMsgILSupport" BO_ 1267 1;
BA_ "GenMsgCycleTime" BO_ 1271 100;
BA_ "GenMsgILSupport" BO_ 1271 1;
BA_ "GenMsgCycleTime" BO_ 1252 100;
BA_ "GenMsgILSupport" BO_ 1252 1;
BA_ "GenMsgCycleTime" BO_ 1296 500;
BA_ "GenMsgILSupport" BO_ 1296 1;
BA_ "GenMsgDelayTime" BO_ 1150 5;
BA_ "GenMsgNrOfRepetition" BO_ 1150 3;
BA_ "GenMsgCycleTimeFast" BO_ 1150 50;
BA_ "GenMsgCycleTime" BO_ 1150 100;
BA_ "GenMsgSendType" BO_ 1150 3;
BA_ "GenMsgILSupport" BO_ 1150 1;
BA_ "GenMsgDelayTime" BO_ 1157 5;
BA_ "GenMsgNrOfRepetition" BO_ 1157 3;
BA_ "GenMsgCycleTimeFast" BO_ 1157 50;
BA_ "GenMsgCycleTime" BO_ 1157 100;
BA_ "GenMsgSendType" BO_ 1157 3;
BA_ "GenMsgILSupport" BO_ 1157 1;
BA_ "GenMsgDelayTime" BO_ 1279 5;
BA_ "GenMsgNrOfRepetition" BO_ 1279 3;
BA_ "GenMsgCycleTimeFast" BO_ 1279 50;
BA_ "GenMsgCycleTime" BO_ 1279 100;
BA_ "GenMsgSendType" BO_ 1279 3;
BA_ "GenMsgILSupport" BO_ 1279 1;
BA_ "GenMsgDelayTime" BO_ 1265 5;
BA_ "GenMsgNrOfRepetition" BO_ 1265 3;
BA_ "GenMsgCycleTimeFast" BO_ 1265 100;
BA_ "GenMsgCycleTime" BO_ 1265 100;
BA_ "GenMsgSendType" BO_ 1265 3;
BA_ "GenMsgILSupport" BO_ 1265 1;
BA_ "GenMsgDelayTime" BO_ 1497 5;
BA_ "GenMsgNrOfRepetition" BO_ 1497 3;
BA_ "GenMsgCycleTimeFast" BO_ 1497 20;
BA_ "GenMsgSendType" BO_ 1497 1;
BA_ "GenMsgILSupport" BO_ 1497 1;
BA_ "GenMsgCycleTime" BO_ 1208 100;
BA_ "GenMsgILSupport" BO_ 1208 1;
BA_ "GenMsgCycleTime" BO_ 582 20;
BA_ "GenMsgILSupport" BO_ 582 1;
BA_ "GenMsgDelayTime" BO_ 1231 5;
BA_ "GenMsgNrOfRepetition" BO_ 1231 3;
BA_ "GenMsgCycleTimeFast" BO_ 1231 100;
BA_ "GenMsgCycleTime" BO_ 1231 100;
BA_ "GenMsgSendType" BO_ 1231 3;
BA_ "GenMsgILSupport" BO_ 1231 1;
BA_ "GenMsgCycleTime" BO_ 1199 100;
BA_ "GenMsgILSupport" BO_ 1199 1;
BA_ "GenMsgCycleTime" BO_ 1184 100;
BA_ "GenMsgILSupport" BO_ 1184 1;
BA_ "GenMsgCycleTime" BO_ 1207 100;
BA_ "GenMsgILSupport" BO_ 1207 1;
BA_ "GenMsgCycleTime" BO_ 1035 100;
BA_ "GenMsgILSupport" BO_ 1035 1;
BA_ "GenMsgDelayTime" BO_ 1075 5;
BA_ "GenMsgNrOfRepetition" BO_ 1075 3;
BA_ "GenMsgCycleTimeFast" BO_ 1075 100;
BA_ "GenMsgSendType" BO_ 1075 1;
BA_ "GenMsgILSupport" BO_ 1075 1;
BA_ "GenMsgDelayTime" BO_ 1136 5;
BA_ "GenMsgNrOfRepetition" BO_ 1136 32;
BA_ "GenMsgCycleTimeFast" BO_ 1136 100;
BA_ "GenMsgSendType" BO_ 1136 1;
BA_ "GenMsgILSupport" BO_ 1136 1;
BA_ "GenMsgCycleTime" BO_ 1282 500;
BA_ "GenMsgILSupport" BO_ 1282 1;
BA_ "VFrameFormat" BO_ 1601 0;
BA_ "CANFD_BRS" BO_ 1601 0;
BA_ "GenMsgCycleTime" BO_ 1601 1000;
BA_ "NmMessage" BO_ 1601 1;
BA_ "GenMsgSendType" BO_ 1975 1;
BA_ "GenMsgSendType" BO_ 1847 1;
BA_ "GenSigASIL" SG_ 871 ADS_1_CRC1 5;
BA_ "GenSigASIL" SG_ 871 ADS_1_RollgCntr1 5;
BA_ "GenSigASIL" SG_ 871 ADS_1_Resd1 5;
BA_ "GenSigASIL" SG_ 871 ADS_Chanllenge1 2;
BA_ "GenSigASIL" SG_ 871 ADS_Chanllenge2 2;
BA_ "GenSigASIL" SG_ 871 ADS_ParkingActiveSubFuncSts 2;
BA_ "GenSigASIL" SG_ 871 ADS_RPAIntFunSts 2;
BA_ "GenSigASIL" SG_ 871 RPAOutFunSts 2;
BA_ "GenSigASIL" SG_ 871 RpaStartButSts 2;
BA_ "GenSigASIL" SG_ 871 ADAS_enum_ApaRpaSts 2;
BA_ "GenSigASIL" SG_ 871 ADAS_enum_ParkingQuitInd 2;
BA_ "GenSigASIL" SG_ 871 ADAS_enum_ParkingDriOperateInd 2;
BA_ "GenSigASIL" SG_ 871 ADS_1_CRC2 5;
BA_ "GenSigASIL" SG_ 871 ADS_1_RollgCntr2 5;
BA_ "GenSigASIL" SG_ 871 ADS_1_Resd2 5;
BA_ "GenSigASIL" SG_ 871 ADAS_enum_ParkingPauseInd 2;
BA_ "GenSigASIL" SG_ 871 PrkInSts 2;
BA_ "GenSigASIL" SG_ 871 FrontLeftOutsts 2;
BA_ "GenSigASIL" SG_ 871 FrontRightOutsts 2;
BA_ "GenSigASIL" SG_ 871 FrontStrightOutsts 2;
BA_ "GenSigASIL" SG_ 871 BackLeftOutsts 2;
BA_ "GenSigASIL" SG_ 871 BackRightOutsts 2;
BA_ "GenSigASIL" SG_ 871 BackStrightOutsts 2;
BA_ "GenSigASIL" SG_ 871 FrontLeftParallelOutsts 2;
BA_ "GenSigASIL" SG_ 871 FrontRightParallelOutsts 2;
BA_ "GenSigASIL" SG_ 871 ParkingStopDist 2;
BA_ "GenSigASIL" SG_ 871 ParkingCompleteTime 2;
BA_ "GenSigASIL" SG_ 871 ParkOutDirectionSt 2;
BA_ "GenSigASIL" SG_ 871 ADS_1_CRC3 5;
BA_ "GenSigASIL" SG_ 871 ADS_1_RollgCntr3 5;
BA_ "GenSigASIL" SG_ 871 ADS_1_Resd3 5;
BA_ "GenSigASIL" SG_ 871 ADS_ParkingRemind 2;
BA_ "GenSigASIL" SG_ 871 HPARPAInFunSts 2;
BA_ "GenSigASIL" SG_ 871 HPARPAOutFunSts 2;
BA_ "GenSigASIL" SG_ 871 BAFAFunSts 2;
BA_ "GenSigASIL" SG_ 871 RpaResumeButSts 2;
BA_ "GenSigASIL" SG_ 871 ADS_1_BAFAFrontButSts 2;
BA_ "GenSigASIL" SG_ 871 ADS_1_BAFABacktButSts 2;
BA_ "GenSigASIL" SG_ 871 ADS_1_SelfCheckSt 2;
BA_ "GenSigASIL" SG_ 871 ADS_1_RPASet 2;
BA_ "GenSigASIL" SG_ 871 ADS_1_SlotType 2;
BA_ "GenSigASIL" SG_ 871 ADS_1_ActivateEcall 2;
BA_ "GenSigASIL" SG_ 871 ADS_1_ParkingProgressBarInd 2;
BA_ "GenSigASIL" SG_ 901 ADS_CRC1 5;
BA_ "GenSigASIL" SG_ 901 ADS_RollgCntr1 5;
BA_ "GenSigASIL" SG_ 901 ADS_Resd1 5;
BA_ "GenSigASIL" SG_ 901 ADS_Road_infor_available 5;
BA_ "GenSigASIL" SG_ 901 ADS_Road_Type 5;
BA_ "GenSigASIL" SG_ 901 ADS_Rough_Sta_L 5;
BA_ "GenSigASIL" SG_ 901 ADS_Road_Features_L 5;
BA_ "GenSigASIL" SG_ 901 ADS_LongitudinalDist_L 5;
BA_ "GenSigASIL" SG_ 901 ADS_Rough_Sta_R 5;
BA_ "GenSigASIL" SG_ 901 ADS_Road_Features_R 5;
BA_ "GenSigASIL" SG_ 901 ADS_LongitudinalDist_R 5;
BA_ "GenSigASIL" SG_ 901 ADS_CRC2 5;
BA_ "GenSigASIL" SG_ 901 ADS_RollgCntr2 5;
BA_ "GenSigASIL" SG_ 901 ADS_Resd2 5;
BA_ "GenSigASIL" SG_ 901 ADS_FeatureHight_L 5;
BA_ "GenSigStartValue" SG_ 901 ADS_FeatureHight_L 500;
BA_ "GenSigASIL" SG_ 901 ADS_FeatureHight_R 5;
BA_ "GenSigStartValue" SG_ 901 ADS_FeatureHight_R 500;
BA_ "GenSigASIL" SG_ 901 SpeedBump_0_ID 5;
BA_ "GenSigASIL" SG_ 901 SpeedBump_0_Valid 5;
BA_ "GenSigASIL" SG_ 901 SpeedBump_0_Dx 5;
BA_ "GenSigASIL" SG_ 901 SpeedBump_0_ExistProb 5;
BA_ "GenSigASIL" SG_ 901 SpeedBump_1_ID 5;
BA_ "GenSigASIL" SG_ 901 SpeedBump_1_Valid 5;
BA_ "GenSigASIL" SG_ 901 ADS_CRC3 5;
BA_ "GenSigASIL" SG_ 901 ADS_RollgCntr3 5;
BA_ "GenSigASIL" SG_ 901 ADS_Resd3 5;
BA_ "GenSigASIL" SG_ 901 SpeedBump_1_Dx 5;
BA_ "GenSigASIL" SG_ 901 SpeedBump_1_ExistProb 5;
BA_ "GenSigASIL" SG_ 901 SpeedBump_2_ID 5;
BA_ "GenSigASIL" SG_ 901 SpeedBump_2_Valid 5;
BA_ "GenSigASIL" SG_ 901 SpeedBump_2_Dx 5;
BA_ "GenSigASIL" SG_ 901 SpeedBump_2_ExistProb 5;
BA_ "GenSigASIL" SG_ 901 SpeedBump_3_ID 5;
BA_ "GenSigASIL" SG_ 901 SpeedBump_3_Valid 5;
BA_ "GenSigASIL" SG_ 901 ADS_CRC4 5;
BA_ "GenSigASIL" SG_ 901 ADS_RollgCntr4 5;
BA_ "GenSigASIL" SG_ 901 ADS_Resd4 5;
BA_ "GenSigASIL" SG_ 901 SpeedBump_3_Dx 5;
BA_ "GenSigASIL" SG_ 901 SpeedBump_3_ExistProb 5;
BA_ "GenSigASIL" SG_ 901 SpeedBump_4_ID 5;
BA_ "GenSigASIL" SG_ 901 SpeedBump_4_Valid 5;
BA_ "GenSigASIL" SG_ 901 SpeedBump_4_Dx 5;
BA_ "GenSigASIL" SG_ 901 SpeedBump_4_ExistProb 5;
BA_ "GenSigASIL" SG_ 1301 TimeSync_Type 5;
BA_ "GenSigASIL" SG_ 1301 TimeSync_CRC 5;
BA_ "GenSigASIL" SG_ 1301 TimeSync_SequenceCounter 5;
BA_ "GenSigASIL" SG_ 1301 TimeSync_TimeDomain 5;
BA_ "GenSigASIL" SG_ 1301 TimeSync_UserByte0 5;
BA_ "GenSigASIL" SG_ 1301 TimeSync_SyncTimeSec 5;
BA_ "GenSigASIL" SG_ 1301 TimeSync_OverflowOfSeconds 5;
BA_ "GenSigASIL" SG_ 1301 TimeSync_SGW 5;
BA_ "GenSigASIL" SG_ 1301 TimeSync_Reserved0 5;
BA_ "GenSigASIL" SG_ 1301 TimeSync_SyncTimeNSec 5;
BA_ "GenSigASIL" SG_ 783 ADS_1_CRC1 5;
BA_ "GenSigASIL" SG_ 783 ADS_1_RollgCntr1 5;
BA_ "GenSigASIL" SG_ 783 ADS_1_Resd1 5;
BA_ "GenSigASIL" SG_ 783 ADS_1_FunctionSuppressReq 2;
BA_ "GenSigASIL" SG_ 783 ADS_1_HPASts 2;
BA_ "GenSigASIL" SG_ 783 ADS_1_VPASts 2;
BA_ "GenSigASIL" SG_ 783 ADCC_CameraStreamSts 5;
BA_ "GenSigASIL" SG_ 783 ADCC_CameraErrorCode 5;
BA_ "GenSigASIL" SG_ 783 ADCC_HWRequest 2;
BA_ "GenSigASIL" SG_ 783 ADCC_PP_M_Request 2;
BA_ "GenSigASIL" SG_ 783 ADCC_HighwayZoneState 5;
BA_ "GenSigASIL" SG_ 783 ADCC_CoolingReq 5;
BA_ "GenSigASIL" SG_ 783 ADCC_UploadFlag 5;
BA_ "GenSigASIL" SG_ 783 ADCC_SurroundCameraErrorSts 5;
BA_ "GenSigASIL" SG_ 783 ADCC_SysReadySts 5;
BA_ "GenSigASIL" SG_ 783 ADS_1_APARPASts 5;
BA_ "GenSigASIL" SG_ 783 ADCC_OvertemperatureErrorSts 5;
BA_ "GenSigASIL" SG_ 783 ADCC_CamFOV_HeatReq 5;
BA_ "GenSigASIL" SG_ 788 ADS_2_CRC1 5;
BA_ "GenSigASIL" SG_ 788 ADS_2_RollgCntr1 5;
BA_ "GenSigASIL" SG_ 788 ADS_2_Resd1 5;
BA_ "GenSigASIL" SG_ 788 ADS_2_FunctionSuppressReq 2;
BA_ "GenSigASIL" SG_ 788 ADS_2_HWRequest 2;
BA_ "GenSigASIL" SG_ 788 ADS_2_PP_M_Request 2;
BA_ "GenSigASIL" SG_ 788 ADS_2_AEBStatus 2;
BA_ "GenSigASIL" SG_ 788 ADS_2_ClosingSpeed 2;
BA_ "GenSigASIL" SG_ 788 ADS_2_TTC 2;
BA_ "GenSigASIL" SG_ 788 ADS_2_Object 2;
BA_ "GenSigASIL" SG_ 788 ADS_2_Object_Status 2;
BA_ "GenSigASIL" SG_ 788 ADS_2_FCWStatus 5;
BA_ "GenSigASIL" SG_ 788 FCM_2_SysStatus 2;
BA_ "GenSigASIL" SG_ 788 FCM_2_IHCfunctionSts 5;
BA_ "GenSigASIL" SG_ 788 FCM_2_HazardLightReq 5;
BA_ "GenSigASIL" SG_ 788 FCM_2_HighBeamReq_Cmd 5;
BA_ "GenSigASIL" SG_ 794 ADS_3_CRC1 5;
BA_ "GenSigASIL" SG_ 794 ADS_3_RollgCntr1 5;
BA_ "GenSigASIL" SG_ 794 ADS_3_Resd1 5;
BA_ "GenSigASIL" SG_ 794 ADS_3_ICAStatus 2;
BA_ "GenSigASIL" SG_ 794 ADS_3_ICATextinfo 2;
BA_ "GenSigASIL" SG_ 794 ADS_3_ACCSts 2;
BA_ "GenSigASIL" SG_ 794 ADS_3_DriverHandsoffWarning 2;
BA_ "GenSigASIL" SG_ 794 ADS_3_AESStatus 2;
BA_ "GenSigASIL" SG_ 794 ADS_3_LKSMod 5;
BA_ "GenSigASIL" SG_ 794 ADS_3_LKSSts 5;
BA_ "GenSigASIL" SG_ 794 ADS_3_ELKSts 5;
BA_ "GenSigASIL" SG_ 794 ADS_3_LKSLeftTrackingSt 5;
BA_ "GenSigASIL" SG_ 794 ADS_3_LKSRightTrackingSt 5;
BA_ "GenSigASIL" SG_ 794 ADS_3_ELKLeftActiveSt 5;
BA_ "GenSigASIL" SG_ 794 ADS_3_ELKRightActiveSt 5;
BA_ "GenSigASIL" SG_ 794 ADS_3_RearViewFoldReq 5;
BA_ "GenSigASIL" SG_ 794 ADS_3_CRC2 5;
BA_ "GenSigASIL" SG_ 794 ADS_3_RollgCntr2 5;
BA_ "GenSigASIL" SG_ 794 ADS_3_Resd2 5;
BA_ "GenSigASIL" SG_ 794 ADS_ALCSts 2;
BA_ "GenSigASIL" SG_ 794 ADS_HNOPSts 2;
BA_ "GenSigASIL" SG_ 794 ADS_UNOPSts 2;
BA_ "GenSigASIL" SG_ 794 ADAS_ParkingActiveSubFuncSt 2;
BA_ "GenSigASIL" SG_ 794 ADS_DoorLockReq 5;
BA_ "GenSigASIL" SG_ 794 ADCCFlowReq 5;
BA_ "GenSigASIL" SG_ 1037 ADAS_HornReq 5;
BA_ "GenSigASIL" SG_ 1037 ADAS_RpaPowerOFFReq 5;
BA_ "GenSigASIL" SG_ 1037 ADAS_TurnLightReq 2;
BA_ "GenSigASIL" SG_ 1037 ADAS_HighBeamReq 5;
BA_ "GenSigASIL" SG_ 1037 ADAS_LowBeamReq 5;
BA_ "GenSigASIL" SG_ 1037 ADCC_ADASLightReq 5;
BA_ "GenSigASIL" SG_ 1217 ASU_1_CRC1 5;
BA_ "GenSigASIL" SG_ 1217 ASU_1_RollgCntr1 5;
BA_ "GenSigASIL" SG_ 1217 ASU_1_ASUSysFailrSts 2;
BA_ "GenSigStartValue" SG_ 1217 ASU_1_ASUSysFailrSts 1;
BA_ "GenSigASIL" SG_ 1217 ASU_1_SuspCurrentLvl 2;
BA_ "GenSigASIL" SG_ 1217 ASU_1_ECASSysSts 2;
BA_ "GenSigASIL" SG_ 1217 ASU_1_SuspTmpAdjSts 2;
BA_ "GenSigASIL" SG_ 1217 ASU_1_MaintainMod 2;
BA_ "GenSigASIL" SG_ 1217 ASU_1_ECASErrSts 2;
BA_ "GenSigASIL" SG_ 1217 ASU_1_SuspTarLvl 2;
BA_ "GenSigASIL" SG_ 1217 ASU_1_EasyEntryEna 2;
BA_ "GenSigASIL" SG_ 1217 ASU_1_AutoEasyEntryFb 2;
BA_ "GenSigASIL" SG_ 1217 ASU_1_ECASModeFb 2;
BA_ "GenSigASIL" SG_ 1217 ASU_1_BluetoothManEasyEntryFb 2;
BA_ "GenSigASIL" SG_ 1217 ASU_1_HighwayModFb 2;
BA_ "GenSigASIL" SG_ 1217 ASU_1_CDCErrSts 2;
BA_ "GenSigASIL" SG_ 1217 ASU_1_SuspDampingLvl 2;
BA_ "GenSigASIL" SG_ 776 ASU_2_CRC1 5;
BA_ "GenSigASIL" SG_ 776 ASU_2_RollgCntr1 5;
BA_ "GenSigASIL" SG_ 776 ASU_2_LFHeight 2;
BA_ "GenSigStartValue" SG_ 776 ASU_2_LFHeight 1500;
BA_ "GenSigASIL" SG_ 776 ASU_2_RFHeight 2;
BA_ "GenSigStartValue" SG_ 776 ASU_2_RFHeight 1500;
BA_ "GenSigASIL" SG_ 776 ASU_2_LRHeight 2;
BA_ "GenSigStartValue" SG_ 776 ASU_2_LRHeight 1500;
BA_ "GenSigASIL" SG_ 776 ASU_2_RRHeight 2;
BA_ "GenSigStartValue" SG_ 776 ASU_2_RRHeight 1500;
BA_ "GenSigASIL" SG_ 776 ASU_2_sensorErrorSts 2;
BA_ "GenSigASIL" SG_ 1291 BMS_SOCLight 2;
BA_ "GenSigASIL" SG_ 1295 BMS_ChgWireConnect_LightSts 5;
BA_ "GenSigASIL" SG_ 1295 BMS_Chg_LightSts 5;
BA_ "GenSigASIL" SG_ 852 BNCM_1_WelcomeON 5;
BA_ "GenSigSendType" SG_ 852 BNCM_1_WelcomeON 4;
BA_ "GenSigASIL" SG_ 852 BNCM_1_WALLockRequest 5;
BA_ "GenSigSendType" SG_ 852 BNCM_1_WALLockRequest 4;
BA_ "GenSigASIL" SG_ 852 BNCM_1_UIRUnLockRequest 5;
BA_ "GenSigSendType" SG_ 852 BNCM_1_UIRUnLockRequest 4;
BA_ "GenSigASIL" SG_ 852 BNCM_1_VehicleSearchRequest 5;
BA_ "GenSigSendType" SG_ 852 BNCM_1_VehicleSearchRequest 4;
BA_ "GenSigASIL" SG_ 879 BNCM_4_CRC1 5;
BA_ "GenSigASIL" SG_ 879 BNCM_4_RollgCntr1 5;
BA_ "GenSigASIL" SG_ 879 BNCM_4_Resd1 5;
BA_ "GenSigASIL" SG_ 879 BNCM_4_ChallengeFeedback 2;
BA_ "GenSigASIL" SG_ 879 BNCM_4_RpaDevicefailSts 2;
BA_ "GenSigASIL" SG_ 879 BNCM_4_RpaModReq 2;
BA_ "GenSigASIL" SG_ 879 BNCM_4_ExitAndPowerOff 2;
BA_ "GenSigASIL" SG_ 879 BNCM_4_RpaModselect 2;
BA_ "GenSigASIL" SG_ 879 BNCM_4_RpaBtnSts 2;
BA_ "GenSigASIL" SG_ 879 BNCM_4_StraightInBtnSts 2;
BA_ "GenSigASIL" SG_ 879 BNCM_4_StraightOutBtnSts 2;
BA_ "GenSigASIL" SG_ 879 BNCM_4_RpaBtnCancelSts 2;
BA_ "GenSigASIL" SG_ 879 BNCM_4_PrkOutModSelRmt 2;
BA_ "GenSigASIL" SG_ 879 BNCM_4_HeartbeatSignal 2;
BA_ "GenSigASIL" SG_ 879 BNCM_4_PauseBtn 2;
BA_ "GenSigASIL" SG_ 879 BNCM_4_ResumeBtn 2;
BA_ "GenSigASIL" SG_ 879 BNCM_4_RpaDeviceDisSts 5;
BA_ "GenSigASIL" SG_ 879 BNCM_4_BLEConnSts 5;
BA_ "GenSigASIL" SG_ 879 BNCM_4_BLEErrStatus 5;
BA_ "GenSigASIL" SG_ 1191 BNCM_6_RemoteControl 5;
BA_ "GenSigSendType" SG_ 1191 BNCM_6_RemoteControl 4;
BA_ "GenSigASIL" SG_ 672 BNCM_14_LockButtAct 5;
BA_ "GenSigSendType" SG_ 672 BNCM_14_LockButtAct 4;
BA_ "GenSigASIL" SG_ 672 BNCM_14_UnLockButtAct 5;
BA_ "GenSigSendType" SG_ 672 BNCM_14_UnLockButtAct 4;
BA_ "GenSigASIL" SG_ 672 BNCM_14_RemoteButtAct 5;
BA_ "GenSigSendType" SG_ 672 BNCM_14_RemoteButtAct 4;
BA_ "GenSigASIL" SG_ 1143 DCDC_WorkingMode 2;
BA_ "GenSigASIL" SG_ 1143 OBC_CC_ConnectSts 1;
BA_ "GenSigASIL" SG_ 1172 ExternalTemperature_C 5;
BA_ "GenSigStartValue" SG_ 1172 ExternalTemperature_C 254;
BA_ "GenSigASIL" SG_ 1172 ExternalTemperatureFailSts 5;
BA_ "GenSigASIL" SG_ 1188 TMS_IncarTemp 5;
BA_ "GenSigStartValue" SG_ 1188 TMS_IncarTemp 254;
BA_ "GenSigASIL" SG_ 884 WPump3Duty 5;
BA_ "GenSigASIL" SG_ 1138 SysRefLoopFault 5;
BA_ "GenSigASIL" SG_ 321 CSA_1_CRC 5;
BA_ "GenSigASIL" SG_ 321 CSA_1_RollgCntr 5;
BA_ "GenSigASIL" SG_ 321 CSA_1_Resd 5;
BA_ "GenSigASIL" SG_ 321 GearShiftPos 2;
BA_ "GenSigStartValue" SG_ 321 GearShiftPos 15;
BA_ "GenSigASIL" SG_ 321 GearShiftPosInverse 2;
BA_ "GenSigASIL" SG_ 321 STAT_ParkButton 2;
BA_ "GenSigASIL" SG_ 321 STAT_ShifterLeverFault 2;
BA_ "GenSigASIL" SG_ 321 DriveModeActive 5;
BA_ "GenSigASIL" SG_ 321 DriveModeReq 5;
BA_ "GenSigASIL" SG_ 631 CSA_2_CRC1 5;
BA_ "GenSigASIL" SG_ 631 CSA_2_RollgCntr1 5;
BA_ "GenSigASIL" SG_ 631 CSA_2_Resd1 5;
BA_ "GenSigASIL" SG_ 631 CSA_2_AllWarningInfo 2;
BA_ "GenSigASIL" SG_ 631 CSA_2_TurnSigLvrCmd 2;
BA_ "GenSigASIL" SG_ 631 CSA_2_HiBeamSwtCmd 1;
BA_ "GenSigASIL" SG_ 631 CSA_2_WshrFrntCmd 5;
BA_ "GenSigASIL" SG_ 631 CSA_2_WiprFrntCmd 1;
BA_ "GenSigASIL" SG_ 967 FRM_2_CRC 5;
BA_ "GenSigASIL" SG_ 967 FRM_2_RollgCntr 5;
BA_ "GenSigASIL" SG_ 967 FRM_2_DetnHd_DetnBlockCounter 2;
BA_ "GenSigASIL" SG_ 967 FRM_2_DetnHd_MountPosX 2;
BA_ "GenSigASIL" SG_ 967 FRM_2_DetnHd_MountPosY 2;
BA_ "GenSigStartValue" SG_ 967 FRM_2_DetnHd_MountPosY 250;
BA_ "GenSigASIL" SG_ 967 FRM_2_DetnHd_MountPosZ 2;
BA_ "GenSigASIL" SG_ 967 FRM_2_DetnHd_MountAngleYaw 2;
BA_ "GenSigStartValue" SG_ 967 FRM_2_DetnHd_MountAngleYaw 150;
BA_ "GenSigASIL" SG_ 967 FRM_2_DetnHd_MountAnglePitch 2;
BA_ "GenSigStartValue" SG_ 967 FRM_2_DetnHd_MountAnglePitch 150;
BA_ "GenSigASIL" SG_ 967 FRM_2_DetnHd_MountAngleRoll 2;
BA_ "GenSigStartValue" SG_ 967 FRM_2_DetnHd_MountAngleRoll 150;
BA_ "GenSigASIL" SG_ 967 FRM_2_DetnHd_AlignAglYawErrCurr 2;
BA_ "GenSigStartValue" SG_ 967 FRM_2_DetnHd_AlignAglYawErrCurr 150;
BA_ "GenSigASIL" SG_ 967 FRM_2_DetnHd_AlignAglYawErrEOL 2;
BA_ "GenSigStartValue" SG_ 967 FRM_2_DetnHd_AlignAglYawErrEOL 150;
BA_ "GenSigASIL" SG_ 967 FRM_2_DetnHd_AlignAglPitchErrEOL 2;
BA_ "GenSigStartValue" SG_ 967 FRM_2_DetnHd_AlignAglPitchErrEOL 150;
BA_ "GenSigASIL" SG_ 967 FRM_2_DetnHd_FOVYawAglLower 2;
BA_ "GenSigStartValue" SG_ 967 FRM_2_DetnHd_FOVYawAglLower 900;
BA_ "GenSigASIL" SG_ 967 FRM_2_DetnHd_FOVYawAglUpper 2;
BA_ "GenSigStartValue" SG_ 967 FRM_2_DetnHd_FOVYawAglUpper 900;
BA_ "GenSigASIL" SG_ 967 FRM_2_DetnHd_FOVPitchAglLower 2;
BA_ "GenSigStartValue" SG_ 967 FRM_2_DetnHd_FOVPitchAglLower 400;
BA_ "GenSigASIL" SG_ 967 FRM_2_DetnHd_FOVPitchAglUpper 2;
BA_ "GenSigStartValue" SG_ 967 FRM_2_DetnHd_FOVPitchAglUpper 400;
BA_ "GenSigASIL" SG_ 967 FRM_2_DetnHd_MaxDetectionRange 2;
BA_ "GenSigASIL" SG_ 967 FRM_2_DetnHd_ObjDetFail 2;
BA_ "GenSigASIL" SG_ 967 FRM_2_DetnHd_ValidDetnCount 2;
BA_ "GenSigASIL" SG_ 967 FRM_2_DetnHd_DetnDownSel 2;
BA_ "GenSigASIL" SG_ 967 FRM_2_DetnHd_DetnTimeLatency 2;
BA_ "GenSigASIL" SG_ 571 FLZCU_1_CRC 5;
BA_ "GenSigASIL" SG_ 571 FLZCU_1_RollgCntr 5;
BA_ "GenSigASIL" SG_ 571 FLZCU_1_Resd 5;
BA_ "GenSigASIL" SG_ 571 HoodLockSts 5;
BA_ "GenSigStartValue" SG_ 571 HoodLockSts 3;
BA_ "GenSigASIL" SG_ 571 DrvSeatOccupiedSts 2;
BA_ "GenSigASIL" SG_ 571 LHTurnlightSts 2;
BA_ "GenSigASIL" SG_ 571 RHTurnlightSts 2;
BA_ "GenSigASIL" SG_ 571 HoodSts 1;
BA_ "GenSigASIL" SG_ 571 DrvDoorLockSts 1;
BA_ "GenSigStartValue" SG_ 571 DrvDoorLockSts 3;
BA_ "GenSigASIL" SG_ 571 DrvDoorSts 1;
BA_ "GenSigASIL" SG_ 571 LHTurnSW 5;
BA_ "GenSigASIL" SG_ 571 RHTurnSW 5;
BA_ "GenSigASIL" SG_ 571 HazardLightSW 5;
BA_ "GenSigASIL" SG_ 571 DrvSeatBeltSW 1;
BA_ "GenSigASIL" SG_ 571 DirectionIndLeft 2;
BA_ "GenSigASIL" SG_ 571 DirectionIndRight 2;
BA_ "GenSigASIL" SG_ 571 DrvSeatBeltFaultStatus 1;
BA_ "GenSigASIL" SG_ 1120 FLZCU_3_CRC 5;
BA_ "GenSigASIL" SG_ 1120 FLZCU_3_RollgCntr 5;
BA_ "GenSigASIL" SG_ 1120 RLHS_2_AmbBrightness 5;
BA_ "GenSigASIL" SG_ 1120 RLHS_2_IRBrightness 5;
BA_ "GenSigASIL" SG_ 1120 RLHS_Rainfall 5;
BA_ "GenSigASIL" SG_ 1120 RLHS_LiSwithReason 5;
BA_ "GenSigASIL" SG_ 1260 FLZCU_7_CRC 5;
BA_ "GenSigASIL" SG_ 1260 FLZCU_7_RollgCntr 5;
BA_ "GenSigASIL" SG_ 1260 FLZCU_7_Resd 5;
BA_ "GenSigASIL" SG_ 1260 TrunLightFaults 2;
BA_ "GenSigASIL" SG_ 1181 FLZCU_9_CRC 5;
BA_ "GenSigASIL" SG_ 1181 FLZCU_9_RollgCntr 5;
BA_ "GenSigASIL" SG_ 1181 FLZCU_9_Resd1 5;
BA_ "GenSigASIL" SG_ 1181 FLZCU_9_PowerMode 2;
BA_ "GenSigASIL" SG_ 1181 FLZCU_9_ArmingSts 5;
BA_ "GenSigASIL" SG_ 843 HOD_CRC 5;
BA_ "GenSigASIL" SG_ 843 HOD_RollingCounter 5;
BA_ "GenSigASIL" SG_ 843 HOD_Resd1 5;
BA_ "GenSigASIL" SG_ 843 HOD_OnOffSts 2;
BA_ "GenSigASIL" SG_ 843 HOD_OnOffStsValid 2;
BA_ "GenSigASIL" SG_ 843 HOD_HandOnSts 2;
BA_ "GenSigASIL" SG_ 843 HOD_OneHand_Area 2;
BA_ "GenSigASIL" SG_ 843 HOD_OneHand_AreaValid 2;
BA_ "GenSigASIL" SG_ 843 HOD_LeftArea_Sts 2;
BA_ "GenSigASIL" SG_ 843 HOD_LeftArea_StsVD 2;
BA_ "GenSigASIL" SG_ 843 HOD_RightArea_Sts 2;
BA_ "GenSigASIL" SG_ 843 HOD_RightArea_StsVD 2;
BA_ "GenSigASIL" SG_ 843 HOD_FC_CAP_SENSOR_ERR 2;
BA_ "GenSigASIL" SG_ 843 HOD_FC_ECU_HW_Fault 2;
BA_ "GenSigASIL" SG_ 843 HOD_FC_BAT_LOW 2;
BA_ "GenSigASIL" SG_ 843 HOD_FC_BAT_HIGH 2;
BA_ "GenSigASIL" SG_ 843 HOD_FC_ResponseError 2;
BA_ "GenSigASIL" SG_ 843 HOD_FC_SYSTEM_ERR 2;
BA_ "GenSigASIL" SG_ 1030 FLZCU_12_CRC 5;
BA_ "GenSigASIL" SG_ 1030 FLZCU_12_RollgCntr 5;
BA_ "GenSigASIL" SG_ 1030 FLZCU_FrontWiperParkStatus 1;
BA_ "GenSigASIL" SG_ 1030 FLZCU_FrontWiperWipingStatus 1;
BA_ "GenSigASIL" SG_ 1030 RearViewFoldSts 2;
BA_ "GenSigASIL" SG_ 1076 RLHS_1_FWBrightness 5;
BA_ "GenSigASIL" SG_ 1076 RLHS_TempSensorValue 5;
BA_ "GenSigStartValue" SG_ 1076 RLHS_TempSensorValue 80;
BA_ "GenSigASIL" SG_ 1076 RLHS_TempDewPoint 5;
BA_ "GenSigStartValue" SG_ 1076 RLHS_TempDewPoint 396;
BA_ "GenSigASIL" SG_ 1076 RLHS_Humid_Temp_Error 5;
BA_ "GenSigASIL" SG_ 1071 FLZCU_LightMainSwitchSts 5;
BA_ "GenSigSendType" SG_ 1071 FLZCU_LightMainSwitchSts 4;
BA_ "GenSigASIL" SG_ 1071 FLZCU_FLFoglightSts 5;
BA_ "GenSigASIL" SG_ 1071 FLZCU_FRFoglightSts 5;
BA_ "GenSigASIL" SG_ 1071 FLZCU_RearFogLightSts 5;
BA_ "GenSigASIL" SG_ 1071 FLZCU_LowBeamSts 2;
BA_ "GenSigASIL" SG_ 1071 FLZCU_HighBeamSts 2;
BA_ "GenSigASIL" SG_ 1071 FLZCU_HighBeamFaults 5;
BA_ "GenSigASIL" SG_ 1071 FLZCU_RearFogLightFaults 5;
BA_ "GenSigASIL" SG_ 1071 FLZCU_ParkLightFaults 5;
BA_ "GenSigASIL" SG_ 1071 FLZCU_DaytimeLight 5;
BA_ "GenSigASIL" SG_ 1071 FLZCU_HMASwSts 2;
BA_ "GenSigASIL" SG_ 1071 FLZCU_BrkLightSts 2;
BA_ "GenSigASIL" SG_ 1071 FLZCU_FrontFogLightSts 5;
BA_ "GenSigASIL" SG_ 1071 FLZCU_CamFOV_HeatSts 5;
BA_ "GenSigASIL" SG_ 1071 ADASLightStsFb 5;
BA_ "GenSigASIL" SG_ 1071 ADSLightFaildSts 5;
BA_ "GenSigASIL" SG_ 864 MFS_2_CRC 5;
BA_ "GenSigASIL" SG_ 864 MFS_2_RollgCntr 5;
BA_ "GenSigASIL" SG_ 864 MFS_Cruise_Control 2;
BA_ "GenSigASIL" SG_ 864 MFS_RESPlus 2;
BA_ "GenSigASIL" SG_ 864 MFS_SETMinus 2;
BA_ "GenSigASIL" SG_ 864 MFS_Time_Gap_Reduce 2;
BA_ "GenSigASIL" SG_ 864 MFS_Time_Gap_Add 2;
BA_ "GenSigASIL" SG_ 864 MFS_Rsp_Error 2;
BA_ "GenSigASIL" SG_ 864 MFS_LeftRoller 2;
BA_ "GenSigASIL" SG_ 864 MFS_LeftRollerMiddleKey 2;
BA_ "GenSigASIL" SG_ 864 MFS_LeRollrUpDwnAdjSteps 2;
BA_ "GenSigASIL" SG_ 683 FRZCU_1_CRC 5;
BA_ "GenSigASIL" SG_ 683 FRZCU_1_RollgCntr 5;
BA_ "GenSigASIL" SG_ 683 FRZCU_1_Resd 5;
BA_ "GenSigASIL" SG_ 683 PassDoorSts 1;
BA_ "GenSigASIL" SG_ 683 ParkLightSts 5;
BA_ "GenSigASIL" SG_ 683 PassRearDoorSts 1;
BA_ "GenSigASIL" SG_ 683 PassDoorLockSts 5;
BA_ "GenSigStartValue" SG_ 683 PassDoorLockSts 3;
BA_ "GenSigASIL" SG_ 683 PassRearDoorLockSts 5;
BA_ "GenSigStartValue" SG_ 683 PassRearDoorLockSts 3;
BA_ "GenSigASIL" SG_ 1316 LHFTirePressure 5;
BA_ "GenSigASIL" SG_ 1316 RHFTirePressure 5;
BA_ "GenSigASIL" SG_ 1316 LHRTirePressure 5;
BA_ "GenSigASIL" SG_ 1316 RHRTirePressure 5;
BA_ "GenSigASIL" SG_ 1324 FRZCU_7_CRC 5;
BA_ "GenSigASIL" SG_ 1324 FRZCU_7_RollgCntr 5;
BA_ "GenSigASIL" SG_ 1324 TirePositionWarning_LHFTire 5;
BA_ "GenSigASIL" SG_ 1324 TirePositionWarning_RHFTire 5;
BA_ "GenSigASIL" SG_ 1324 TirePositionWarning_LHRTire 5;
BA_ "GenSigASIL" SG_ 1324 TirePositionWarning_RHRTire 5;
BA_ "GenSigASIL" SG_ 1324 TirePressureWarningLampSts 2;
BA_ "GenSigASIL" SG_ 1324 TirePressureSystemFailSts 2;
BA_ "GenSigASIL" SG_ 1256 LowBeamFaults 2;
BA_ "GenSigASIL" SG_ 638 DrvHandleSwitchSts 5;
BA_ "GenSigASIL" SG_ 638 PassHandleSwitchSts 5;
BA_ "GenSigASIL" SG_ 638 PassRearHandleSwitchSts 5;
BA_ "GenSigASIL" SG_ 638 DrvRearHandleSwitchSts 5;
BA_ "GenSigASIL" SG_ 949 PEPS_InformationSource 5;
BA_ "GenSigASIL" SG_ 949 PEPS_OrderInformation 5;
BA_ "GenSigASIL" SG_ 949 PEPS_KeySts 5;
BA_ "GenSigASIL" SG_ 1028 PEPS_WelcomeON 5;
BA_ "GenSigSendType" SG_ 1028 PEPS_WelcomeON 4;
BA_ "GenSigASIL" SG_ 1028 PEPS_VehicleSearchReq 5;
BA_ "GenSigSendType" SG_ 1028 PEPS_VehicleSearchReq 4;
BA_ "GenSigASIL" SG_ 1028 PEPS_RKETrunkSts 5;
BA_ "GenSigASIL" SG_ 1028 PEPS_UIRUnLockRequest 5;
BA_ "GenSigSendType" SG_ 1028 PEPS_UIRUnLockRequest 4;
BA_ "GenSigASIL" SG_ 1028 PEPS_WALLockRequest 5;
BA_ "GenSigSendType" SG_ 1028 PEPS_WALLockRequest 4;
BA_ "GenSigASIL" SG_ 1270 PEPS_LockButtAct 5;
BA_ "GenSigSendType" SG_ 1270 PEPS_LockButtAct 4;
BA_ "GenSigASIL" SG_ 1270 PEPS_UnLockButtAct 5;
BA_ "GenSigSendType" SG_ 1270 PEPS_UnLockButtAct 4;
BA_ "GenSigASIL" SG_ 1270 PEPS_ParkFrntEna 5;
BA_ "GenSigASIL" SG_ 1270 PEPS_ParkBackEna 5;
BA_ "GenSigASIL" SG_ 1270 PEPS_AVPFctReq 5;
BA_ "GenSigASIL" SG_ 1270 PEPS_AVPActv 5;
BA_ "GenSigASIL" SG_ 1270 PEPS_RpaDeviceDisSts 5;
BA_ "GenSigASIL" SG_ 1270 PEPS_ParkinEna 5;
BA_ "GenSigASIL" SG_ 699 RZCU_2_CRC 5;
BA_ "GenSigASIL" SG_ 699 RZCU_2_RollgCntr 5;
BA_ "GenSigASIL" SG_ 699 RZCU_2_Resd 5;
BA_ "GenSigASIL" SG_ 699 DrvRearDoorSts 1;
BA_ "GenSigASIL" SG_ 699 TrunkSts 1;
BA_ "GenSigASIL" SG_ 699 DrvRearDoorLockSts 5;
BA_ "GenSigStartValue" SG_ 699 DrvRearDoorLockSts 3;
BA_ "GenSigASIL" SG_ 699 TrunkLockSts 5;
BA_ "GenSigStartValue" SG_ 699 TrunkLockSts 3;
BA_ "GenSigASIL" SG_ 1258 RZCU_7_CRC 5;
BA_ "GenSigASIL" SG_ 1258 RZCU_7_RollgCntr 5;
BA_ "GenSigASIL" SG_ 1258 BrkLightFaults 2;
BA_ "GenSigASIL" SG_ 1258 RZCU_RearWiperWipingStatus 1;
BA_ "GenSigASIL" SG_ 1258 RZCU_RearWiperParkStatus 1;
BA_ "GenSigASIL" SG_ 1050 FLCR_1_CRC1 5;
BA_ "GenSigASIL" SG_ 1050 FLCR_1_RollgCntr1 5;
BA_ "GenSigASIL" SG_ 1050 FLCR_1_Resd1 5;
BA_ "GenSigASIL" SG_ 1050 FLCR_1_SysSt 2;
BA_ "GenSigASIL" SG_ 1050 FLCR_1_BlkSts 2;
BA_ "GenSigASIL" SG_ 1062 FLCR_2_CRC1 5;
BA_ "GenSigASIL" SG_ 1062 FLCR_2_RollgCntr1 5;
BA_ "GenSigASIL" SG_ 1062 FLCR_2_Resd1 5;
BA_ "GenSigASIL" SG_ 1062 FLCR_2_FCTAWarn 5;
BA_ "GenSigASIL" SG_ 1062 FLCR_2_FCTBWarn 2;
BA_ "GenSigASIL" SG_ 1062 FLCR_2_FCTBReq 2;
BA_ "GenSigASIL" SG_ 1062 FLCR_2_FCTBCtrlA 2;
BA_ "GenSigStartValue" SG_ 1062 FLCR_2_FCTBCtrlA 1022;
BA_ "GenSigASIL" SG_ 1062 FLCR_2_FCTAFCTBONOFFSts 5;
BA_ "GenSigASIL" SG_ 1067 FRCR_1_CRC1 5;
BA_ "GenSigASIL" SG_ 1067 FRCR_1_RollgCntr1 5;
BA_ "GenSigASIL" SG_ 1067 FRCR_1_Resd1 5;
BA_ "GenSigASIL" SG_ 1067 FRCR_1_SysSt 2;
BA_ "GenSigASIL" SG_ 1067 FRCR_1_BlkSts 2;
BA_ "GenSigASIL" SG_ 1077 FRCR_2_FCTAWarn 5;
BA_ "GenSigASIL" SG_ 1077 FRCR_2_FCTBWarn 2;
BA_ "GenSigASIL" SG_ 1095 RLCR_1_CRC1 5;
BA_ "GenSigASIL" SG_ 1095 RLCR_1_RollgCntr1 5;
BA_ "GenSigASIL" SG_ 1095 RLCR_1_Resd1 5;
BA_ "GenSigASIL" SG_ 1095 RLCR_1_SysSt 2;
BA_ "GenSigASIL" SG_ 1095 RLCR_1_BlkSts 2;
BA_ "GenSigASIL" SG_ 1095 RLCR_1_BSDWarn 5;
BA_ "GenSigASIL" SG_ 1095 RLCR_1_DOWWarn 5;
BA_ "GenSigASIL" SG_ 1095 RLCR_1_DowLock 5;
BA_ "GenSigASIL" SG_ 1095 RLCR_1_ELK_Collision_flag 2;
BA_ "GenSigASIL" SG_ 1095 RLCR_1_ELK_CollisionFlagValid 2;
BA_ "GenSigASIL" SG_ 1104 RLCR_2_CRC1 5;
BA_ "GenSigASIL" SG_ 1104 RLCR_2_RollgCntr1 5;
BA_ "GenSigASIL" SG_ 1104 RLCR_2_Resd1 5;
BA_ "GenSigASIL" SG_ 1104 RLCR_2_RCWWarn 5;
BA_ "GenSigASIL" SG_ 1104 RLCR_2_RCTAWarn 5;
BA_ "GenSigASIL" SG_ 1104 RLCR_2_RCTBWarn 2;
BA_ "GenSigASIL" SG_ 1104 RLCR_2_RCTBReq 2;
BA_ "GenSigASIL" SG_ 1104 RLCR_2_RCTBCtrlA 2;
BA_ "GenSigStartValue" SG_ 1104 RLCR_2_RCTBCtrlA 1022;
BA_ "GenSigASIL" SG_ 1104 RLCR_2_BSDLCWONOFFSts 5;
BA_ "GenSigASIL" SG_ 1104 RLCR_2_DOWONOFFSts 5;
BA_ "GenSigASIL" SG_ 1104 RLCR_2_RCWONOFFSts 5;
BA_ "GenSigASIL" SG_ 1104 RLCR_2_RCTARCTBONOFFSts 5;
BA_ "GenSigASIL" SG_ 1267 RRCR_1_CRC1 5;
BA_ "GenSigASIL" SG_ 1267 RRCR_1_RollgCntr1 5;
BA_ "GenSigASIL" SG_ 1267 RRCR_1_Resd1 5;
BA_ "GenSigASIL" SG_ 1267 RRCR_1_SysSt 2;
BA_ "GenSigASIL" SG_ 1267 RRCR_1_BlkSts 2;
BA_ "GenSigASIL" SG_ 1267 RRCR_1_BSDWarn 5;
BA_ "GenSigASIL" SG_ 1267 RRCR_1_DOWWarn 5;
BA_ "GenSigASIL" SG_ 1267 RRCR_1_DowLock 5;
BA_ "GenSigASIL" SG_ 1267 RRCR_1_ELK_Collision_flag 2;
BA_ "GenSigASIL" SG_ 1267 RRCR_1_ELK_CollisionFlagValid 2;
BA_ "GenSigASIL" SG_ 1271 RRCR_2_RCTAWarn 5;
BA_ "GenSigASIL" SG_ 1271 RRCR_2_RCTBWarn 2;
BA_ "GenSigASIL" SG_ 1252 TotalOdometer_km_OBD 5;
BA_ "GenSigASIL" SG_ 1252 TotalOdometer_km_OBDValidData 5;
BA_ "GenSigASIL" SG_ 1252 DisplayVehicleSpeed 5;
BA_ "GenSigASIL" SG_ 1296 CurrentTimeYear 5;
BA_ "GenSigASIL" SG_ 1296 CurrentTimeMonth 5;
BA_ "GenSigStartValue" SG_ 1296 CurrentTimeMonth 1;
BA_ "GenSigASIL" SG_ 1296 CurrentTimeDay 5;
BA_ "GenSigStartValue" SG_ 1296 CurrentTimeDay 1;
BA_ "GenSigASIL" SG_ 1296 CurrentTimeHour 5;
BA_ "GenSigASIL" SG_ 1296 CurrentTimeMinute 5;
BA_ "GenSigASIL" SG_ 1296 CurrentTimeSecond 5;
BA_ "GenSigASIL" SG_ 1150 ICC_BD_11_CRC 5;
BA_ "GenSigASIL" SG_ 1150 ICC_BD_11_RollgCntr 5;
BA_ "GenSigASIL" SG_ 1150 ICC_DriveDrosinessLevel 1;
BA_ "GenSigASIL" SG_ 1157 ICC_DA_15_CRC 5;
BA_ "GenSigASIL" SG_ 1157 ICC_DA_15_RollgCntr 5;
BA_ "GenSigASIL" SG_ 1157 ICC_DA_15_Resd 5;
BA_ "GenSigASIL" SG_ 1157 ICC_DA_15_BSDLCWSettingSt 5;
BA_ "GenSigSendType" SG_ 1157 ICC_DA_15_BSDLCWSettingSt 5;
BA_ "GenSigASIL" SG_ 1157 ICC_DA_15_DOWSettingSt 5;
BA_ "GenSigSendType" SG_ 1157 ICC_DA_15_DOWSettingSt 5;
BA_ "GenSigASIL" SG_ 1157 ICC_DA_15_RCWSettingSt 5;
BA_ "GenSigSendType" SG_ 1157 ICC_DA_15_RCWSettingSt 5;
BA_ "GenSigASIL" SG_ 1157 ICC_DA_15_RCTARCTBWarnType 5;
BA_ "GenSigStartValue" SG_ 1157 ICC_DA_15_RCTARCTBWarnType 3;
BA_ "GenSigSendType" SG_ 1157 ICC_DA_15_RCTARCTBWarnType 5;
BA_ "GenSigASIL" SG_ 1157 ICC_DA_15_FCTAFCTBWarnType 5;
BA_ "GenSigStartValue" SG_ 1157 ICC_DA_15_FCTAFCTBWarnType 3;
BA_ "GenSigSendType" SG_ 1157 ICC_DA_15_FCTAFCTBWarnType 5;
BA_ "GenSigASIL" SG_ 1157 ICC_DA_15_FrontPDCMuteSet 5;
BA_ "GenSigASIL" SG_ 1157 ICC_DA_15_FKPMuteSet 5;
BA_ "GenSigASIL" SG_ 1157 ICC_DA_15_ExtremeEnergySaveMode 5;
BA_ "GenSigASIL" SG_ 1157 ICC_PDCOnOffSet 5;
BA_ "GenSigSendType" SG_ 1157 ICC_PDCOnOffSet 5;
BA_ "GenSigASIL" SG_ 1157 Driver_EyeOnRoad 2;
BA_ "GenSigASIL" SG_ 1157 Dms_Status 2;
BA_ "GenSigASIL" SG_ 1157 Driver_AbnormalBehavior 5;
BA_ "GenSigASIL" SG_ 1157 Driver_GazeRegion 5;
BA_ "GenSigASIL" SG_ 1157 Dms_DriverPresence 1;
BA_ "GenSigASIL" SG_ 1157 ICC_IHCfunctionSw 5;
BA_ "GenSigSendType" SG_ 1157 ICC_IHCfunctionSw 5;
BA_ "GenSigASIL" SG_ 1157 ICC_DistractionStatus 5;
BA_ "GenSigASIL" SG_ 1157 ICC_DA_15_BSDLCWSettingSt_AFS 5;
BA_ "GenSigSendType" SG_ 1157 ICC_DA_15_BSDLCWSettingSt_AFS 5;
BA_ "GenSigASIL" SG_ 1157 Dms_MoutOpen 5;
BA_ "GenSigASIL" SG_ 1157 Dms_EyeOpen 5;
BA_ "GenSigASIL" SG_ 1157 Dms_EyeOccl 5;
BA_ "GenSigASIL" SG_ 1279 ICC_SentinelModeSts 5;
BA_ "GenSigASIL" SG_ 1279 ICC_CameraErrorCode 5;
BA_ "GenSigASIL" SG_ 1279 ICC_SentinelRequest 5;
BA_ "GenSigASIL" SG_ 1279 ICC_StartDeInitCameraStream 5;
BA_ "GenSigSendType" SG_ 1279 ICC_StartDeInitCameraStream 5;
BA_ "GenSigASIL" SG_ 1279 ICC_CameraRecoveryRequest 5;
BA_ "GenSigSendType" SG_ 1279 ICC_CameraRecoveryRequest 5;
BA_ "GenSigASIL" SG_ 1265 OtaDwnLoad 5;
BA_ "GenSigASIL" SG_ 1265 ICC_LightMainSwitchSts 5;
BA_ "GenSigSendType" SG_ 1265 ICC_LightMainSwitchSts 5;
BA_ "GenSigASIL" SG_ 1265 ICC_HeadlampHeightSts 5;
BA_ "GenSigSendType" SG_ 1265 ICC_HeadlampHeightSts 5;
BA_ "GenSigASIL" SG_ 1497 ADASLightSwt 5;
BA_ "GenSigSendType" SG_ 1497 ADASLightSwt 5;
BA_ "GenSigASIL" SG_ 1208 PPMID_1_HWSt 5;
BA_ "GenSigASIL" SG_ 1208 PPMID_1_PPSt 5;
BA_ "GenSigASIL" SG_ 1208 PPMID_1_PPMICounter 5;
BA_ "GenSigASIL" SG_ 1208 PPMID_1_PPMISt 5;
BA_ "GenSigStartValue" SG_ 1208 PPMID_1_PPMISt 1;
BA_ "GenSigASIL" SG_ 582 PDC_1_CRC1 5;
BA_ "GenSigASIL" SG_ 582 PDC_1_RollgCntr1 5;
BA_ "GenSigASIL" SG_ 582 PDC_1_Resd1 5;
BA_ "GenSigASIL" SG_ 582 PDC_1_FOLDistance 5;
BA_ "GenSigStartValue" SG_ 582 PDC_1_FOLDistance 251;
BA_ "GenSigASIL" SG_ 582 PDC_1_FOLZoneStatus 5;
BA_ "GenSigASIL" SG_ 582 PDC_1_FMLDistance 5;
BA_ "GenSigStartValue" SG_ 582 PDC_1_FMLDistance 251;
BA_ "GenSigASIL" SG_ 582 PDC_1_FMLZoneStatus 5;
BA_ "GenSigASIL" SG_ 582 PDC_1_FMRDistance 5;
BA_ "GenSigStartValue" SG_ 582 PDC_1_FMRDistance 251;
BA_ "GenSigASIL" SG_ 582 PDC_1_FMRZoneStatus 5;
BA_ "GenSigASIL" SG_ 582 PDC_1_FORDistance 5;
BA_ "GenSigStartValue" SG_ 582 PDC_1_FORDistance 251;
BA_ "GenSigASIL" SG_ 582 PDC_1_CRC2 5;
BA_ "GenSigASIL" SG_ 582 PDC_1_RollgCntr2 5;
BA_ "GenSigASIL" SG_ 582 PDC_1_Resd2 5;
BA_ "GenSigASIL" SG_ 582 PDC_1_FORZoneStatus 5;
BA_ "GenSigASIL" SG_ 582 PDC_1_ROLDistance 5;
BA_ "GenSigStartValue" SG_ 582 PDC_1_ROLDistance 251;
BA_ "GenSigASIL" SG_ 582 PDC_1_ROLZoneStatus 5;
BA_ "GenSigASIL" SG_ 582 PDC_1_RMLDistance 5;
BA_ "GenSigStartValue" SG_ 582 PDC_1_RMLDistance 251;
BA_ "GenSigASIL" SG_ 582 PDC_1_RMLZoneStatus 5;
BA_ "GenSigASIL" SG_ 582 PDC_1_RMRDistance 5;
BA_ "GenSigStartValue" SG_ 582 PDC_1_RMRDistance 251;
BA_ "GenSigASIL" SG_ 582 PDC_1_RMRZoneStatus 5;
BA_ "GenSigASIL" SG_ 582 PDC_1_CRC3 5;
BA_ "GenSigASIL" SG_ 582 PDC_1_RollgCntr3 5;
BA_ "GenSigASIL" SG_ 582 PDC_1_Resd3 5;
BA_ "GenSigASIL" SG_ 582 PDC_1_RORDistance 5;
BA_ "GenSigStartValue" SG_ 582 PDC_1_RORDistance 251;
BA_ "GenSigASIL" SG_ 582 PDC_1_RORZoneStatus 5;
BA_ "GenSigASIL" SG_ 582 PDC_1_LSFDistance 5;
BA_ "GenSigStartValue" SG_ 582 PDC_1_LSFDistance 251;
BA_ "GenSigASIL" SG_ 582 PDC_1_LSFZoneStatus 5;
BA_ "GenSigASIL" SG_ 582 PDC_1_FKPLSFMDistance 5;
BA_ "GenSigStartValue" SG_ 582 PDC_1_FKPLSFMDistance 251;
BA_ "GenSigASIL" SG_ 582 PDC_1_FKPLSFMZoneStatus 5;
BA_ "GenSigASIL" SG_ 582 PDC_1_FKPLSRMDistance 5;
BA_ "GenSigStartValue" SG_ 582 PDC_1_FKPLSRMDistance 251;
BA_ "GenSigASIL" SG_ 582 PDC_1_CRC4 5;
BA_ "GenSigASIL" SG_ 582 PDC_1_RollgCntr4 5;
BA_ "GenSigASIL" SG_ 582 PDC_1_Resd4 5;
BA_ "GenSigASIL" SG_ 582 PDC_1_FKPLSRMZoneStatus 5;
BA_ "GenSigASIL" SG_ 582 PDC_1_LSRDistance 5;
BA_ "GenSigStartValue" SG_ 582 PDC_1_LSRDistance 251;
BA_ "GenSigASIL" SG_ 582 PDC_1_LSRZoneStatus 5;
BA_ "GenSigASIL" SG_ 582 PDC_1_RSFDistance 5;
BA_ "GenSigStartValue" SG_ 582 PDC_1_RSFDistance 251;
BA_ "GenSigASIL" SG_ 582 PDC_1_RSFZoneStatus 5;
BA_ "GenSigASIL" SG_ 582 PDC_1_FKPRSFMDistance 5;
BA_ "GenSigStartValue" SG_ 582 PDC_1_FKPRSFMDistance 251;
BA_ "GenSigASIL" SG_ 582 PDC_1_FKPRSFMZoneStatus 5;
BA_ "GenSigASIL" SG_ 582 PDC_1_CRC5 5;
BA_ "GenSigASIL" SG_ 582 PDC_1_RollgCntr5 5;
BA_ "GenSigASIL" SG_ 582 PDC_1_Resd5 5;
BA_ "GenSigASIL" SG_ 582 PDC_1_FKPRSRMDistance 5;
BA_ "GenSigStartValue" SG_ 582 PDC_1_FKPRSRMDistance 251;
BA_ "GenSigASIL" SG_ 582 PDC_1_FKPRSRMZoneStatus 5;
BA_ "GenSigASIL" SG_ 582 PDC_1_RSRDistance 5;
BA_ "GenSigStartValue" SG_ 582 PDC_1_RSRDistance 251;
BA_ "GenSigASIL" SG_ 582 PDC_1_RSRZoneStatus 5;
BA_ "GenSigASIL" SG_ 582 PDC_1_ParKASSStatus 5;
BA_ "GenSigASIL" SG_ 582 PDC_1_PASTrailerHitchDetected 5;
BA_ "GenSigASIL" SG_ 582 PDC_1_PDCSwFdbk 5;
BA_ "GenSigASIL" SG_ 582 PDC_1_FrontWarningType 5;
BA_ "GenSigASIL" SG_ 582 PDC_1_RearWarningType 5;
BA_ "GenSigASIL" SG_ 582 PDC_1_LeftSideWarningType 5;
BA_ "GenSigASIL" SG_ 582 PDC_1_RightSideWarningType 5;
BA_ "GenSigASIL" SG_ 582 PDC_1_STATRearPDCActive 5;
BA_ "GenSigASIL" SG_ 582 PDC_1_STATFrntPDCActive 5;
BA_ "GenSigASIL" SG_ 582 PDC_1_STATSidePDCActive 5;
BA_ "GenSigASIL" SG_ 582 PDC_1_CRC6 5;
BA_ "GenSigASIL" SG_ 582 PDC_1_RollgCntr6 5;
BA_ "GenSigASIL" SG_ 582 PDC_1_Resd6 5;
BA_ "GenSigASIL" SG_ 582 PDC_1_STATSensorState 5;
BA_ "GenSigASIL" SG_ 582 PDC_1_STATPDCHMIMode 5;
BA_ "GenSigASIL" SG_ 582 PDC_1_FrontPDCMuteFeedback 5;
BA_ "GenSigASIL" SG_ 582 PDC_1_FKPMuteFeedback 5;
BA_ "GenSigASIL" SG_ 582 PDC_1_TimeOutMuteRequest 5;
BA_ "GenSigASIL" SG_ 1231 FuncReq_DepartureSdl 5;
BA_ "GenSigSendType" SG_ 1231 FuncReq_DepartureSdl 5;
BA_ "GenSigASIL" SG_ 1231 AVP_FuncReq 5;
BA_ "GenSigASIL" SG_ 1231 FBLPowerHold 5;
BA_ "GenSigASIL" SG_ 1199 TCM_1_TrailerSts 2;
BA_ "GenSigASIL" SG_ 1184 TMInletWaterTemp 5;
BA_ "GenSigStartValue" SG_ 1184 TMInletWaterTemp 254;
BA_ "GenSigASIL" SG_ 1207 WPump3Duty_FB 5;
BA_ "GenSigASIL" SG_ 1207 WPump3FltSt 5;
BA_ "GenSigASIL" SG_ 1035 VCC_1_CarMode 5;
BA_ "GenSigASIL" SG_ 1035 VCC_1_DriveMode 2;
BA_ "GenSigASIL" SG_ 1075 VCC_2_ConfigurationMessageTrg 5;
BA_ "GenSigSendType" SG_ 1075 VCC_2_ConfigurationMessageTrg 5;
BA_ "GenSigASIL" SG_ 1136 VCC_3_CRC 5;
BA_ "GenSigSendType" SG_ 1136 VCC_3_CRC 5;
BA_ "GenSigASIL" SG_ 1136 VCC_3_RollgCntr 5;
BA_ "GenSigSendType" SG_ 1136 VCC_3_RollgCntr 5;
BA_ "GenSigASIL" SG_ 1136 VCC_3_SN 5;
BA_ "GenSigStartValue" SG_ 1136 VCC_3_SN 1;
BA_ "GenSigSendType" SG_ 1136 VCC_3_SN 5;
BA_ "GenSigASIL" SG_ 1282 ADCC_TotalFaultNum 5;
BA_ "GenSigASIL" SG_ 1282 ADCC_FrameIndex 5;
BA_ "GenSigASIL" SG_ 1282 ADCC_SupplierNum 5;
BA_ "GenSigASIL" SG_ 1282 ADCC_FaultNum1 5;
BA_ "GenSigASIL" SG_ 1282 ADCC_FaultNum2 5;
BA_ "GenSigASIL" SG_ 1282 ADCC_FaultNum3 5;
BA_ "GenSigASIL" SG_ 1282 ADCC_FaultNum4 5;
BA_ "GenSigASIL" SG_ 1282 ADCC_FaultNum5 5;
BA_ "GenSigASIL" SG_ 1282 ADCC_FaultNum6 5;
BA_ "GenSigASIL" SG_ 1282 ADCC_FaultNum7 5;
BA_ "GenSigASIL" SG_ 1282 ADCC_FaultNum8 5;
BA_ "GenSigASIL" SG_ 1282 ADCC_FaultNum9 5;
BA_ "GenSigASIL" SG_ 1282 ADCC_FaultNum10 5;
BA_ "GenSigASIL" SG_ 1282 ADCC_FaultNum11 5;
BA_ "GenSigASIL" SG_ 1282 ADCC_FaultNum12 5;
BA_ "GenSigASIL" SG_ 1282 ADCC_FaultNum13 5;
BA_ "GenSigASIL" SG_ 1282 ADCC_FaultNum14 5;
BA_ "GenSigASIL" SG_ 1282 ADCC_FaultNum15 5;
BA_ "GenSigASIL" SG_ 1282 ADCC_FaultNum16 5;
BA_ "GenSigASIL" SG_ 1282 ADCC_FaultNum17 5;
BA_ "GenSigASIL" SG_ 1282 ADCC_FaultNum18 5;
BA_ "GenSigASIL" SG_ 1282 ADCC_FaultNum19 5;
BA_ "GenSigASIL" SG_ 1282 ADCC_FaultNum20 5;
BA_ "GenSigASIL" SG_ 1601 srcNodeID_ADCC 5;
BA_ "GenSigStartValue" SG_ 1601 srcNodeID_ADCC 65;
BA_ "GenSigASIL" SG_ 1601 RMR_ADCC 5;
BA_ "GenSigASIL" SG_ 1601 NMm_ADCC_Reserved1 5;
BA_ "GenSigASIL" SG_ 1601 ADCC_Wakeup_Poweron 5;
BA_ "GenSigASIL" SG_ 1601 ADCC_Wakeup_NM 5;
BA_ "GenSigASIL" SG_ 1601 ADCC_Wakeup_Diag 5;
BA_ "GenSigASIL" SG_ 1601 ADCC_Wakeup_KL15 5;
BA_ "GenSigASIL" SG_ 1601 ADCC_Awake_Poweron 5;
BA_ "GenSigASIL" SG_ 1601 ADCC_Awake_NM 5;
BA_ "GenSigASIL" SG_ 1601 ADCC_Awake_Diag 5;
BA_ "GenSigASIL" SG_ 1601 ADCC_Awake_Upload 5;
BA_ "GenSigASIL" SG_ 1601 ADCC_Awake_KL15 5;
BA_ "GenSigASIL" SG_ 1601 ADCC_Awake_Startup 5;
BA_ "GenSigASIL" SG_ 1601 ADCC_Awake_DOWAfterRun 5;
BA_ "GenSigASIL" SG_ 1975 Diag_ADCC_RES 5;
BA_ "GenSigSendType" SG_ 1975 Diag_ADCC_RES 2;
BA_ "GenSigASIL" SG_ 1847 Diag_ADCC_REQ 5;
BA_ "GenSigSendType" SG_ 1847 Diag_ADCC_REQ 2;
VAL_ 871 ADS_ParkingActiveSubFuncSts 7 "RPA without supervison" 6 "reserved " 5 "HPA RPA Out on" 4 "HPA RPA In on" 3 "BAFA on" 2 "RPA Out on" 1 "RPA Int on" 0 "No Request" ;
VAL_ 871 ADS_RPAIntFunSts 1 "Available" 0 "not Available" ;
VAL_ 871 RPAOutFunSts 1 "Available" 0 "not Available" ;
VAL_ 871 RpaStartButSts 1 "Available" 0 "not Available" ;
VAL_ 871 ADAS_enum_ApaRpaSts 15 "Reserved" 14 "Reserved" 13 "Reserved" 12 "Reserved" 11 "Reserved" 10 "Reserved" 9 "Background searching(Jetour)" 8 "Undo" 7 "Pause" 6 "Terminate" 5 "Failure" 4 "Completed" 3 "Parking active" 2 "Searching" 1 "Standby" 0 "Off" ;
VAL_ 871 ADAS_enum_ParkingQuitInd 78 " Req_Quit_ParkingFunction_Failure" 77 " Req_Quit_DrivingMode_switch" 76 "Req_Quit_Standby_ADASActive(有其他辅助驾驶功能正在使用，无法开启遥控泊车)" 75 "Req_Quit_Searching_Collision_occurs" 74 "Req_Quit_AEB_Active" 73 "Req_Quit_OutOff_ODD" 72 "Req_Quit_Searching_RelatedSystemFailure" 71 "Req_Quit_Searching_APAFailure" 70 "UnRecoverable Timeout Interrup" 69 "BlueTooth_Brake_OT" 68 "Engine_Start_Fault" 67 "Req_Quit_USS_Dirty" 66 "Req_Quit_Camera_Dirty" 65 "Reserved" 64 "Reserved" 63 "Reserved" 62 "Reserved" 61 "Reserved" 60 "Reserved" 59 "Reserved" 58 "Reserved" 57 "Reserved" 56 "Reserved" 55 "Reserved" 54 "Reserved" 53 "Reserved" 52 "Reserved" 51 "Reserved" 50 "Reserved" 49 "Req_Quit_Response_Timeout" 48 "Req_Quit_No_Avalible_Slot" 47 "Req_Quit_Passager_Door" 46 "Req_Quit_FreeSpace_Limit" 45 "Req_Quit_LOC_Unavilable" 44 "Req_Quit_Not allow_Area" 43 "Req_Quit_Pitch_Over limit" 42 "Req_Quit_Slope _Over limit" 41 "Req_Quit_ Path_Long_Over" 40 "Req_Quit_ Folded_Mirror" 39 "Req_Quit_Charge plug connected" 38 "Req_Quit_  Limitation _ PER_Fusion_Map" 37 "Req_Quit_ Limited_ Sensors" 36 "Req_Quit_ Still_moving_in_recovery_stages " 35 "Req_Quit_ Path_upload_timeout" 34 "Req_Quit_ Training_process_overflow" 33 "Req_Quit_ Corresponding_remind_timeout" 32 "Req_Quit_ Backward_move _ long" 31 "Req_Quit_ Internal_components_abnormal" 30 "Req_Quit_Function_Safety（因为功能安全原因导致泊车系统退出）" 29 "Req_Quit_Engine_Front_Door_Open（前引擎盖打开，泊车系统退出）" 28 "Req_Quit_Remote_device（遥控设备原因导致系统退出）" 27 "Req_Quit_Door_Lock（车辆上锁，泊车系统退出）（用于RPA）" 26 "Req_Quit_Unsafe_Behavior（P/EPB没被置起P-lock）" 25 "Req_Quit_No_POC_Slot_Avaliable（无可用泊出车位，泊车系统退出）" 24 "Req_Quit_Phone_LowBattey（手机电池电量低，泊车系统退出）" 23 "Req_Quit_Phone_Disconnected（与手机断开连接，泊车系统退出）" 22 "Req_Quit_Other_Reason" 21 "Req_Quit_Path_Deviation" 20 "Req_Quit_Steering Wheel Intervention (reserved)（驾驶员干预方向盘，泊车系统退出）" 19 "Req_Quit_External ECU actvie（ESP动态干预，泊车系统退出）" 18 "Req_Quit_Vehicle Block（车辆Block, 泊车系统退出）" 17 "Req_Quit_EPB_Apply（EPB拉起，泊车系统退出）" 16 "Req_Quit_Gear Interrupt (wrong gear position)（挡位不对，泊车系统退出）" 15 "Req_Quit_Gear Intervention(driver intervention)（驾驶员干预挡位，泊车系统退出）" 14 "Req_Quit_Terminate_Button_Pressed（取消摁键摁下，泊车系统退出）" 13 "Req_Quit_Surround_View（环视关闭，泊车系统退出）" 12 "Req_Quit_Luggage Door Open（后备箱打开，泊车系统退出）" 11 "Req_Quit_Driver_Door(all Doors)（车门打开，泊车系统退出）" 10 "Req_Quit_Seat belt unbuckle（安全带解开，泊车系统退出）" 9 "Req_Quit_TJA（TJA开启，泊车系统退出）" 8 "Req_Quit_ACC（ACC开启，泊车系统退出）" 7 "Req_Quit_Gas pedal（油门踏板踩下，泊车系统退出）" 6 "Req_Quit_Speed high（泊车速度太大，泊车系统退出）" 5 "Req_Quit_Space limit（泊车空间不足，泊车系统退出）" 4 "Req_Quit_Trajectory（泊车轨迹规划失败，泊车系统退出）" 3 "Req_Quit_Recover_Interrupt_Times_Overflow（暂停次数超限，泊车系统退出）" 2 "Req_Quit_Move times overflow（泊车次数超限，泊车系统退出）" 1 "Req_Quit_Timing overflow（泊车/暂停超时，泊车系统退出）" 0 "No Request" ;
VAL_ 871 ADAS_enum_ParkingDriOperateInd 70 "Req_PassingExam_SwtSet" 69 "BAFA Avaliable" 68 "Check RPA System Ready" 67 "Check Charging Removed OK" 66 "Check Outside Mirror Closed OK" 65 "Check All Doors Closed OK" 64 "Check Gear P OK" 63 "Req_Press_Parking_Switch" 62 "Req_Parking_complete" 61 " Reserved" 60 " Reserved" 59 " Reserved" 58 " Reserved" 57 " Reserved" 56 " Reserved" 55 " Reserved" 54 " Reserved" 53 " Reserved" 52 " Reserved" 51 " Reserved" 50 " Reserved" 49 " Reserved" 48 " Reserved" 47 " Reserved" 46 "Req_Path saving" 45 "Req_Speed over limit,APA can't avtive" 44 "Req_Parking resume" 43 "Req_Caution rear space" 42 "Req_Target slot occupied, try to paking in other slot" 41 "Req_Training path is mapping" 40 "Req_Path length  ready exceed limit" 39 "Req_System will automatically Save path after trainning success" 38 "Req_stop_Paking slot first released" 37 "Req_Confirm_Save training Path" 36 "Req_Press Brake and press recovery button" 35 "Req_Remove_Charging" 34 "Req_Undo_Select" 33 "Req_Steering Wheel_HandOff" 32 "Req_PS_Input" 31 "Req_ Confirm_Press Undo Switch" 30 "Req_Foward move a bit" 29 "Req_Open_outside rear view Mirror" 28 "Req_MRA_start_confirm" 27 "Reserved" 26 "Req_DrivingMode_switch" 25 "Phone out of Range" 24 "Reserved" 23 "Req_Repress_Parking Switch" 22 "Req_POC Direction Select" 21 "Req_Function off" 20 "Req_Process bar" 19 "Req_Release Brake" 18 "Req_Confirm_Press DM Switch" 17 "Req_Press Brake Pedal" 16 "Req_Surround_View" 15 "Req_Buckle Seat Belt" 14 "Req_Close Door (all doors)" 13 "Req_Close Engine Front Door" 12 "Req_Close Trunk" 11 "Req_Leave_Car" 10 "Req EPB_Applied(Req_Gear P and EPB Applied)" 9 "Req_Connect_Phone" 8 "Req_Function Select for A/RPA" 7 "Req_Turn_lever（Reserved)" 6 "Req_PS_ID_Selection" 5 "Req_Stop" 4 "Req_SearchingProcess" 3 "Req_Slow_Down" 2 "Req_Gear_D" 1 "Req_Function Select" 0 "No Request" ;
VAL_ 871 ADAS_enum_ParkingPauseInd 15 "Req_BlueTooth_Brake_Pause" 14 "Req_Recover_Found_Side_Obstacle in Trajectory(Jetour)" 13 "Req_Recover_RemoteButtonReleased(Jetour)" 12 "Req_Recover_Hood_Open" 11 "Req_Recover_Camera blocked" 10 "Req_Recover_Seat belt_Unbuckled" 9 "Req_Recover_Trunk_Open" 8 "Req_Recover_External Mirror_Open" 7 "Req_Recover_Vehicle standstill overtime" 6 "Req_Recover_Pedestrain In Trajectory " 5 "Req_Recover_Key out of range" 4 "Req_Recover_Phone out of range" 3 "Req_Recover_Found Obstacle In Trajectory" 2 "Req_Recover_PassengerDoor_Open" 1 "Req_Recover_Press_ Resume Switch" 0 "No Request" ;
VAL_ 871 PrkInSts 1 "RPA Front int" 0 "RPA back int" ;
VAL_ 871 FrontLeftOutsts 1 "Available" 0 "not Available" ;
VAL_ 871 FrontRightOutsts 1 "Available" 0 "not Available" ;
VAL_ 871 FrontStrightOutsts 1 "Available" 0 "not Available" ;
VAL_ 871 BackLeftOutsts 1 "Available" 0 "not Available" ;
VAL_ 871 BackRightOutsts 1 "Available" 0 "not Available" ;
VAL_ 871 BackStrightOutsts 1 "Available" 0 "not Available" ;
VAL_ 871 FrontLeftParallelOutsts 1 "Available" 0 "not Available" ;
VAL_ 871 FrontRightParallelOutsts 1 "Available" 0 "not Available" ;
VAL_ 871 ParkOutDirectionSt 15 "reserved" 14 "reserved" 13 "reserved" 12 "reserved" 11 "reserved" 10 "reserved" 9 "reserved" 8 "Back Right Cross" 7 "Back Left Cross" 6 "Back Out" 5 "Front Right Parallel" 4 "Front Right Cross" 3 "Front Out" 2 "Front Left Parallel" 1 "Front Left Cross" 0 "none" ;
VAL_ 871 ADS_ParkingRemind 7 "Reserved" 6 "Reserved" 5 "Reserved" 4 "Reserved" 3 "Reserved" 2 "Req Abort" 1 "Req complete" 0 "Not Req" ;
VAL_ 871 HPARPAInFunSts 3 "Reserved" 2 "Reserved" 1 "Available" 0 "not Available" ;
VAL_ 871 HPARPAOutFunSts 3 "Reserved" 2 "Reserved" 1 "Available" 0 "not Available" ;
VAL_ 871 BAFAFunSts 3 "Reserved" 2 "Reserved" 1 "Available" 0 "not Available" ;
VAL_ 871 RpaResumeButSts 3 "Default" 2 "During The Self Inspection Preocess" 1 "Available" 0 "not Available" ;
VAL_ 871 ADS_1_BAFAFrontButSts 3 "Reserved" 2 "Reserved" 1 "Available" 0 "not Available" ;
VAL_ 871 ADS_1_BAFABacktButSts 3 "Reserved" 2 "Reserved" 1 "Available" 0 "not Available" ;
VAL_ 871 ADS_1_SelfCheckSt 3 "Reserved" 2 "Failure" 1 "Available" 0 "not Available" ;
VAL_ 871 ADS_1_RPASet 3 "Reserved" 2 "Reserved" 1 "Available" 0 "not Available" ;
VAL_ 871 ADS_1_SlotType 3 "Diagonal" 2 "Cross" 1 "Parallel" 0 "No Park" ;
VAL_ 871 ADS_1_ActivateEcall 1 "active" 0 "not active" ;
VAL_ 901 ADS_Road_infor_available 1 "Available" 0 "Not Available " ;
VAL_ 901 ADS_Road_Type 7 "Invalid" 6 "Reserved" 5 "Reserved" 4 "Reserved" 3 "Reserved" 2 "Gravel road " 1 "Bumpy road" 0 "Flat road" ;
VAL_ 901 ADS_Rough_Sta_L 3 "convex" 2 "concave" 1 "flat" 0 "Unknown" ;
VAL_ 901 ADS_Road_Features_L 15 "Invalid" 14 "reserved" 13 "reserved" 12 "reserved" 11 "reserved" 10 "reserved" 9 "reserved" 8 "Others" 7 "Pit" 6 "Cement joint" 5 "Bridge joint " 4 "Continuous Speed Bumps" 3 "High-speed vibration zone " 2 "Manhole cover" 1 "Speed Bump?" 0 "No Object" ;
VAL_ 901 ADS_Rough_Sta_R 3 "convex" 2 "concave" 1 "flat" 0 "Unknown" ;
VAL_ 901 ADS_Road_Features_R 15 "Invalid" 14 "reserved" 13 "reserved" 12 "reserved" 11 "reserved" 10 "reserved" 9 "reserved" 8 "Others" 7 "Pit" 6 "Cement joint" 5 "Bridge joint " 4 "Continuous Speed Bumps" 3 "High-speed vibration zone " 2 "Manhole cover" 1 "Speed Bump?" 0 "No Object" ;
VAL_ 901 SpeedBump_0_ID 14 "14" 13 "13" 12 "12" 11 "11" 10 "10" 9 "9" 8 "8" 7 "7" 6 "6" 5 "5" 4 "4" 3 "3" 2 "2" 1 "1" 0 "0" ;
VAL_ 901 SpeedBump_0_Valid 1 "valid" 0 "Invalid" ;
VAL_ 901 SpeedBump_1_ID 14 "14" 13 "13" 12 "12" 11 "11" 10 "10" 9 "9" 8 "8" 7 "7" 6 "6" 5 "5" 4 "4" 3 "3" 2 "2" 1 "1" 0 "0" ;
VAL_ 901 SpeedBump_1_Valid 1 "valid" 0 "Invalid" ;
VAL_ 901 SpeedBump_2_ID 14 "14" 13 "13" 12 "12" 11 "11" 10 "10" 9 "9" 8 "8" 7 "7" 6 "6" 5 "5" 4 "4" 3 "3" 2 "2" 1 "1" 0 "0" ;
VAL_ 901 SpeedBump_2_Valid 1 "valid" 0 "Invalid" ;
VAL_ 901 SpeedBump_3_ID 14 "14" 13 "13" 12 "12" 11 "11" 10 "10" 9 "9" 8 "8" 7 "7" 6 "6" 5 "5" 4 "4" 3 "3" 2 "2" 1 "1" 0 "0" ;
VAL_ 901 SpeedBump_3_Valid 1 "valid" 0 "Invalid" ;
VAL_ 901 SpeedBump_4_ID 14 "14" 13 "13" 12 "12" 11 "11" 10 "10" 9 "9" 8 "8" 7 "7" 6 "6" 5 "5" 4 "4" 3 "3" 2 "2" 1 "1" 0 "0" ;
VAL_ 901 SpeedBump_4_Valid 1 "valid" 0 "Invalid" ;
VAL_ 783 ADS_1_FunctionSuppressReq 3 "Reserved" 2 "Standard_Height" 1 "Disable" 0 "No Request" ;
VAL_ 783 ADS_1_HPASts 15 "Reserved" 14 "Reserved" 13 "Reserved" 12 "Reserved" 11 "Reserved" 10 "Reserved" 9 "Training terminate" 8 "Training Completed" 7 "Training" 6 "Pause" 5 "Terminate" 4 "Failure" 3 "Completed" 2 "Guidance active" 1 "Standby" 0 "Off" ;
VAL_ 783 ADS_1_VPASts 15 "reserved" 14 "reserved" 13 "reserved" 12 "reserved" 11 "reserved" 10 "reserved" 9 "reserved" 8 "Self build map" 7 "Pause" 6 "Terminate" 5 "Failure" 4 "Completed" 3 "Guidance active" 2 "Standby" 1 "Passive" 0 "Off" ;
VAL_ 783 ADCC_CameraStreamSts 7 "Reserved" 6 "Reserved" 5 "Recoverying  " 4 "Error  " 3 "DeInitFinish  " 2 "Working  " 1 "Inited  " 0 "Reset  " ;
VAL_ 783 ADCC_CameraErrorCode 7 "reserved(未定义errorcode 时发0x4)" 6 "reserved(未定义errorcode 时发0x4)" 5 "reserved(未定义errorcode 时发0x4)" 4 "reserved(未定义errorcode 时发0x4)" 3 "ErrorCode3" 2 "ErrorCode2" 1 "ErrorCode1" 0 "NoError" ;
VAL_ 783 ADCC_HWRequest 1 "Demand" 0 "No demand" ;
VAL_ 783 ADCC_PP_M_Request 1 "Demand" 0 "No demand" ;
VAL_ 783 ADCC_HighwayZoneState 3 "Reserved" 2 "Reserved" 1 "Highway zone" 0 "Invalid/unknown " ;
VAL_ 783 ADCC_CoolingReq 7 "Reserved" 6 "Reserved" 5 "Emergency" 4 "Critical" 3 "High" 2 "Middle" 1 "Low" 0 "No Request" ;
VAL_ 783 ADCC_UploadFlag 1 "request" 0 "no req" ;
VAL_ 783 ADCC_SurroundCameraErrorSts 8 "RightViewError" 4 "LeftViewError" 2 "RearViewError" 1 "FrontViewError" 0 "NoError" ;
VAL_ 783 ADCC_SysReadySts 1 "not Ready" 0 "Ready" ;
VAL_ 783 ADS_1_APARPASts 15 "Reserved" 14 "Reserved" 13 "Reserved" 12 "Reserved" 11 "Reserved" 10 "Reserved" 9 "Background searching(Jetour)" 8 "Undo" 7 "Pause" 6 "Terminate" 5 "Failure" 4 "Completed" 3 "Guidance active" 2 "Searching" 1 "Standby" 0 "Off" ;
VAL_ 783 ADCC_OvertemperatureErrorSts 3 "Reserved" 2 "Error" 1 "Normal" 0 "Not Active" ;
VAL_ 783 ADCC_CamFOV_HeatReq 7 "Reserved" 6 "Reserved" 5 "Reserved" 4 "Reserved" 3 "Reserved" 2 "Reserved" 1 "Request" 0 "No Request" ;
VAL_ 788 ADS_2_FunctionSuppressReq 3 "Reserved" 2 "Standard_Height" 1 "Disable" 0 "No Request" ;
VAL_ 788 ADS_2_HWRequest 1 "Demand" 0 "No demand" ;
VAL_ 788 ADS_2_PP_M_Request 1 "Demand" 0 "No demand" ;
VAL_ 788 ADS_2_AEBStatus 6 "blindness(Jetour)" 5 "pre-fill" 4 "active" 3 "no_active" 2 "Failure" 1 "ON" 0 "OFF" ;
VAL_ 788 ADS_2_ClosingSpeed 255 "Invalid" ;
VAL_ 788 ADS_2_TTC 511 "Invalid" ;
VAL_ 788 ADS_2_Object 7 "reserved" 6 "special truck(Reserved)" 5 "general object" 4 "motocycle" 3 "people" 2 "truck" 1 "car" 0 "no object" ;
VAL_ 788 ADS_2_Object_Status 3 "standing still" 2 "reverse direction" 1 "same direction" 0 "no object" ;
VAL_ 788 ADS_2_FCWStatus 7 "reserved" 6 "reserved" 5 "reserved" 4 "reserved" 3 "level 3(high)" 2 "level 2(middle)" 1 "level 1(low)" 0 "no request" ;
VAL_ 788 FCM_2_SysStatus 3 "J3 Over-temperature" 2 "Urgent TOR request" 1 "Not available" 0 "Available" ;
VAL_ 788 FCM_2_IHCfunctionSts 7 "Reserved" 6 "Reserved" 5 "Reserved" 4 "Reserved" 3 "Fault" 2 "Active" 1 "Standby" 0 "Off" ;
VAL_ 788 FCM_2_HazardLightReq 5 "Hzazard Flash" 4 "Hazard" 3 "Right" 2 "Left" 1 "OFF" 0 "Not active" ;
VAL_ 788 FCM_2_HighBeamReq_Cmd 2 "ON" 1 "OFF" 0 "Not Active" ;
VAL_ 794 ADS_3_ICAStatus 7 "reserved" 6 "reserved" 5 "Suspend" 4 "Failure" 3 "Active" 2 "Standby" 1 "Passive" 0 "Off" ;
VAL_ 794 ADS_3_ICATextinfo 15 "reserved" 14 "reserved" 13 "Master switch is off(Jetour)" 12 "Camera block" 11 "Abnormal tire pressure" 10 "Too Large curve" 9 "uncentered " 8 "Urgent TOR request" 7 "TJAICA degrade to ACC" 6 "TJAICA resumed" 5 "TJAICA Suspend" 4 "TJAICA failure" 3 "TJAICA Cancelled" 2 "TJAICA Cannot Be Activated" 1 "TJAICA Activated" 0 "No dispaly" ;
VAL_ 794 ADS_3_ACCSts 15 "reserved" 14 "reserved" 13 "reserved" 12 "reserved" 11 "reserved" 10 "reserved" 9 "reserved" 8 "Stand Active" 7 "failure" 6 "Stand Wait" 5 "Override" 4 "Brake Only" 3 "Active_Control" 2 "Standby" 1 "Passive" 0 "Off" ;
VAL_ 794 ADS_3_DriverHandsoffWarning 7 "reserved" 6 "reserved" 5 "reserved" 4 "Warning 4 for stage4(Punishment)" 3 "Warning 3 for stage3(TOR)" 2 "Warning 2  for stage2" 1 "Warning 1 for stage1" 0 "None" ;
VAL_ 794 ADS_3_AESStatus 7 "reserved" 6 "reserved" 5 "reserved" 4 "Passive" 3 "Failure" 2 "Active" 1 "Standby" 0 "OFF" ;
VAL_ 794 ADS_3_LKSMod 3 "reserved" 2 "Warning+intervention" 1 "Warning" 0 "Off" ;
VAL_ 794 ADS_3_LKSSts 7 "Reserved" 6 "Blindness(Jetour)" 5 "Reserved" 4 "Passive" 3 "Failure" 2 "Active" 1 "Standby" 0 "OFF" ;
VAL_ 794 ADS_3_ELKSts 7 "Reserved" 6 "Blindness(Jetour)" 5 "Reserved" 4 "Passive" 3 "Failure" 2 "Active" 1 "Standby" 0 "OFF" ;
VAL_ 794 ADS_3_LKSLeftTrackingSt 3 "warning" 2 "Intervention" 1 "Lane Tracking" 0 "Inactive" ;
VAL_ 794 ADS_3_LKSRightTrackingSt 3 "warning" 2 "Intervention" 1 "Lane Tracking" 0 "Inactive" ;
VAL_ 794 ADS_3_ELKLeftActiveSt 2 "intervention" 1 "tracking" 0 "no warning" ;
VAL_ 794 ADS_3_ELKRightActiveSt 2 "intervention" 1 "tracking" 0 "no warning" ;
VAL_ 794 ADS_3_RearViewFoldReq 2 "Open" 1 "Close" 0 "Not Active" ;
VAL_ 794 ADS_ALCSts 11 "Failure" 10 "Lane Change Longitudinal Matching" 9 "Lane Change Prepare" 8 "Retreated" 7 "Retreating" 6 "Abort" 5 "lane changed" 4 "Lane changing" 3 "Wait" 2 "Enable" 1 "Inhibited" 0 "Off" ;
VAL_ 794 ADS_HNOPSts 8 "Lateral Suspend" 7 "Failure" 6 "Safe stop" 5 "TOR" 4 "Longitudinal Suspend" 3 "Active control" 2 "Ready" 1 "Passive" 0 "Off" ;
VAL_ 794 ADS_UNOPSts 8 "Lateral Suspend" 7 "Failure" 6 "Safe stop" 5 "TOR" 4 "Longitudinal Suspend" 3 "Active control" 2 "Ready" 1 "Passive" 0 "Off" ;
VAL_ 794 ADAS_ParkingActiveSubFuncSt 5 "MRA on" 4 "VPA on" 3 "HPA on" 2 "RPA on" 1 "APA on" 0 "No Request" ;
VAL_ 794 ADS_DoorLockReq 3 "Not used" 2 "Lock" 1 "Unlock" 0 "Not request" ;
VAL_ 794 ADASLighSwtSts 3 "invalid" 2 "ON" 1 "OFF" 0 "Not Active" ;
VAL_ 794 ADCCFlowReq 255 "Invalid" ;
VAL_ 1037 ADAS_HornReq 2 "flash" 1 "all on" 0 "all off" ;
VAL_ 1037 ADAS_RpaPowerOFFReq 1 "reqest" 0 "no reqest" ;
VAL_ 1037 ADAS_TurnLightReq 5 "Hzazard Flash(双闪灯闪烁三下)" 4 "Hazard(双闪灯亮)" 3 "Right(右转向灯亮)" 2 "Left(左转向灯亮)" 1 "OFF" 0 "Not active" ;
VAL_ 1037 ADAS_HighBeamReq 3 "Flash(远光灯闪烁两次)" 2 "ON(远光灯开启)" 1 "OFF" 0 "Not active" ;
VAL_ 1037 ADAS_LowBeamReq 2 "ON" 1 "OFF" 0 "Not Active" ;
VAL_ 1037 ADCC_ADASLightReq 3 "invalid" 2 "ON" 1 "OFF" 0 "Not Active" ;
VAL_ 1037 ADS_AutoLightSwCtrl 3 "AUTO_MODE" 2 "LOW_BEAM" 1 "POSITION_LIGHT" 0 "No request" ;
VAL_ 1037 ADS_WshrReq 1 "request" 0 "No request" ;
VAL_ 1037 ADS_FrontWiperReq 1 "request" 0 "No request" ;
VAL_ 1217 ASU_1_ASUSysFailrSts 3 "Reserved" 2 "Fail" 1 "LimpupMode" 0 "No Fail" ;
VAL_ 1217 ASU_1_SuspCurrentLvl 15 "Reserved" 14 "Reserved" 13 "Reserved" 12 "Reserved" 11 "easy Loading level" 10 "easy Entry Enable level" 9 "Very low level" 8 "Between low and very low level" 7 "Low level" 6 "Between normal and low level" 5 "Normal level" 4 "Between high and normal level" 3 "High level" 2 "Between Very high and high level" 1 "Very High level" 0 "Invalid" ;
VAL_ 1217 ASU_1_ECASSysSts 4 "Function Shutdown" 3 "AxisHolding" 2 "AxisLowering" 1 "AxisLifting" 0 "InValid" ;
VAL_ 1217 ASU_1_SuspTmpAdjSts 1 "Disable" 0 "Enable" ;
VAL_ 1217 ASU_1_MaintainMod 3 "MaintainModexitReq" 2 "OFF, susp isnot in MaintainMod" 1 "ON,susp is in MaintainMod" 0 "Initializing" ;
VAL_ 1217 ASU_1_ECASErrSts 3 "fault priority 3(Very seriously)" 2 "fault priority 2(seriously)" 1 "fault priority 1(minor)" 0 "no error" ;
VAL_ 1217 ASU_1_SuspTarLvl 7 "easy Loading level" 6 "easy Entry Enable level" 5 "very low level" 4 "low level" 3 "normal level" 2 "high level" 1 "Very high level" 0 "No requirement" ;
VAL_ 1217 ASU_1_EasyEntryEna 1 "Enable" 0 "Not Enable" ;
VAL_ 1217 ASU_1_AutoEasyEntryFb 1 "Enable" 0 "Not Enable" ;
VAL_ 1217 ASU_1_ECASModeFb 7 "Reserved" 6 "Reserved" 5 "Reserved" 4 "Reserved" 3 "All Road" 2 "sport" 1 "normal" 0 "comfort" ;
VAL_ 1217 ASU_1_BluetoothManEasyEntryFb 1 "Active" 0 "Inactive" ;
VAL_ 1217 ASU_1_HighwayModFb 1 "Active" 0 "Inactive" ;
VAL_ 1217 ASU_1_CDCErrSts 1 "error" 0 "no error" ;
VAL_ 1217 ASU_1_SuspDampingLvl 7 "Reserved" 6 "Reserved" 5 "Reserved" 4 "Soft" 3 "Middle" 2 "Hard    " 1 "Very Hard" 0 "None" ;
VAL_ 776 ASU_2_LFHeight 4095 "Invalid" ;
VAL_ 776 ASU_2_RFHeight 4095 "Invalid" ;
VAL_ 776 ASU_2_LRHeight 4095 "Invalid" ;
VAL_ 776 ASU_2_RRHeight 4095 "Invalid" ;
VAL_ 776 ASU_2_sensorErrorSts 15 "four sensors are faulty" 14 "LF RF and LR sensors are faulty " 13 "LF RF and RR sensors are faulty " 12 "LF and RF sensor fault " 11 "LF LR and RR sensors are faulty " 10 "LF and LR sensor fault " 9 "LF and RR sensor fault " 8 "LF sensor fault  " 7 "RF LR and RR sensors  faulty " 6 "RF and LR sensors  faulty " 5 "RF and RR sensor fault " 4 "RF sensor faulty " 3 "RR and LR sensors faulty " 2 "LR sensor faulty " 1 "RR sensor faulty " 0 "all four sensors no fault " ;
VAL_ 1291 BMS_SOCLight 127 "Invalid" ;
VAL_ 1295 BMS_ChgWireConnect_LightSts 1 "Connect" 0 "DIsconnect" ;
VAL_ 1295 BMS_Chg_LightSts 1 "charging" 0 "No Charge" ;
VAL_ 852 BNCM_1_WelcomeON 3 "reserved" 2 "Welcome light ON" 1 "Welcome light OFF" 0 "Default value" ;
VAL_ 852 BNCM_1_WALLockRequest 1 "Request" 0 "No request" ;
VAL_ 852 BNCM_1_UIRUnLockRequest 1 "Request" 0 "No request" ;
VAL_ 852 BNCM_1_VehicleSearchRequest 1 "Request" 0 "No request" ;
VAL_ 879 BNCM_4_RpaDevicefailSts 7 "reserved" 6 "reserved" 5 "reserved" 4 "reserved" 3 "Other Failures" 2 "LowBatt" 1 "Offline" 0 "NoFailure" ;
VAL_ 879 BNCM_4_RpaModReq 1 "Request" 0 "No request" ;
VAL_ 879 BNCM_4_ExitAndPowerOff 3 "reserved" 2 "reserved" 1 "Pressed ON" 0 "No Pressed" ;
VAL_ 879 BNCM_4_RpaModselect 7 "reserved" 6 "reserved" 5 "HPA RPA Out on" 4 "HPA RPA In on" 3 "BAFA on" 2 "RPA Out on" 1 "RPA Int on" 0 "Not select" ;
VAL_ 879 BNCM_4_RpaBtnSts 1 "Pressed ON" 0 "No Pressed" ;
VAL_ 879 BNCM_4_StraightInBtnSts 1 "Pressed ON" 0 "No Pressed" ;
VAL_ 879 BNCM_4_StraightOutBtnSts 1 "Pressed ON" 0 "No Pressed" ;
VAL_ 879 BNCM_4_RpaBtnCancelSts 1 "Pressed ON" 0 "No Pressed" ;
VAL_ 879 BNCM_4_PrkOutModSelRmt 15 "Reserved" 14 "Reserved" 13 "Reserved" 12 "Reserved" 11 "Reserved" 10 "Reserved" 9 "Reserved" 8 "Back Right Cross" 7 "Back Left Cross" 6 "Back Out" 5 "Front Right Parallel" 4 "Front Right Cross" 3 "Front Out" 2 "Front Left Parallel" 1 "Front Left Cross" 0 "none" ;
VAL_ 879 BNCM_4_HeartbeatSignal 1 "Active" 0 "NotActive" ;
VAL_ 879 BNCM_4_PauseBtn 1 "Pressed ON" 0 "No Pressed" ;
VAL_ 879 BNCM_4_ResumeBtn 1 "Pressed ON" 0 "No Pressed" ;
VAL_ 879 BNCM_4_RpaDeviceDisSts 3 "out of range" 2 "Normal Range" 1 "in the Car" 0 "not valid" ;
VAL_ 879 BNCM_4_BLEConnSts 3 "Reserved" 2 "Connection" 1 "Not connection" 0 "Default" ;
VAL_ 879 BNCM_4_BLEErrStatus 1 "Error" 0 "No Error" ;
VAL_ 1191 BNCM_6_RemoteControl 31 "Reserved" 30 "Reserved" 29 "Reserved" 28 "Reserved" 27 "Reserved" 26 "Light and Whistle Car Search" 25 "Light Car Search" 24 "Whistle Car Search" 23 "Lockbox unlock" 22 "Steering wheel heat OFF" 21 "Steering wheel heat ON" 20 "OneButton heat OFF" 19 "OneButton heat ON" 18 "ChargerDoor lock" 17 "ChargerDoor unlock" 16 "Bonnet unlock" 15 "Air Cleaning OFF" 14 "Air Cleaning ON" 13 "SunroofVentCmd" 12 "SunroofOpenCmd" 11 "SunroofCloseCmd" 10 "WindowAppVentCmd" 9 "WindowAppOpenCmd" 8 "WindowAppCloseCmd" 7 "Remote stop" 6 "Remote start" 5 "Trunk active" 4 "Trunk lock" 3 "Trunk unlock" 2 "Unlock " 1 "Lock" 0 "No Command" ;
VAL_ 672 BNCM_14_LockButtAct 3 "LockButt LongPress" 2 "LockButt DoublePress" 1 "LockButt SinglePress" 0 "None" ;
VAL_ 672 BNCM_14_UnLockButtAct 3 "UnLockButt LongPress" 2 "UnLockButt DoublePress" 1 "UnLockButt SinglePress" 0 "None" ;
VAL_ 672 BNCM_14_RemoteButtAct 3 "RemoteButt LongPress" 2 "RemoteButt DoublePress" 1 "RemoteButt SinglePress" 0 "None" ;
VAL_ 1143 DCDC_WorkingMode 15 "Reserved" 14 "Reserved" 13 "Reserved" 12 "Reserved" 11 "Reserved" 10 "Reserved" 9 "Reserved" 8 "Reserved" 7 "Reserved" 6 "Reserved" 5 "Reserved" 4 "Reserved" 3 "Fault" 2 "Buck" 1 "Standby" 0 "Init" ;
VAL_ 1143 OBC_CC_ConnectSts 7 "Reserved" 6 "Reserved" 5 "Error" 4 "Half Connection" 3 "V2L" 2 "V2V" 1 "Charge Connected" 0 "Not connected" ;
VAL_ 1172 ExternalTemperature_C 255 "Invalid" 254 "invalid" ;
VAL_ 1172 ExternalTemperatureFailSts 1 "Fail Present" 0 "Fail Not Present" ;
VAL_ 884 WPump3Duty 255 "Invalid" ;
VAL_ 321 GearShiftPos 15 "SNA(Double fault shifter sensor)" 14 "Reserved" 13 "Reserved" 12 "Reserved" 11 "Reserved" 10 "Reserved" 9 "Reserved" 8 "Shifter not initialized / INIT" 7 "Tip-(manual shift down)" 6 "Tip+(manual shift up)" 5 "POS_FIVE (backwards twice / Y2)" 4 "POS_FOUR (backwards once / Y1)" 3 "POS_THREE (forward once / X1)" 2 "POS_TWO (forward twice / X2)" 1 "POS_ONE (Z)(Manual position)" 0 "POS_ZERO (Z)" ;
VAL_ 321 GearShiftPosInverse 15 "POS_ZERO (Z)" 14 "POS_ONE (Z)(Manual position)" 13 "POS_TWO (forward twice / X2)" 12 "POS_THREE (forward once / X1)" 11 "POS_FOUR (backwards once / Y1)" 10 "POS_FIVE (backwards twice / Y2)" 9 "Tip+(manual shift up)" 8 "Tip-(manual shift down)" 7 "Shifter not initialized / INIT" 6 "Reserved" 5 "Reserved" 4 "Reserved" 3 "Reserved" 2 "Reserved" 1 "Reserved" 0 "SNA(Double fault shifter sensor)" ;
VAL_ 321 STAT_ParkButton 3 "reserved" 2 "Park button fault" 1 "driver request park button" 0 "no request" ;
VAL_ 321 STAT_ShifterLeverFault 7 "Invalid" 6 "Reserve" 5 "Reserve" 4 "Reserve" 3 "Shift sensors both fault" 2 "Shift sensor 2 fault" 1 "Shift sensor 1 fault" 0 "Shift sensors both ok" ;
VAL_ 321 DriveModeActive 3 "Invalid" 2 "Reserve" 1 "Sport Mode Active" 0 "Normal Mode" ;
VAL_ 321 DriveModeReq 3 "Invalid" 2 "Reserve" 1 "Sport Mode Button Pressed" 0 "Sport Mode Button Unpressed" ;
VAL_ 631 CSA_2_AllWarningInfo 7 "Reserved" 6 "Reserved" 5 "Reserved" 4 "Please check the position of the gear shift" 3 "Third grade failure of gear shift mechanism(Reserved)" 2 "Second grade failure of gear shift mechanism" 1 "First grade failure of gear shift mechanism" 0 "No error" ;
VAL_ 631 CSA_2_TurnSigLvrCmd 7 "fault" 6 "Reserved" 5 "Reserved" 4 "right change" 3 "left change" 2 "turn right" 1 "turn left" 0 "OFF" ;
VAL_ 631 CSA_2_HiBeamSwtCmd 3 "fault" 2 "flash" 1 "high beam" 0 "reserved" ;
VAL_ 631 CSA_2_WshrFrntCmd 1 "wash" 0 "OFF" ;
VAL_ 631 CSA_2_WiprFrntCmd 3 "HIGH" 2 "LOW" 1 "AUTO" 0 "OFF" ;
VAL_ 967 FRM_2_DetnHd_HWFail 1 "HWFailure" 0 "NoHWFailure" ;
VAL_ 967 FRM_2_DetnHd_Misalignment 1 "Misalignment" 0 "NoMisalignment" ;
VAL_ 967 FRM_2_DetnHd_AlignmentNotDone 1 "AlignmentNotDone" 0 "AlignmentDone" ;
VAL_ 967 FRM_2_DetnHd_SensorBlockage 1 "SensorBlockage" 0 "NoSensorBlockage" ;
VAL_ 967 FRM_2_DetnHd_ObjDetFail 1 "ObjDetFailure" 0 "NoObjDetFailure" ;
VAL_ 967 FRM_2_DetnHd_OutOfVoltage 1 "OutOfVoltage" 0 "NoOutOfVoltage" ;
VAL_ 967 FRM_2_DetnHd_OverTemperature 1 "OverTemperature" 0 "NoOverTemperature" ;
VAL_ 967 FRM_2_DetnHd_ReceivedCANTimeOut 1 "ReceivedCANTimeOut" 0 "NoReceivedCANTimeOut" ;
VAL_ 967 FRM_2_DetnHd_ReceivedCANInvalid 1 "ReceivedCANInvalid" 0 "NoReceivedCANInvalid" ;
VAL_ 967 FRM_2_DetnHd_RFBoardWorkingSts 1 "NoWorking" 0 "Working" ;
VAL_ 967 FRM_2_DetnHd_DetnDownSel 1 "down selected" 0 "no down selection" ;
VAL_ 967 FRM_2_DetnHd_NotConfigured 1 "NotConfigured" 0 "Configured" ;
VAL_ 967 FRM_2_DetnHd_ParameterInvalid 1 "ParameterInvalid" 0 "ParameterValid" ;
VAL_ 571 HoodLockSts 3 "Unknown" 2 "Superlocked" 1 "Unlocked" 0 "Locked" ;
VAL_ 571 DrvSeatOccupiedSts 1 "Active" 0 "Not Active" ;
VAL_ 571 LHTurnlightSts 1 "Active" 0 "Not Active" ;
VAL_ 571 RHTurnlightSts 1 "Active" 0 "Not Active" ;
VAL_ 571 HoodSts 3 "Reserved" 2 "full_open" 1 "Ajar " 0 "Close" ;
VAL_ 571 DrvDoorLockSts 3 "Unknown" 2 "Superlocked" 1 "Unlocked" 0 "Locked" ;
VAL_ 571 DrvDoorSts 3 "Reserved" 2 "full_open" 1 "Ajar " 0 "Close" ;
VAL_ 571 LHTurnSW 1 "Active" 0 "Off" ;
VAL_ 571 RHTurnSW 1 "Active" 0 "Off" ;
VAL_ 571 HazardLightSW 1 "Open" 0 "Close" ;
VAL_ 571 DrvSeatBeltSW 1 "Active" 0 "Not Active" ;
VAL_ 571 DirectionIndLeft 1 "Open" 0 "Close" ;
VAL_ 571 DirectionIndRight 1 "Open" 0 "Close" ;
VAL_ 571 DrvSeatBeltFaultStatus 1 "Fault" 0 "Not_Fault" ;
VAL_ 1120 RLHS_2_AmbBrightness 4095 "Invalid" ;
VAL_ 1120 RLHS_2_IRBrightness 255 "Invalid" ;
VAL_ 1120 RLHS_Rainfall 3 "Heavy Rain" 2 "Moderate Rain" 1 "Light Rain" 0 "No Rain" ;
VAL_ 1120 RLHS_LiSwithReason 3 "Tunnul" 2 "Night" 1 "Day" 0 "Darkstart" ;
VAL_ 1260 TrunLightFaults 1 "Faults" 0 "Not Faults" ;
VAL_ 1181 FLZCU_9_PowerMode 3 "Reserved" 2 "ON" 1 "Comfortable" 0 "Off" ;
VAL_ 1181 FLZCU_9_ArmingSts 3 "Invalid" 2 "Disarming successful" 1 "Arming successful" 0 "Not active" ;
VAL_ 843 HOD_OnOffSts 1 "Hand On" 0 "Hand Off" ;
VAL_ 843 HOD_OnOffStsValid 1 "Valid" 0 "Invalid" ;
VAL_ 843 HOD_HandOnSts 3 "Invalid" 2 "Two Hand" 1 "One Hand" 0 "None" ;
VAL_ 843 HOD_OneHand_Area 3 "Below Area" 2 "Right Area" 1 "Left Area" 0 "None" ;
VAL_ 843 HOD_OneHand_AreaValid 1 "Valid" 0 "Invalid" ;
VAL_ 843 HOD_LeftArea_Sts 2 "Left Area Grab" 1 "Left Area Touch" 0 "None" ;
VAL_ 843 HOD_LeftArea_StsVD 1 "Valid" 0 "Invalid" ;
VAL_ 843 HOD_RightArea_Sts 2 "Right Area Grab" 1 "Right Area Touch" 0 "None" ;
VAL_ 843 HOD_RightArea_StsVD 1 "Valid" 0 "Invalid" ;
VAL_ 843 HOD_FC_CAP_SENSOR_ERR 1 "Fault Occurred" 0 "No Fault" ;
VAL_ 843 HOD_FC_ECU_HW_Fault 1 "Fault Occurred" 0 "No Fault" ;
VAL_ 843 HOD_FC_BAT_LOW 1 "Fault Occurred" 0 "No Fault" ;
VAL_ 843 HOD_FC_BAT_HIGH 1 "Fault Occurred" 0 "No Fault" ;
VAL_ 843 HOD_FC_ResponseError 1 "Fault Occurred" 0 "No Fault" ;
VAL_ 843 HOD_FC_SYSTEM_ERR 1 "Fault Occurred" 0 "No Fault" ;
VAL_ 1030 FLZCU_FrontWiperParkStatus 1 "Returned" 0 "NotReturned" ;
VAL_ 1030 FLZCU_FrontWiperWipingStatus 2 "high" 1 "low" 0 "OFF" ;
VAL_ 1030 RearViewFoldSts 2 "unFold" 1 "Fold" 0 "invalid" ;
VAL_ 1076 RLHS_1_FWBrightness 1023 "Invalid" ;
VAL_ 1076 RLHS_TempSensorValue 255 "Invalid" ;
VAL_ 1076 RLHS_TempDewPoint 2047 "Invalid" ;
VAL_ 1076 RLHS_Humid_Temp_Error 1 "Error" 0 "Normal" ;
VAL_ 1071 FLZCU_LightMainSwitchSts 7 "Reserved" 6 "Reserved" 5 "Reserved" 4 "LowBeamSwitch Position" 3 "PositionLampSwitch Position" 2 "Auto Position " 1 "Off Position" 0 "Not active" ;
VAL_ 1071 FLZCU_FLFoglightSts 1 "ON" 0 "OFF" ;
VAL_ 1071 FLZCU_FRFoglightSts 1 "ON" 0 "OFF" ;
VAL_ 1071 FLZCU_RearFogLightSts 1 "ON" 0 "OFF" ;
VAL_ 1071 FLZCU_LowBeamSts 1 "Open" 0 "Close" ;
VAL_ 1071 FLZCU_HighBeamSts 1 "Open" 0 "Close" ;
VAL_ 1071 FLZCU_HighBeamFaults 1 "Faults" 0 "Not Faults" ;
VAL_ 1071 FLZCU_RearFogLightFaults 1 "Faults" 0 "Not Faults" ;
VAL_ 1071 FLZCU_ParkLightFaults 1 "Faults" 0 "Not Faults" ;
VAL_ 1071 FLZCU_DaytimeLight 3 "Both" 2 "Right" 1 "Left" 0 "None" ;
VAL_ 1071 FLZCU_HMASwSts 1 "Active" 0 "Not active" ;
VAL_ 1071 FLZCU_BrkLightSts 1 "Open" 0 "Close" ;
VAL_ 1071 FLZCU_FrontFogLightSts 1 "ON" 0 "OFF" ;
VAL_ 1071 FLZCU_CamFOV_HeatSts 3 "Reserved" 2 "Fault" 1 "Active" 0 "Not Active" ;
VAL_ 1071 ADASLightStsFb 1 "On" 0 "Off" ;
VAL_ 1071 ADSLightFaildSts 1 "Failure" 0 "Normal" ;
VAL_ 864 MFS_Cruise_Control 3 "Swtich fault" 2 "Stuck" 1 "Pressed" 0 "Not action" ;
VAL_ 864 MFS_RESPlus 3 "invalid" 2 "Stuck" 1 "Pressed" 0 "Not action" ;
VAL_ 864 MFS_SETMinus 3 "invalid" 2 "Stuck" 1 "Pressed" 0 "Not action" ;
VAL_ 864 MFS_Time_Gap_Reduce 3 "invalid" 2 "Stuck" 1 "Pressed" 0 "Not action" ;
VAL_ 864 MFS_Time_Gap_Add 3 "invalid" 2 "Stuck" 1 "Pressed" 0 "Not action" ;
VAL_ 864 MFS_Rsp_Error 1 "Error" 0 "No error" ;
VAL_ 864 MFS_LeftRoller 15 "invalid" 14 "Reserved" 13 "Reserved" 12 "Reserved" 11 "Reserved" 10 "Reserved" 9 "Reserved" 8 "Reserved" 7 "Reserved" 6 "Reserved" 5 "Reserved" 4 "ScrollDownQuickly" 3 "ScrollDownSlowly" 2 "ScrollUpQuickly" 1 "ScrollUpSlowly" 0 "Not action" ;
VAL_ 864 MFS_LeftRollerMiddleKey 7 "invalid" 6 "Reserved" 5 "Reserved" 4 "Reserved" 3 "Stuck" 2 "Long Pressed" 1 "Pressed" 0 "Not action" ;
VAL_ 683 PassDoorSts 3 "Reserved" 2 "full_open" 1 "Ajar " 0 "Close" ;
VAL_ 683 ParkLightSts 1 "Open" 0 "Close" ;
VAL_ 683 PassRearDoorSts 3 "Reserved" 2 "full_open" 1 "Ajar " 0 "Close" ;
VAL_ 683 PassDoorLockSts 3 "Unknown" 2 "Superlocked" 1 "Unlocked" 0 "Locked" ;
VAL_ 683 PassRearDoorLockSts 3 "Unknown" 2 "Superlocked" 1 "Unlocked" 0 "Locked" ;
VAL_ 1316 LHFTirePressure 255 "Invalid" ;
VAL_ 1316 RHFTirePressure 255 "Invalid" ;
VAL_ 1316 LHRTirePressure 255 "Invalid" ;
VAL_ 1316 RHRTirePressure 255 "Invalid" ;
VAL_ 1324 TirePositionWarning_LHFTire 7 "Not used(Reserved)" 6 "Error Mode" 5 "High Temperature" 4 "High Pressure(Reserved)" 3 "Low Batter" 2 "Low Pressure" 1 "Rapid Air Loss(Reserved)" 0 "Normal" ;
VAL_ 1324 TirePositionWarning_RHFTire 7 "Not used(Reserved)" 6 "Error Mode" 5 "High Temperature" 4 "High Pressure(Reserved)" 3 "Low Batter" 2 "Low Pressure" 1 "Rapid Air Loss(Reserved)" 0 "Normal" ;
VAL_ 1324 TirePositionWarning_LHRTire 7 "Not used(Reserved)" 6 "Error Mode" 5 "High Temperature" 4 "High Pressure(Reserved)" 3 "Low Batter" 2 "Low Pressure" 1 "Rapid Air Loss(Reserved)" 0 "Normal" ;
VAL_ 1324 TirePositionWarning_RHRTire 7 "Not used(Reserved)" 6 "Error Mode" 5 "High Temperature" 4 "High Pressure(Reserved)" 3 "Low Batter" 2 "Low Pressure" 1 "Rapid Air Loss(Reserved) " 0 "Normal" ;
VAL_ 1324 TirePressureWarningLampSts 3 "Not used" 2 "Lamp On" 1 "Lamp Flashing(Reserved)" 0 "Lamp Off" ;
VAL_ 1324 TirePressureSystemFailSts 1 "Fail Present" 0 "Fail Not Present" ;
VAL_ 1256 LowBeamFaults 1 "Faults" 0 "Not Faults" ;
VAL_ 638 DrvHandleSwitchSts 3 "Bothside" 2 "Inside" 1 "Outside" 0 "Not Active" ;
VAL_ 638 PassHandleSwitchSts 3 "Bothside" 2 "Inside" 1 "Outside" 0 "Not Active" ;
VAL_ 638 PassRearHandleSwitchSts 3 "Bothside" 2 "Inside" 1 "Outside" 0 "Not Active" ;
VAL_ 638 DrvRearHandleSwitchSts 3 "Bothside" 2 "Inside" 1 "Outside" 0 "Not Active" ;
VAL_ 949 PEPS_InformationSource 3 "Near Access" 2 "RKE Information" 1 "Smart Information" 0 "Not Active" ;
VAL_ 949 PEPS_OrderInformation 9 "Parking Key" 8 "Power Slide Door Left" 7 "RKE Search Car" 6 "Welcome Off" 5 "Welcome On" 4 "Trunk" 3 "Reserved" 2 "Unlock" 1 "Lock" 0 "OFF" ;
VAL_ 949 PEPS_KeySts 5 "Unknow" 4 "PEPS Key Near Trunkant" 3 "PEPS Key Near Frant" 2 "PEPS Key Near Flant" 1 "PEPS Key In" 0 "Not Active" ;
VAL_ 1028 PEPS_WelcomeON 3 "Reserved" 2 "Welcome light ON" 1 "Welcome light OFF" 0 "Default value" ;
VAL_ 1028 PEPS_VehicleSearchReq 1 "Request" 0 "No Request" ;
VAL_ 1028 PEPS_RKETrunkSts 3 "Not Used" 2 "Short Press" 1 "Long Press" 0 "Not Active" ;
VAL_ 1028 PEPS_UIRUnLockRequest 1 "Request" 0 "No request" ;
VAL_ 1028 PEPS_WALLockRequest 1 "Request" 0 "No request" ;
VAL_ 1270 PEPS_LockButtAct 3 "LockButt LongPress" 2 "LockButt DoublePress" 1 "LockButt SinglePress" 0 "None" ;
VAL_ 1270 PEPS_UnLockButtAct 3 "UnLockButt LongPress" 2 "UnLockButt DoublePress" 1 "UnLockButt SinglePress" 0 "None" ;
VAL_ 1270 PEPS_ParkFrntEna 1 "On" 0 "Off" ;
VAL_ 1270 PEPS_ParkBackEna 1 "On" 0 "Off" ;
VAL_ 1270 PEPS_AVPFctReq 3 "Exit and  power off and lock" 2 "Exit" 1 "Active" 0 "Off" ;
VAL_ 1270 PEPS_AVPActv 3 "Failure" 2 "ComLoss" 1 "Active" 0 "Not Active" ;
VAL_ 1270 PEPS_RpaDeviceDisSts 7 "Reserved" 6 "Reserved" 5 "Reserved" 4 "Reserved" 3 "Out Of Range" 2 "Normal Range" 1 "In Car" 0 "Not Active" ;
VAL_ 1270 PEPS_ParkinEna 3 "Reserved" 2 "ON" 1 "OFF" 0 "Not Active" ;
VAL_ 699 DrvRearDoorSts 3 "Reserved" 2 "full_open" 1 "Ajar " 0 "Close" ;
VAL_ 699 TrunkSts 3 "Reserved" 2 "full_open" 1 "Ajar " 0 "Close" ;
VAL_ 699 DrvRearDoorLockSts 3 "Unknown" 2 "Superlocked" 1 "Unlocked" 0 "Locked" ;
VAL_ 699 TrunkLockSts 3 "Unknown" 2 "Superlocked" 1 "Unlocked" 0 "Locked" ;
VAL_ 1258 BrkLightFaults 1 "Faults" 0 "Not Faults" ;
VAL_ 1258 RZCU_RearWiperWipingStatus 2 "high" 1 "low" 0 "OFF" ;
VAL_ 1258 RZCU_RearWiperParkStatus 1 "Returned" 0 "NotReturned" ;
VAL_ 1050 FLCR_1_SysSt 3 "System Error" 2 "Temporary Error" 1 "On" 0 "Off" ;
VAL_ 1050 FLCR_1_BlkSts 1 "Blockage" 0 "Not Blockage" ;
VAL_ 1062 FLCR_2_FCTAWarn 1 "Warning" 0 "No Warning" ;
VAL_ 1062 FLCR_2_FCTBWarn 1 "Warning" 0 "No Warning" ;
VAL_ 1062 FLCR_2_FCTBReq 1 "Request" 0 "Not Request" ;
VAL_ 1062 FLCR_2_FCTBCtrlA 1023 "Invalid" ;
VAL_ 1062 FLCR_2_FCTAFCTBONOFFSts 3 "Reserved" 2 "warning and braking" 1 "warning" 0 "OFF" ;
VAL_ 1067 FRCR_1_SysSt 3 "System Error" 2 "Temporary Error" 1 "On" 0 "Off" ;
VAL_ 1067 FRCR_1_BlkSts 1 "Blockage" 0 "Not Blockage" ;
VAL_ 1077 FRCR_2_FCTAWarn 1 "Warning" 0 "No Warning" ;
VAL_ 1077 FRCR_2_FCTBWarn 1 "Warning" 0 "No Warning" ;
VAL_ 1095 RLCR_1_SysSt 3 "System Error" 2 "Temporary Error" 1 "On" 0 "Off" ;
VAL_ 1095 RLCR_1_BlkSts 1 "Blockage" 0 "Not Blockage" ;
VAL_ 1095 RLCR_1_BSDWarn 3 "Not Used" 2 "Critical Warning" 1 "Standard Warning" 0 "No Warning" ;
VAL_ 1095 RLCR_1_DOWWarn 3 "Not Used" 2 "Level2 Warning " 1 "Level1 Warning " 0 "No Warning" ;
VAL_ 1095 RLCR_1_DowLock 3 "Not Used" 2 "Dow unlock" 1 "Dow lock" 0 "No Warning" ;
VAL_ 1095 RLCR_1_ELK_Collision_flag 1 "Critical situation of collision" 0 "No critical situation of collision" ;
VAL_ 1095 RLCR_1_ELK_CollisionFlagValid 1 "Valid" 0 "Not valid" ;
VAL_ 1104 RLCR_2_RCWWarn 3 "Not Used" 2 "Level2 Warning " 1 "Level1 Warning " 0 "No Warning" ;
VAL_ 1104 RLCR_2_RCTAWarn 1 "Warning" 0 "No Warning" ;
VAL_ 1104 RLCR_2_RCTBWarn 1 "Warning" 0 "No Warning" ;
VAL_ 1104 RLCR_2_RCTBReq 1 "Request" 0 "Not Request" ;
VAL_ 1104 RLCR_2_RCTBCtrlA 1023 "Invalid" ;
VAL_ 1104 RLCR_2_BSDLCWONOFFSts 3 "Reserved" 2 "ON" 1 "OFF" 0 "Not active" ;
VAL_ 1104 RLCR_2_DOWONOFFSts 3 "Reserved" 2 "ON" 1 "OFF" 0 "Not active" ;
VAL_ 1104 RLCR_2_RCWONOFFSts 3 "Reserved" 2 "ON" 1 "OFF" 0 "Not active" ;
VAL_ 1104 RLCR_2_RCTARCTBONOFFSts 3 "Reserved" 2 "warning and braking" 1 "warning" 0 "OFF" ;
VAL_ 1267 RRCR_1_SysSt 3 "System Error" 2 "Temporary Error" 1 "On" 0 "Off" ;
VAL_ 1267 RRCR_1_BlkSts 1 "Blockage" 0 "Not Blockage" ;
VAL_ 1267 RRCR_1_BSDWarn 3 "Not Used" 2 "Critical Warning" 1 "Standard Warning" 0 "No Warning" ;
VAL_ 1267 RRCR_1_DOWWarn 3 "Not Used" 2 "Level2 Warning " 1 "Level1 Warning " 0 "No Warning" ;
VAL_ 1267 RRCR_1_DowLock 3 "Not Used" 2 "Dow unlock" 1 "Dow lock" 0 "No Warning" ;
VAL_ 1267 RRCR_1_ELK_Collision_flag 1 "Critical situation of collision" 0 "No critical situation of collision" ;
VAL_ 1267 RRCR_1_ELK_CollisionFlagValid 1 "Valid" 0 "Not valid" ;
VAL_ 1271 RRCR_2_RCTAWarn 1 "Warning" 0 "No Warning" ;
VAL_ 1271 RRCR_2_RCTBWarn 1 "Warning" 0 "No Warning" ;
VAL_ 1252 TotalOdometer_km_OBD 16777215 "Invalid" ;
VAL_ 1252 TotalOdometer_km_OBDValidData 1 "Not valid" 0 "Valid" ;
VAL_ 1252 DisplayVehicleSpeed 8191 "Invalid" ;
VAL_ 1150 ICC_DriveDrosinessLevel 7 "Reserved" 6 "Driver unresponsive" 5 "highly fatigue" 4 "mid-fatigue" 3 "low fatigue" 2 "not fatigue" 1 "unknown" 0 "not available" ;
VAL_ 1157 ICC_DA_15_BSDLCWSettingSt 3 "Reserved" 2 "OFF" 1 "ON" 0 "None" ;
VAL_ 1157 ICC_DA_15_DOWSettingSt 3 "Reserved" 2 "OFF" 1 "ON" 0 "None" ;
VAL_ 1157 ICC_DA_15_RCWSettingSt 3 "Reserved" 2 "OFF" 1 "ON" 0 "None" ;
VAL_ 1157 ICC_DA_15_RCTARCTBWarnType 3 "None" 2 "Warning and braking" 1 "Warning" 0 "OFF" ;
VAL_ 1157 ICC_DA_15_FCTAFCTBWarnType 3 "None" 2 "Warning and braking" 1 "Warning" 0 "OFF" ;
VAL_ 1157 ICC_DA_15_FrontPDCMuteSet 1 "ON" 0 "OFF" ;
VAL_ 1157 ICC_DA_15_FKPMuteSet 1 "ON" 0 "OFF" ;
VAL_ 1157 ICC_DA_15_ExtremeEnergySaveMode 1 "ON" 0 "OFF" ;
VAL_ 1157 ICC_PDCOnOffSet 1 "Active" 0 "Not Active" ;
VAL_ 1157 Driver_EyeOnRoad 3 "Eyes off road -- non-driving task related region" 2 "Eyes off road -- driving task related region" 1 "Eyes on road" 0 "Unavailable" ;
VAL_ 1157 Dms_Status 4 "camera blocked" 3 "fault" 2 "active" 1 "off/standby" 0 "Init" ;
VAL_ 1157 Driver_AbnormalBehavior 2 "abnormal behavior detected" 1 "no abnormal behavior detected" 0 "unknown" ;
VAL_ 1157 Driver_GazeRegion 9 "other" 8 "Central driver's Instrument Cluster(speed gauge,etc.)" 7 "Central Rear View Mirror" 6 "Right Side Window" 5 "Left Side Window" 4 "Right Rear View Mirror" 3 "Left Rear View Mirror" 2 "Passenger Side of Windscreen" 1 "Driver Side of Windscreen" 0 "Unknown" ;
VAL_ 1157 Dms_DriverPresence 2 "present" 1 "Not present" 0 "unknown" ;
VAL_ 1157 ICC_IHCfunctionSw 2 "OFF" 1 "ON" 0 "Not Active" ;
VAL_ 1157 ICC_DistractionStatus 2 "Present" 1 "Not present" 0 "Not Active" ;
VAL_ 1157 ICC_DA_15_BSDLCWSettingSt_AFS 3 "Reserved" 2 "Sound+display warning" 1 "Display warning" 0 "None" ;
VAL_ 1157 Dms_MoutOpen 3 "Invalid" 2 "Closed" 1 "Open" 0 "Not Active" ;
VAL_ 1157 Dms_EyeOpen 3 "Invalid" 2 "Closed" 1 "Open" 0 "Not Active" ;
VAL_ 1157 Dms_EyeOccl 3 "Invalid" 2 "Occlusion" 1 "No Occlusion" 0 "Not Active" ;
VAL_ 1279 ICC_SentinelModeSts 3 "Reserved" 2 "ON" 1 "OFF" 0 "invalid" ;
VAL_ 1279 ICC_CameraErrorCode 3 "ErrorCode3" 2 "ErrorCode2" 1 "ErrorCode1" 0 "NoError" ;
VAL_ 1279 ICC_SentinelRequest 3 "OFF" 2 "ExitSentinelRequest" 1 "EnterSentinelRequest" 0 "Not Active" ;
VAL_ 1279 ICC_StartDeInitCameraStream 3 "Reserved" 2 "Reserved" 1 "ICC_StartDeInitCameraStream" 0 "Not Active" ;
VAL_ 1279 ICC_CameraRecoveryRequest 3 "Reserved" 2 "Reserved" 1 "ICC_StartRecovery" 0 "Not Active" ;
VAL_ 1265 OtaDwnLoad 3 "Reaserved" 2 "Reaserved" 1 "Req DwnLoad" 0 "Not Active" ;
VAL_ 1265 ICC_LightMainSwitchSts 7 "Reserved" 6 "Reserved" 5 "Reserved" 4 "LowBeamSwitch" 3 "PositionLampSwitch" 2 "Auto" 1 "Off" 0 "Not active" ;
VAL_ 1265 ICC_HeadlampHeightSts 7 "Not Used" 6 "Not Used" 5 "Not Used" 4 "Level 3" 3 "Level 2" 2 "Level 1" 1 "Level 0" 0 "Not active" ;
VAL_ 1497 ADASLightSwt 3 "Invalid" 2 "ON" 1 "OFF" 0 "Not Active" ;
VAL_ 1208 PPMID_1_HWSt 1 "Active" 0 "Not Active" ;
VAL_ 1208 PPMID_1_PPSt 1 "Active" 0 "Not Active" ;
VAL_ 1208 PPMID_1_PPMICounter 1 "Count is full" 0 "Count not full" ;
VAL_ 1208 PPMID_1_PPMISt 7 "Reserved" 6 "Reserved" 5 "Reserved" 4 "Reserved" 3 "External error" 2 "PPMI internal error" 1 "PPMI initialization" 0 "PPMI no error" ;
VAL_ 582 PDC_1_FOLDistance 251 "No object" 511 "Invalid" ;
VAL_ 582 PDC_1_FOLZoneStatus 15 "Reserved;" 14 "Reserved;" 13 "Reserved;" 12 "Reserved;" 11 "Reserved;" 10 "Reserved;" 9 "Reserved;" 8 "Reserved;" 7 "Reserved;" 6 "0 Hz 121 to 150 cm;" 5 "0 Hz 91 to 120 cm;" 4 "0 Hz 61 to 90 cm;" 3 "4 Hz 41 to 60 cm;" 2 "4 Hz 31 to 40 cm;" 1 "Continuous 0 to 30 cm;" 0 "No sound / Mute;" ;
VAL_ 582 PDC_1_FMLDistance 251 "No object" 511 "Invalid" ;
VAL_ 582 PDC_1_FMLZoneStatus 15 "Reserved;" 14 "Reserved;" 13 "Reserved;" 12 "Reserved;" 11 "Reserved;" 10 "Reserved;" 9 "Reserved;" 8 "Reserved;" 7 "Reserved;" 6 "0 Hz 121 to 150 cm;" 5 "0 Hz 91 to 120 cm;" 4 "0 Hz 61 to 90 cm;" 3 "4 Hz 41 to 60 cm;" 2 "4 Hz 31 to 40 cm;" 1 "Continuous 0 to 30 cm;" 0 "No sound / Mute;" ;
VAL_ 582 PDC_1_FMRDistance 251 "No object" 511 "Invalid" ;
VAL_ 582 PDC_1_FMRZoneStatus 15 "Reserved;" 14 "Reserved;" 13 "Reserved;" 12 "Reserved;" 11 "Reserved;" 10 "Reserved;" 9 "Reserved;" 8 "Reserved;" 7 "Reserved;" 6 "0 Hz 121 to 150 cm;" 5 "0 Hz 91 to 120 cm;" 4 "0 Hz 61 to 90 cm;" 3 "4 Hz 41 to 60 cm;" 2 "4 Hz 31 to 40 cm;" 1 "Continuous 0 to 30 cm;" 0 "No sound / Mute;" ;
VAL_ 582 PDC_1_FORDistance 251 "No object" 511 "Invalid" ;
VAL_ 582 PDC_1_FORZoneStatus 15 "Reserved;" 14 "Reserved;" 13 "Reserved;" 12 "Reserved;" 11 "Reserved;" 10 "Reserved;" 9 "Reserved;" 8 "Reserved;" 7 "Reserved;" 6 "0 Hz 121 to 150 cm;" 5 "0 Hz 91 to 120 cm;" 4 "0 Hz 61 to 90 cm;" 3 "4 Hz 41 to 60 cm;" 2 "4 Hz 31 to 40 cm;" 1 "Continuous 0 to 30 cm;" 0 "No sound / Mute;" ;
VAL_ 582 PDC_1_ROLDistance 251 "No object" 511 "Invalid" ;
VAL_ 582 PDC_1_ROLZoneStatus 15 "Reserved;" 14 "Reserved;" 13 "Reserved;" 12 "Reserved;" 11 "Reserved;" 10 "Reserved;" 9 "Reserved;" 8 "Reserved;" 7 "Reserved;" 6 "1 Hz 121 to 150 cm;" 5 "2 Hz 91 to 120 cm;" 4 "2 Hz 61 to 90 cm;" 3 "4 Hz 41 to 60 cm;" 2 "4 Hz 31 to 40 cm;" 1 "Continuous 0 to 30 cm;" 0 "No sound / Mute;" ;
VAL_ 582 PDC_1_RMLDistance 251 "No object" 511 "Invalid" ;
VAL_ 582 PDC_1_RMLZoneStatus 15 "Reserved;" 14 "Reserved;" 13 "Reserved;" 12 "Reserved;" 11 "Reserved;" 10 "Reserved;" 9 "Reserved;" 8 "Reserved;" 7 "Reserved;" 6 "1 Hz 121 to 150 cm;" 5 "2 Hz 91 to 120 cm;" 4 "2 Hz 61 to 90 cm;" 3 "4 Hz 41 to 60 cm;" 2 "4 Hz 31 to 40 cm;" 1 "Continuous 0 to 30 cm;" 0 "No sound / Mute;" ;
VAL_ 582 PDC_1_RMRDistance 251 "No object" 511 "Invalid" ;
VAL_ 582 PDC_1_RMRZoneStatus 15 "Reserved;" 14 "Reserved;" 13 "Reserved;" 12 "Reserved;" 11 "Reserved;" 10 "Reserved;" 9 "Reserved;" 8 "Reserved;" 7 "Reserved;" 6 "1 Hz 121 to 150 cm;" 5 "2 Hz 91 to 120 cm;" 4 "2 Hz 61 to 90 cm;" 3 "4 Hz 41 to 60 cm;" 2 "4 Hz 31 to 40 cm;" 1 "Continuous 0 to 30 cm;" 0 "No sound / Mute;" ;
VAL_ 582 PDC_1_RORDistance 251 "No object" 511 "Invalid" ;
VAL_ 582 PDC_1_RORZoneStatus 15 "Reserved;" 14 "Reserved;" 13 "Reserved;" 12 "Reserved;" 11 "Reserved;" 10 "Reserved;" 9 "Reserved;" 8 "Reserved;" 7 "Reserved;" 6 "1 Hz 121 to 150 cm;" 5 "2 Hz 91 to 120 cm;" 4 "2 Hz 61 to 90 cm;" 3 "4 Hz 41 to 60 cm;" 2 "4 Hz 31 to 40 cm;" 1 "Continuous 0 to 30 cm;" 0 "No sound / Mute;" ;
VAL_ 582 PDC_1_LSFDistance 251 "No object" 511 "Invalid" ;
VAL_ 582 PDC_1_LSFZoneStatus 15 "Reserved;" 14 "Reserved;" 13 "Reserved;" 12 "Reserved;" 11 "Reserved;" 10 "Reserved;" 9 "Reserved;" 8 "Reserved;" 7 "Reserved;" 6 "0 Hz 121 to 150 cm;" 5 "0 Hz 91 to 120 cm;" 4 "0 Hz 61 to 90 cm;" 3 "4 Hz 41 to 60 cm;" 2 "4 Hz 31 to 40 cm;" 1 "Continuous 0 to 30 cm;" 0 "No sound / Mute;" ;
VAL_ 582 PDC_1_FKPLSFMDistance 251 "No object" 511 "Invalid" ;
VAL_ 582 PDC_1_FKPLSFMZoneStatus 15 "Reserved;" 14 "Reserved;" 13 "Reserved;" 12 "Reserved;" 11 "Reserved;" 10 "Reserved;" 9 "Reserved;" 8 "Reserved;" 7 "Reserved;" 6 "Reserved;" 5 "Reserved;" 4 "Reserved;" 3 "4 Hz 41 to 60 cm;" 2 "4 Hz 31 to 40 cm;" 1 "Continuous 0 to 30 cm;" 0 "No sound / Mute;" ;
VAL_ 582 PDC_1_FKPLSRMDistance 251 "No object" 511 "Invalid" ;
VAL_ 582 PDC_1_FKPLSRMZoneStatus 15 "Reserved;" 14 "Reserved;" 13 "Reserved;" 12 "Reserved;" 11 "Reserved;" 10 "Reserved;" 9 "Reserved;" 8 "Reserved;" 7 "Reserved;" 6 "Reserved;" 5 "Reserved;" 4 "Reserved;" 3 "4 Hz 41 to 60 cm;" 2 "4 Hz 31 to 40 cm;" 1 "Continuous 0 to 30 cm;" 0 "No sound / Mute;" ;
VAL_ 582 PDC_1_LSRDistance 251 "No object" 511 "Invalid" ;
VAL_ 582 PDC_1_LSRZoneStatus 15 "Reserved;" 14 "Reserved;" 13 "Reserved;" 12 "Reserved;" 11 "Reserved;" 10 "Reserved;" 9 "Reserved;" 8 "Reserved;" 7 "Reserved;" 6 "0 Hz 121 to 150 cm;" 5 "0 Hz 91 to 120 cm;" 4 "0 Hz 61 to 90 cm;" 3 "4 Hz 41 to 60 cm;" 2 "4 Hz 31 to 40 cm;" 1 "Continuous 0 to 30 cm;" 0 "No sound / Mute;" ;
VAL_ 582 PDC_1_RSFDistance 251 "No object" 511 "Invalid" ;
VAL_ 582 PDC_1_RSFZoneStatus 15 "Reserved;" 14 "Reserved;" 13 "Reserved;" 12 "Reserved;" 11 "Reserved;" 10 "Reserved;" 9 "Reserved;" 8 "Reserved;" 7 "Reserved;" 6 "0 Hz 121 to 150 cm;" 5 "0 Hz 91 to 120 cm;" 4 "0 Hz 61 to 90 cm;" 3 "4 Hz 41 to 60 cm;" 2 "4 Hz 31 to 40 cm;" 1 "Continuous 0 to 30 cm;" 0 "No sound / Mute;" ;
VAL_ 582 PDC_1_FKPRSFMDistance 251 "No object" 511 "Invalid" ;
VAL_ 582 PDC_1_FKPRSFMZoneStatus 15 "Reserved;" 14 "Reserved;" 13 "Reserved;" 12 "Reserved;" 11 "Reserved;" 10 "Reserved;" 9 "Reserved;" 8 "Reserved;" 7 "Reserved;" 6 "Reserved;" 5 "Reserved;" 4 "Reserved;" 3 "4 Hz 41 to 60 cm;" 2 "4 Hz 31 to 40 cm;" 1 "Continuous 0 to 30 cm;" 0 "No sound / Mute;" ;
VAL_ 582 PDC_1_FKPRSRMDistance 251 "No object" 511 "Invalid" ;
VAL_ 582 PDC_1_FKPRSRMZoneStatus 15 "Reserved;" 14 "Reserved;" 13 "Reserved;" 12 "Reserved;" 11 "Reserved;" 10 "Reserved;" 9 "Reserved;" 8 "Reserved;" 7 "Reserved;" 6 "Reserved;" 5 "Reserved;" 4 "Reserved;" 3 "4 Hz 41 to 60 cm;" 2 "4 Hz 31 to 40 cm;" 1 "Continuous 0 to 30 cm;" 0 "No sound / Mute;" ;
VAL_ 582 PDC_1_RSRDistance 251 "No object" 511 "Invalid" ;
VAL_ 582 PDC_1_RSRZoneStatus 15 "Reserved;" 14 "Reserved;" 13 "Reserved;" 12 "Reserved;" 11 "Reserved;" 10 "Reserved;" 9 "Reserved;" 8 "Reserved;" 7 "Reserved;" 6 "0 Hz 121 to 150 cm;" 5 "0 Hz 91 to 120 cm;" 4 "0 Hz 61 to 90 cm;" 3 "4 Hz 41 to 60 cm;" 2 "4 Hz 31 to 40 cm;" 1 "Continuous 0 to 30 cm;" 0 "No sound / Mute;" ;
VAL_ 582 PDC_1_ParKASSStatus 7 "Invaild" 6 "Front Rear active Side failure" 5 "System failure" 4 "Front failure Rear active" 3 "Front active Rear failure" 2 "Active" 1 "Standby" 0 "Off" ;
VAL_ 582 PDC_1_PASTrailerHitchDetected 3 "Invalid" 2 "Unknown" 1 "Yes" 0 "No" ;
VAL_ 582 PDC_1_PDCSwFdbk 1 "disable" 0 "enable" ;
VAL_ 582 PDC_1_FrontWarningType 15 "Reserved" 14 "Reserved" 13 "Reserved" 12 "Reserved" 11 "Reserved" 10 "Reserved" 9 "Reserved" 8 "Reserved" 7 "Reserved" 6 "Buzzer ON at 1Hz" 5 "Buzzer ON at 2Hz" 4 "Buzzer ON at 2Hz" 3 "Buzzer ON at 4Hz" 2 "Buzzer ON at 4Hz" 1 "Buzzer ON" 0 "Buzzer OFF" ;
VAL_ 582 PDC_1_RearWarningType 15 "Reserved" 14 "Reserved" 13 "Reserved" 12 "Reserved" 11 "Reserved" 10 "Reserved" 9 "Reserved" 8 "Reserved" 7 "Reserved" 6 "Buzzer ON at 1Hz" 5 "Buzzer ON at 2Hz" 4 "Buzzer ON at 2Hz" 3 "Buzzer ON at 4Hz" 2 "Buzzer ON at 4Hz" 1 "Buzzer ON" 0 "Buzzer OFF" ;
VAL_ 582 PDC_1_LeftSideWarningType 15 "Reserved" 14 "Reserved" 13 "Reserved" 12 "Reserved" 11 "Reserved" 10 "Reserved" 9 "Reserved" 8 "Reserved" 7 "Reserved" 6 "Buzzer ON at 1Hz" 5 "Buzzer ON at 2Hz" 4 "Buzzer ON at 2Hz" 3 "Buzzer ON at 4Hz" 2 "Buzzer ON at 4Hz" 1 "Buzzer ON" 0 "Buzzer OFF" ;
VAL_ 582 PDC_1_RightSideWarningType 15 "Reserved" 14 "Reserved" 13 "Reserved" 12 "Reserved" 11 "Reserved" 10 "Reserved" 9 "Reserved" 8 "Reserved" 7 "Reserved" 6 "Buzzer ON at 1Hz" 5 "Buzzer ON at 2Hz" 4 "Buzzer ON at 2Hz" 3 "Buzzer ON at 4Hz" 2 "Buzzer ON at 4Hz" 1 "Buzzer ON" 0 "Buzzer OFF" ;
VAL_ 582 PDC_1_STATRearPDCActive 1 "active" 0 "inactive" ;
VAL_ 582 PDC_1_STATFrntPDCActive 1 "active" 0 "inactive" ;
VAL_ 582 PDC_1_STATSidePDCActive 1 "active" 0 "inactive" ;
VAL_ 582 PDC_1_STATPDCHMIMode 1 "Request" 0 "No request" ;
VAL_ 582 PDC_1_FrontPDCMuteFeedback 1 "ON" 0 "OFF" ;
VAL_ 582 PDC_1_FKPMuteFeedback 1 "ON" 0 "OFF" ;
VAL_ 582 PDC_1_TimeOutMuteRequest 1 "Request" 0 "No request" ;
VAL_ 1231 FuncReq_DepartureSdl 1 "Active" 0 "Not Active" ;
VAL_ 1231 AVP_FuncReq 1 "Request" 0 "No Request" ;
VAL_ 1231 FBLPowerHold 3 "Invalid" 2 "Reserved" 1 "Flashing the gear to keep the request signal valid" 0 "The request signal for flashing the gear position is invalid" ;
VAL_ 1199 TCM_1_TrailerSts 1 "Connect" 0 "Disconnect" ;
VAL_ 1207 WPump3Duty_FB 255 "Invalid" ;
VAL_ 1207 WPump3FltSt 9 "OverTempShutDown" 8 "OverTempReduction" 7 "BelowVol" 6 "OverVol" 5 "Dryrun" 4 "Communication error" 3 "Stall" 2 "Open circuit" 1 "Short circuit" 0 "Normal" ;
VAL_ 1035 VCC_1_CarMode 7 "Reserved" 6 "Transport Paused" 5 "Factory Paused" 4 "Crash Mode" 3 "Dyno Mode" 2 "Transport Mode" 1 "Factory Mode" 0 "Normal Mode" ;
VAL_ 1035 VCC_1_DriveMode 16 "Professional" 15 "Deep Snow" 14 "Deep Mud" 13 "Smart" 12 "Mud" 11 "Rock" 10 "Wade" 9 "AI" 8 "Sand" 7 "Energy-saving hybrid" 6 "Individual" 5 "Off Road" 4 "Snow" 3 "Sport" 2 "Normal" 1 "ECO" 0 "Not Active" ;
VAL_ 1075 VCC_2_ConfigurationMessageTrg 1 "active" 0 "not active" ;
VAL_ 1601 RMR_ADCC 1 "Active" 0 "Inactive" ;
VAL_ 1601 ADCC_Wakeup_Poweron 1 "Active" 0 "Inactive" ;
VAL_ 1601 ADCC_Wakeup_NM 1 "Active" 0 "Inactive" ;
VAL_ 1601 ADCC_Wakeup_Diag 1 "Active" 0 "Inactive" ;
VAL_ 1601 ADCC_Wakeup_KL15 1 "Active" 0 "Inactive" ;
VAL_ 1601 ADCC_Awake_Poweron 1 "Active" 0 "Inactive" ;
VAL_ 1601 ADCC_Awake_NM 1 "Active" 0 "Inactive" ;
VAL_ 1601 ADCC_Awake_Diag 1 "Active" 0 "Inactive" ;
VAL_ 1601 ADCC_Awake_Upload 1 "Active" 0 "Inactive" ;
VAL_ 1601 ADCC_Awake_KL15 1 "Active" 0 "Inactive" ;
VAL_ 1601 ADCC_Awake_Startup 1 "Active" 0 "Inactive" ;
VAL_ 1601 ADCC_Awake_DOWAfterRun 1 "Active" 0 "Inactive" ;
